VERSION ""

NS_ :

BS_:

BU_: TM

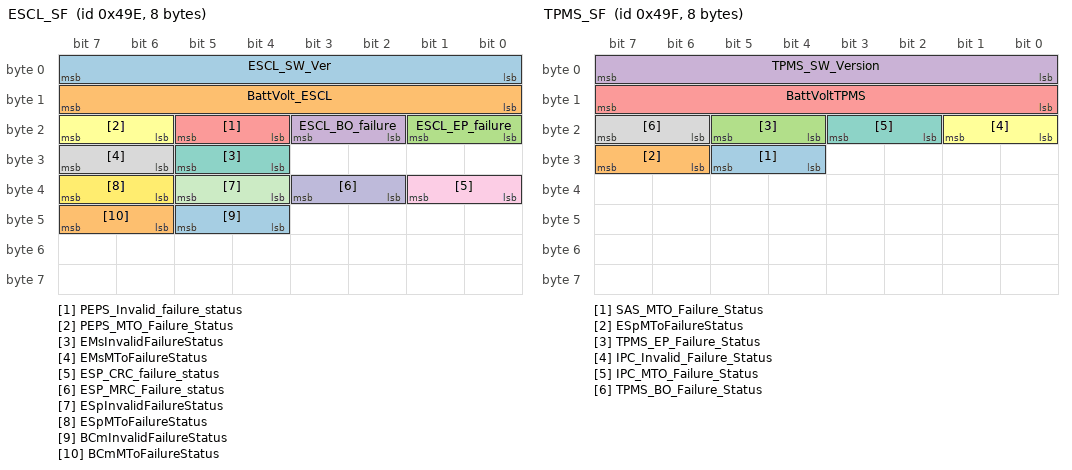
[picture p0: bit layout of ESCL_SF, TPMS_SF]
BO_ 1182 ESCL_SF: 8 Vector__XXX
 SG_ ESCL_SW_Ver : 7|8@0+ (1,0) [0|255] ""  TM
 SG_ BattVolt_ESCL : 15|8@0+ (0.1,0) [0|25] "Volts"  TM
 SG_ ESCL_EP_failure : 17|2@0+ (1,0) [0|3] ""  TM
 SG_ ESCL_BO_failure : 19|2@0+ (1,0) [0|3] ""  TM
 SG_ PEPS_Invalid_failure_status : 21|2@0+ (1,0) [0|3] ""  TM
 SG_ PEPS_MTO_Failure_Status : 23|2@0+ (1,0) [0|3] ""  TM
 SG_ EMsInvalidFailureStatus : 29|2@0+ (1,0) [0|3] ""  TM
 SG_ EMsMToFailureStatus : 31|2@0+ (1,0) [0|3] ""  TM
 SG_ ESP_CRC_failure_status : 33|2@0+ (1,0) [0|3] ""  TM
 SG_ ESP_MRC_Failure_status : 35|2@0+ (1,0) [0|3] ""  TM
 SG_ ESpInvalidFailureStatus : 37|2@0+ (1,0) [0|3] ""  TM
 SG_ ESpMToFailureStatus : 39|2@0+ (1,0) [0|3] ""  TM
 SG_ BCmInvalidFailureStatus : 45|2@0+ (1,0) [0|3] ""  TM
 SG_ BCmMToFailureStatus : 47|2@0+ (1,0) [0|3] ""  TM

BO_ 1183 TPMS_SF: 8 Vector__XXX
 SG_ SAS_MTO_Failure_Status : 29|2@0+ (1,0) [0|3] ""  TM
 SG_ ESpMToFailureStatus : 31|2@0+ (1,0) [0|3] ""  TM
 SG_ TPMS_EP_Failure_Status : 21|2@0+ (1,0) [0|3] ""  TM
 SG_ TPMS_SW_Version : 7|8@0+ (1,0) [0|255] ""  TM
 SG_ BattVoltTPMS : 15|8@0+ (0.1,0) [0|25.5] "Volts"  TM
 SG_ IPC_Invalid_Failure_Status : 17|2@0+ (1,0) [0|3] ""  TM
 SG_ IPC_MTO_Failure_Status : 19|2@0+ (1,0) [0|3] ""  TM
 SG_ TPMS_BO_Failure_Status : 23|2@0+ (1,0) [0|3] ""  TM

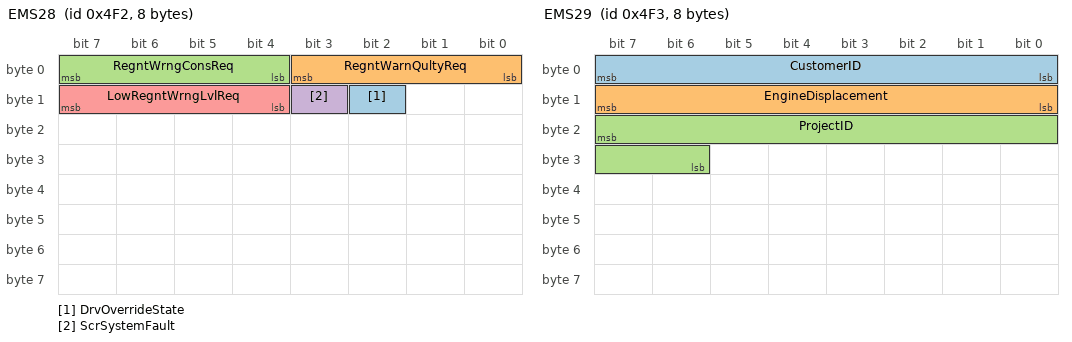
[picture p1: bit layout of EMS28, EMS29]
BO_ 1266 EMS28: 8 Vector__XXX
 SG_ DrvOverrideState : 10|1@0+ (1,0) [0|1] ""  TM
 SG_ RegntWarnQultyReq : 3|4@0+ (1,0) [0|15] ""  TM
 SG_ RegntWrngConsReq : 7|4@0+ (1,0) [0|15] ""  TM
 SG_ ScrSystemFault : 11|1@0+ (1,0) [0|1] ""  TM
 SG_ LowRegntWrngLvlReq : 15|4@0+ (1,0) [0|15] ""  TM

BO_ 1267 EMS29: 8 Vector__XXX
 SG_ CustomerID : 7|8@0+ (1,0) [0|255] ""  TM
 SG_ EngineDisplacement : 15|8@0+ (0.1,0) [0|25.5] ""  TM
 SG_ ProjectID : 23|10@0+ (0.01,0) [0|655.35] ""  TM

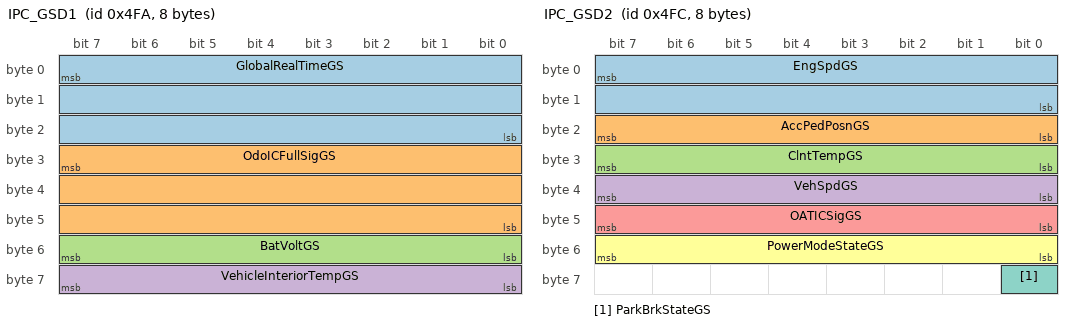
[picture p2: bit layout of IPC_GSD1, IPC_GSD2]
BO_ 1274 IPC_GSD1: 8 Vector__XXX
 SG_ GlobalRealTimeGS : 7|24@0+ (1,0) [0|16777214] "min"  TM
 SG_ OdoICFullSigGS : 31|24@0+ (1,0) [0|16777214] "km"  TM
 SG_ BatVoltGS : 55|8@0+ (0.1,0) [0|25.4] "V"  TM
 SG_ VehicleInteriorTempGS : 63|8@0+ (1,-40) [-40|214] "Deg"  TM

BO_ 1276 IPC_GSD2: 8 Vector__XXX
 SG_ EngSpdGS : 7|16@0+ (1,0) [0|65534] "rpm"  TM
 SG_ AccPedPosnGS : 23|8@0+ (0.5,0) [0|127] "%"  TM
 SG_ ClntTempGS : 31|8@0+ (1,-40) [-40|214] "Deg"  TM
 SG_ VehSpdGS : 39|8@0+ (1,0) [0|254] "km/h"  TM
 SG_ OATICSigGS : 47|8@0+ (1,-40) [-40|214] "Deg"  TM
 SG_ PowerModeStateGS : 55|8@0+ (1,0) [0|255] ""  TM
 SG_ ParkBrkStateGS : 56|1@0+ (1,0) [0|1] ""  TM

BO_ 1278 IPC_GSD3: 8 Vector__XXX
 SG_ VehIdetNumGS : 7|40@0+ (1,0) [0|0] ""  TM

BO_ 1280 BCM_NMPDU: 8 Vector__XXX
 SG_ BCM_NMPDU_SRC_ECU_ID : 7|8@0+ (1,0) [0|255] ""  TM
 SG_ RepeatMessageReq_BCM : 8|1@0+ (1,0) [0|1] ""  TM
 SG_ Reserved0 : 9|1@0+ (1,0) [0|1] ""  TM
 SG_ Reserved1 : 10|1@0+ (1,0) [0|1] ""  TM
 SG_ NMCoOrdSlpReady_BCM : 11|1@0+ (1,0) [0|1] ""  TM
 SG_ ActiveWakeUp_BCM : 12|1@0+ (1,0) [0|1] ""  TM
 SG_ Reserved2 : 13|1@0+ (1,0) [0|1] ""  TM
 SG_ PartialNetworkInformation_BCM : 14|1@0+ (1,0) [0|1] ""  TM
 SG_ Reserved3 : 15|1@0+ (1,0) [0|1] ""  TM
 SG_ CurrentState_BCM : 16|1@0+ (1,0) [0|1] ""  TM
 SG_ PreviousState_BCM : 19|3@0+ (1,0) [0|7] ""  TM
 SG_ Reserved4 : 20|1@0+ (1,0) [0|1] ""  TM
 SG_ Reserved5 : 21|1@0+ (1,0) [0|1] ""  TM
 SG_ Reserved6 : 22|1@0+ (1,0) [0|1] ""  TM
 SG_ Reserved7 : 23|1@0+ (1,0) [0|1] ""  TM
 SG_ BCM_NMPDU_USER_DATA_D1 : 31|8@0+ (1,0) [0|255] ""  TM
 SG_ BCM_NMPDU_USER_DATA_D2 : 39|8@0+ (1,0) [0|255] ""  TM
 SG_ BCM_NMPDU_USER_DATA_D3 : 47|8@0+ (1,0) [0|255] ""  TM
 SG_ BCM_NMPDU_USER_DATA_D4 : 55|8@0+ (1,0) [0|255] ""  TM
 SG_ BCM_NMPDU_USER_DATA_D5 : 63|8@0+ (1,0) [0|255] ""  TM

BO_ 1281 IPC_NMPDU: 8 Vector__XXX
 SG_ IPC_NMPDU_SRC_ECU_ID : 7|8@0+ (1,0) [0|255] ""  TM
 SG_ RepeatMessageReq_IPC : 8|1@0+ (1,0) [0|1] ""  TM
 SG_ Reserved24 : 9|1@0+ (1,0) [0|1] ""  TM
 SG_ Reserved25 : 10|1@0+ (1,0) [0|1] ""  TM
 SG_ NMCoOrdSlpReady_IPC : 11|1@0+ (1,0) [0|1] ""  TM
 SG_ ActiveWakeUp_IPC : 12|1@0+ (1,0) [0|1] ""  TM
 SG_ Reserved27 : 13|1@0+ (1,0) [0|1] ""  TM
 SG_ PartialNetworkInformation_IPC : 14|1@0+ (1,0) [0|1] ""  TM
 SG_ Reserved26 : 15|1@0+ (1,0) [0|1] ""  TM
 SG_ CurrentState_IPC : 16|1@0+ (1,0) [0|1] ""  TM
 SG_ PreviousState : 19|3@0+ (1,0) [0|7] ""  TM
 SG_ Reserved28 : 20|1@0+ (1,0) [0|1] ""  TM
 SG_ Reserved29 : 21|1@0+ (1,0) [0|1] ""  TM
 SG_ Reserved30 : 22|1@0+ (1,0) [0|1] ""  TM
 SG_ Reserved31 : 23|1@0+ (1,0) [0|1] ""  TM
 SG_ IPC_NMPDU_USER_DATA_1 : 31|8@0+ (1,0) [0|255] ""  TM
 SG_ IPC_NMPDU_USER_DATA_2 : 39|8@0+ (1,0) [0|255] ""  TM
 SG_ IPC_NMPDU_USER_DATA_3 : 47|8@0+ (1,0) [0|255] ""  TM
 SG_ IPC_NMPDU_USER_DATA_4 : 55|8@0+ (1,0) [0|255] ""  TM
 SG_ IPC_NMPDU_USER_DATA_5 : 63|8@0+ (1,0) [0|255] ""  TM

BO_ 1282 HU_NMPDU: 8 Vector__XXX
 SG_ HU_NMPDU_SRC_ECU_ID : 7|8@0+ (1,0) [0|255] ""  TM
 SG_ RepeatMessageReq_HU : 8|1@0+ (1,0) [0|1] ""  TM
 SG_ Reserved8 : 9|1@0+ (1,0) [0|1] ""  TM
 SG_ Reserved9 : 10|1@0+ (1,0) [0|1] ""  TM
 SG_ NMCoOrdSlpReady_HU : 11|1@0+ (1,0) [0|1] ""  TM
 SG_ ActiveWakeUp_HU : 12|1@0+ (1,0) [0|1] ""  TM
 SG_ Reserved10 : 13|1@0+ (1,0) [0|1] ""  TM
 SG_ PartialNetworkInformation_HU : 14|1@0+ (1,0) [0|1] ""  TM
 SG_ Reserved11 : 15|1@0+ (1,0) [0|1] ""  TM
 SG_ CurrentState_HU : 16|1@0+ (1,0) [0|1] ""  TM
 SG_ PreviousState_HU : 19|3@0+ (1,0) [0|7] ""  TM
 SG_ Reserved12 : 20|1@0+ (1,0) [0|1] ""  TM
 SG_ Reserved13 : 21|1@0+ (1,0) [0|1] ""  TM
 SG_ Reserved14 : 22|1@0+ (1,0) [0|1] ""  TM
 SG_ Reserved15 : 23|1@0+ (1,0) [0|1] ""  TM
 SG_ HU_NMPDU_USER_DATA_1 : 31|8@0+ (1,0) [0|255] ""  TM
 SG_ HU_NMPDU_USER_DATA_2 : 39|8@0+ (1,0) [0|255] ""  TM
 SG_ HU_NMPDU_USER_DATA_3 : 47|8@0+ (1,0) [0|255] ""  TM
 SG_ HU_NMPDU_USER_DATA_4 : 55|8@0+ (1,0) [0|255] ""  TM
 SG_ HU_NMPDU_USER_DATA_5 : 63|8@0+ (1,0) [0|255] ""  TM

BO_ 1285 GSS_NMPDU: 8 Vector__XXX
 SG_ GSS_NMPDU_SRC_ECU_ID : 7|8@0+ (1,0) [0|255] ""  TM
 SG_ RepeatMessageReq_GSS : 8|1@0+ (1,0) [0|1] ""  TM
 SG_ Reserved39 : 9|1@0+ (1,0) [0|1] ""  TM
 SG_ Reserved38 : 10|1@0+ (1,0) [0|1] ""  TM
 SG_ NMCoOrdSlpReady_GSS : 11|1@0+ (1,0) [0|1] ""  TM
 SG_ ActiveWakeUp_GSS : 12|1@0+ (1,0) [0|1] ""  TM
 SG_ Reserved37 : 13|1@0+ (1,0) [0|1] ""  TM
 SG_ PartialNetworkInformation_GSS : 14|1@0+ (1,0) [0|1] ""  TM
 SG_ Reserved36 : 15|1@0+ (1,0) [0|1] ""  TM
 SG_ CurrentState_GSS : 16|1@0+ (1,0) [0|1] ""  TM
 SG_ PreviousState_GSS : 19|3@0+ (1,0) [0|7] ""  TM
 SG_ Reserved35 : 20|1@0+ (1,0) [0|1] ""  TM
 SG_ Reserved34 : 21|1@0+ (1,0) [0|1] ""  TM
 SG_ Reserved33 : 22|1@0+ (1,0) [0|1] ""  TM
 SG_ Reserved32 : 23|1@0+ (1,0) [0|1] ""  TM
 SG_ GSS_NMPDU_USER_DATA_D1 : 31|8@0+ (1,0) [0|255] ""  TM
 SG_ GSS_NMPDU_USER_DATA_D2 : 39|8@0+ (1,0) [0|255] ""  TM
 SG_ GSS_NMPDU_USER_DATA_D3 : 47|8@0+ (1,0) [0|255] ""  TM
 SG_ GSS_NMPDU_USER_DATA_D4 : 55|8@0+ (1,0) [0|255] ""  TM
 SG_ GSS_NMPDU_USER_DATA_D5 : 63|8@0+ (1,0) [0|255] ""  TM

BO_ 1286 CCM_NMPDU: 8 Vector__XXX
 SG_ CCM_NMPDU_SRC_ECU_ID : 7|8@0+ (1,0) [0|255] ""  TM
 SG_ RepeatMessageReq_CCM : 8|1@0+ (1,0) [0|1] ""  TM
 SG_ Reserved16 : 9|1@0+ (1,0) [0|1] ""  TM
 SG_ Reserved17 : 10|1@0+ (1,0) [0|1] ""  TM
 SG_ NMCoOrdSlpReady_CCM : 11|1@0+ (1,0) [0|1] ""  TM
 SG_ ActiveWakeUp_CCM : 12|1@0+ (1,0) [0|1] ""  TM
 SG_ Reserved18 : 13|1@0+ (1,0) [0|1] ""  TM
 SG_ PartialNetworkInformation_CCM : 14|1@0+ (1,0) [0|1] ""  TM
 SG_ Reserved19 : 15|1@0+ (1,0) [0|1] ""  TM
 SG_ CurrentState_CCM : 16|1@0+ (1,0) [0|1] ""  TM
 SG_ PreviousState_CCM : 19|3@0+ (1,0) [0|7] ""  TM
 SG_ Reserved20 : 20|1@0+ (1,0) [0|1] ""  TM
 SG_ Reserved21 : 21|1@0+ (1,0) [0|1] ""  TM
 SG_ Reserved22 : 22|1@0+ (1,0) [0|1] ""  TM
 SG_ Reserved23 : 23|1@0+ (1,0) [0|1] ""  TM
 SG_ CCM_NMPDU_USER_DATA_1 : 31|8@0+ (1,0) [0|255] ""  TM
 SG_ CCM_NMPDU_USER_DATA_2 : 39|8@0+ (1,0) [0|255] ""  TM
 SG_ CCM_NMPDU_USER_DATA_3 : 47|8@0+ (1,0) [0|255] ""  TM
 SG_ CCM_NMPDU_USER_DATA_4 : 55|8@0+ (1,0) [0|255] ""  TM
 SG_ CCM_NMPDU_USER_DATA_5 : 63|8@0+ (1,0) [0|255] ""  TM

BO_ 1312 MANDO_SA_RX_0_MSG: 8 Vector__XXX
 SG_ MANDO_Steering_Analyzer_Rx0 : 7|64@0+ (1,0) [0|1.8446744074E+019] ""  TM

BO_ 1313 MANDO_SA_TX_0_MSG: 8 Vector__XXX
 SG_ MANDO_Steering_Analyzer_Tx0 : 7|64@0+ (1,0) [0|1.8446744074E+019] ""  TM

BO_ 1314 MANDO_SA_RX_1_MSG: 8 Vector__XXX
 SG_ MANDO_Steering_Analyzer_Rx1 : 7|64@0+ (1,0) [0|1.8446744074E+019] ""  TM

BO_ 1315 MANDO_SA_TX_1_MSG: 8 Vector__XXX
 SG_ MANDO_Steering_Analyzer_Tx1 : 7|64@0+ (1,0) [0|1.8446744074E+019] ""  TM

BO_ 1316 MANDO_SA_RX_2_MSG: 8 Vector__XXX
 SG_ MANDO_Steering_Analyzer_Rx2 : 7|64@0+ (1,0) [0|1.8446744074E+019] ""  TM

BO_ 1317 MANDO_SA_TX_2_MSG: 8 Vector__XXX
 SG_ MANDO_Steering_Analyzer_Tx2 : 7|64@0+ (1,0) [0|1.8446744074E+019] ""  TM

BO_ 1318 MANDO_SA_RX_3_MSG: 8 Vector__XXX
 SG_ MANDO_Steering_Analyzer_Rx3 : 7|64@0+ (1,0) [0|1.8446744074E+019] ""  TM

BO_ 1319 MANDO_SA_TX_3_MSG: 8 Vector__XXX
 SG_ MANDO_Steering_Analyzer_Tx3 : 7|64@0+ (1,0) [0|1.8446744074E+019] ""  TM

BO_ 1320 MANDO_SA_RX_4_MSG: 8 Vector__XXX
 SG_ MANDO_Steering_Analyzer_Rx4 : 7|64@0+ (1,0) [0|1.8446744074E+019] ""  TM

BO_ 1321 MANDO_SA_TX_4_MSG: 8 Vector__XXX
 SG_ MANDO_Steering_Analyzer_Tx4 : 7|64@0+ (1,0) [0|1.8446744074E+019] ""  TM

BO_ 1322 MANDO_TUNING_RX_MSG: 8 Vector__XXX
 SG_ MANDO_TUNING_RX : 7|64@0+ (1,0) [0|1.8446744074E+019] ""  TM

BO_ 1323 MANDO_TUNING_TX_MSG: 8 Vector__XXX
 SG_ MANDO_TUNING_TX : 7|64@0+ (1,0) [0|1.8446744074E+019] ""  TM

BO_ 1360 CCM_XCP_Tx: 8 Vector__XXX
 SG_ CCM_XCP_Tx : 7|64@0+ (1,0) [0|0] ""  TM

BO_ 1361 CCM_XCP_Rx: 8 Vector__XXX
 SG_ CCM_XCP_Rx : 7|64@0+ (1,0) [0|0] ""  TM

BO_ 1362 EPAS_XCP_RX_MSG: 8 Vector__XXX
 SG_ EPAS_XCP_RX : 7|64@0+ (1,0) [0|1.8446744074E+019] ""  TM

BO_ 1363 EPAS_XCP_TX_MSG: 8 Vector__XXX
 SG_ EPAS_XCP_TX : 7|64@0+ (1,0) [0|1.8446744074E+019] ""  TM

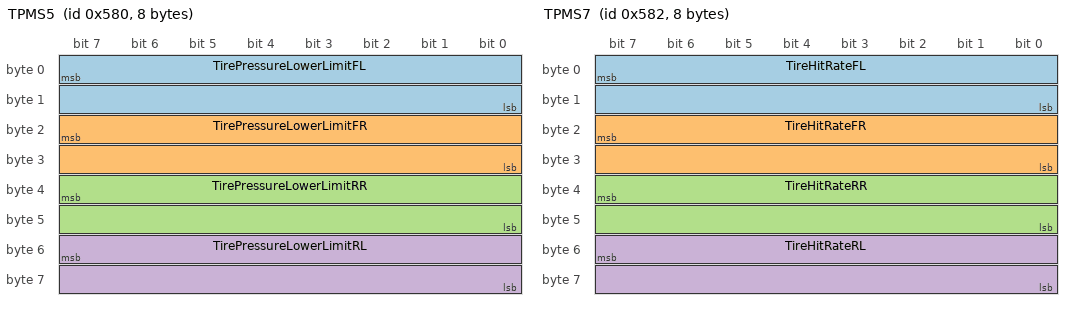
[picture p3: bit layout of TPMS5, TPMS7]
BO_ 1408 TPMS5: 8 Vector__XXX
 SG_ TirePressureLowerLimitFL : 7|16@0+ (0.01,0) [0|655.35] "Psi"  TM
 SG_ TirePressureLowerLimitFR : 23|16@0+ (0.01,0) [0|655.35] "Psi"  TM
 SG_ TirePressureLowerLimitRR : 39|16@0+ (0.01,0) [0|655.35] "Psi"  TM
 SG_ TirePressureLowerLimitRL : 55|16@0+ (0.01,0) [0|655.35] "Psi"  TM

BO_ 1409 TPMS6: 8 Vector__XXX
 SG_ TirePressureLowerLimitSpare : 7|16@0+ (0.01,0) [0|655.35] "Psi"  TM

BO_ 1410 TPMS7: 8 Vector__XXX
 SG_ TireHitRateFL : 7|16@0+ (1,0) [0|65535] "Count"  TM
 SG_ TireHitRateFR : 23|16@0+ (1,0) [0|65535] "Count"  TM
 SG_ TireHitRateRR : 39|16@0+ (1,0) [0|65535] "Count"  TM
 SG_ TireHitRateRL : 55|16@0+ (1,0) [0|65535] "Count"  TM

BO_ 1411 TPMS8: 8 Vector__XXX
 SG_ TireHitRateSpare : 7|16@0+ (1,0) [0|65535] "Count"  TM

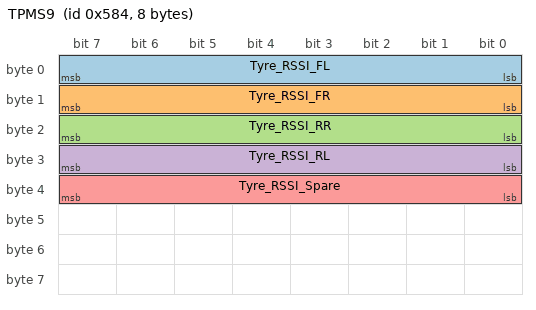
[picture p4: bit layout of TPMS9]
BO_ 1412 TPMS9: 8 Vector__XXX
 SG_ Tyre_RSSI_FL : 7|8@0+ (1,0) [0|255] "Count"  TM
 SG_ Tyre_RSSI_FR : 15|8@0+ (1,0) [0|255] "Count"  TM
 SG_ Tyre_RSSI_RR : 23|8@0+ (1,0) [0|255] "Count"  TM
 SG_ Tyre_RSSI_RL : 31|8@0+ (1,0) [0|255] "Count"  TM
 SG_ Tyre_RSSI_Spare : 39|8@0+ (1,0) [0|255] "Count"  TM

BO_ 1536 DebugOutput1: 8 Vector__XXX
 SG_ DebugOutput1 : 7|64@0+ (1,0) [0|0] ""  TM

BO_ 1537 DebugOutput2: 8 Vector__XXX
 SG_ DebugOutput2 : 7|64@0+ (1,0) [0|0] ""  TM

BO_ 1538 DebugOutput3: 8 Vector__XXX
 SG_ DebugOutput3 : 7|64@0+ (1,0) [0|0] ""  TM

BO_ 1539 DebugOutput4: 8 Vector__XXX
 SG_ DebugOutput4 : 7|64@0+ (1,0) [0|0] ""  TM

BO_ 1540 DebugOutput5: 8 Vector__XXX
 SG_ DebugOutput5 : 7|64@0+ (1,0) [0|0] ""  TM

BO_ 1541 DebugOutput6: 8 Vector__XXX
 SG_ DebugOutput6 : 7|64@0+ (1,0) [0|0] ""  TM

BO_ 1542 DebugOutput7: 8 Vector__XXX
 SG_ DebugOutput7 : 7|64@0+ (1,0) [0|0] ""  TM

BO_ 1543 DebugOutput8: 8 Vector__XXX
 SG_ DebugOutput8 : 7|64@0+ (1,0) [0|0] ""  TM

BO_ 1544 Debug_Input: 8 Vector__XXX
 SG_ DebugInput : 7|64@0+ (1,0) [0|0] ""  TM

BO_ 1545 BCM_DiagResponse_UUDT: 8 Vector__XXX
 SG_ BCM_DiagResponse_UUDT : 7|64@0+ (1,0) [0|0] ""  TM

BO_ 1546 SRS_DiagResponse_UUDT: 8 Vector__XXX
 SG_ SRS_DiagResponse_UUDT : 7|64@0+ (1,0) [0|0] ""  TM

BO_ 1547 HU_DiagResponse_UUDT: 8 Vector__XXX
 SG_ HU_DiagResponse_UUDT : 7|64@0+ (1,0) [0|0] ""  TM

BO_ 1548 VICM_DiagResponse_UUDT: 8 Vector__XXX
 SG_ VICM_DiagResponse_UUDT : 7|64@0+ (1,0) [0|0] ""  TM

BO_ 1549 CCM_DiagResponse_UUDT: 8 Vector__XXX
 SG_ CCM_DiagResponse_UUDT : 7|64@0+ (1,0) [0|0] ""  TM

BO_ 1560 PEPS_DiagResponse_UUDT: 8 Vector__XXX
 SG_ PEPS_DiagResponse_UUDT : 7|64@0+ (1,0) [0|0] ""  TM

BO_ 1564 PDC_DiagResponse_UUDT: 8 Vector__XXX
 SG_ PDC_DiagResponse_UUDT : 7|64@0+ (1,0) [0|0] ""  TM

BO_ 1624 ESP_DiagResponse_UUDT: 8 Vector__XXX
 SG_ ESP_DiagResponse_UUDT : 7|64@0+ (1,0) [0|0] ""  TM

BO_ 1626 EPAS_DiagResponse_UUDT: 8 Vector__XXX
 SG_ EPAS_DiagResponse_UUDT : 7|64@0+ (1,0) [0|0] ""  TM

BO_ 1669 DCS_DebugOutput1: 8 Vector__XXX
 SG_ DCS_DebugOutput1 : 7|64@0+ (1,0) [0|0] ""  TM

BO_ 1670 DCS_DebugInput: 8 Vector__XXX
 SG_ DCS_DebugInput : 7|64@0+ (1,0) [0|0] ""  TM

BO_ 1671 DCS_DebugOutput2: 8 Vector__XXX
 SG_ DCS_DebugOutput2 : 7|64@0+ (1,0) [0|0] ""  TM

BO_ 1768 EMS_DiagResponse_UUDT: 8 Vector__XXX
 SG_ EMS_DiagResponse_UUDT : 7|64@0+ (1,0) [0|0] ""  TM

BO_ 1769 TCM_DiagResponse_UUDT: 8 Vector__XXX
 SG_ AMT_DCT_DiagResponse_UUDT : 7|64@0+ (1,0) [0|0] ""  TM

BO_ 1793 BCM_DiagRequest: 8 Vector__XXX
 SG_ BCM_DiagRequest : 7|64@0+ (1,0) [0|0] ""  TM

BO_ 1794 SRS_DiagRequest: 8 Vector__XXX
 SG_ SRS_DiagRequest : 7|64@0+ (1,0) [0|0] ""  TM

BO_ 1795 HU_DiagRequest: 8 Vector__XXX
 SG_ DiagMsg : 7|8@0+ (1,0) [0|255] ""  TM

BO_ 1796 VICM_DiagRequest: 8 Vector__XXX
 SG_ VICM_DiagRequest : 7|64@0+ (1,0) [0|0] ""  TM

BO_ 1797 CCM_DiagRequest: 8 Vector__XXX
 SG_ CCM_DiagRequest : 7|64@0+ (1,0) [0|0] ""  TM

BO_ 1801 BCM_DiagResponse_USDT: 8 Vector__XXX
 SG_ BCM_DiagResponse_USDT : 7|64@0+ (1,0) [0|0] ""  TM

BO_ 1802 SRS_DiagResponse_USDT: 8 Vector__XXX
 SG_ SRS_DiagResponse_USDT : 7|64@0+ (1,0) [0|0] ""  TM

BO_ 1803 HU_DiagResponse_USDT: 8 Vector__XXX
 SG_ HU_DiagResponse_USDT : 7|64@0+ (1,0) [0|0] ""  TM

BO_ 1804 VICM_DiagResponse_USDT: 8 Vector__XXX
 SG_ VICM_DiagResponse_USDT : 7|64@0+ (1,0) [0|0] ""  TM

BO_ 1805 CCM_DiagResponse_USDT: 8 Vector__XXX
 SG_ CCM_DiagResponse_USDT : 7|64@0+ (1,0) [0|0] ""  TM

BO_ 1808 PEPS_DiagRequest_USDT: 8 Vector__XXX
 SG_ PEPS_DiagRequest_USDT : 7|64@0+ (1,0) [0|0] ""  TM

BO_ 1812 PDC_DiagRequest: 8 Vector__XXX
 SG_ PDC_DiagRequest : 7|64@0+ (1,0) [0|0] ""  TM

BO_ 1816 PEPS_DiagResponse_USDT: 8 Vector__XXX
 SG_ PEPS_DiagResponse_USDT : 7|64@0+ (1,0) [0|0] ""  TM

BO_ 1820 PDC_DiagResponse_USDT: 8 Vector__XXX
 SG_ PDC_DiagResponse_USDT : 7|64@0+ (1,0) [0|0] ""  TM

BO_ 1872 ESP_DiagRequest: 8 Vector__XXX
 SG_ ESP_DiagRequest : 7|64@0+ (1,0) [0|0] ""  TM

BO_ 1874 EPAS_DiagRequest: 8 Vector__XXX
 SG_ EPAS_DiagRequest : 7|64@0+ (1,0) [0|0] ""  TM

BO_ 1876 ESCL_DiagRequest: 8 Vector__XXX
 SG_ ESCL_DiagRequest : 7|64@0+ (1,0) [0|0] ""  TM

BO_ 1880 ESP_DiagResponse_USDT: 8 Vector__XXX
 SG_ ESP_DiagResponse_USDT : 7|64@0+ (1,0) [0|0] ""  TM

BO_ 1882 EPAS_DiagResponse_USDT: 8 Vector__XXX
 SG_ EPAS_DiagResponse_USDT : 7|64@0+ (1,0) [0|0] ""  TM

BO_ 1884 ESCL_DiagResponse_USDT: 8 Vector__XXX
 SG_ ESCL_DiagResponse_USDT : 7|64@0+ (1,0) [0|0] ""  TM

BO_ 2000 DiagState1: 8 Vector__XXX
 SG_ DiagMsg : 7|8@0+ (1,0) [0|255] ""  TM

BO_ 2001 DiagState2: 8 Vector__XXX
 SG_ DiagMsg : 7|8@0+ (1,0) [0|255] ""  TM

BO_ 2015 DiagState3: 8 Vector__XXX
 SG_ DiagMsg : 7|8@0+ (1,0) [0|255] ""  TM

BO_ 2016 EMS_DiagRequest: 8 Vector__XXX
 SG_ EMS_DiagRequest : 7|64@0+ (1,0) [0|0] ""  TM

BO_ 2017 TCM_DiagRequest: 8 Vector__XXX
 SG_ AMT_DCT_DiagRequest : 7|64@0+ (1,0) [0|0] ""  TM

BO_ 2024 EMS_DiagResponse_USDT: 8 Vector__XXX
 SG_ EMS_DiagResponse_USDT : 7|64@0+ (1,0) [0|0] ""  TM

BO_ 2025 TCM_DiagResponse_USDT: 8 Vector__XXX
 SG_ AMT_DCT_DiagResponse_USDT : 7|64@0+ (1,0) [0|0] ""  TM

CM_ SG_ 1182 BattVolt_ESCL "Battery voltage evaluated by ESCL";
CM_ SG_ 1182 PEPS_Invalid_failure_status "Status of the PEPS invalid failure detected as per Tata-IVN_Specification_Network_Management.";
CM_ SG_ 1182 PEPS_MTO_Failure_Status "Status of the PEPS  Message timeout  failure detected as per Tata-IVN_Specification_Network_Management.";
CM_ SG_ 1182 EMsInvalidFailureStatus "status of the EMS Invalid  signal  failure detected as per Tata-IVN_Specification_Network_Management.";
CM_ SG_ 1182 EMsMToFailureStatus "Status of the EMS message timeout failure detected as per Tata-IVN_Specification_Network_Management.";
CM_ SG_ 1182 ESpInvalidFailureStatus "Status of the ESP signal implausible  failure detected  by EPAS  as per  communication layer spec";
CM_ SG_ 1182 ESpMToFailureStatus "Status of the ESP  Message timeout failure detected as per Tata-IVN_Specification_Network_Management.";
CM_ SG_ 1182 BCmMToFailureStatus "Status of the BCM Message timeout  failure detected as per Tata-IVN_Specification_Network_Management.";
CM_ BO_ 1183 "SuperVision Frame";
CM_ SG_ 1183 SAS_MTO_Failure_Status "Status of the SAS  Message timeout  failure detected as per Tata-IVN_Specification_Network_Management.";
CM_ SG_ 1183 ESpMToFailureStatus "Status of the ESP  Message timeout failure detected as per Tata-IVN_Specification_Network_Management.";
CM_ SG_ 1183 TPMS_EP_Failure_Status "Status of the error-passive failure detected by BCM ECU as per Tata-IVN_Specification_Network_Management.  ";
CM_ SG_ 1183 TPMS_SW_Version "SW version of BCM ECU.  ";
CM_ SG_ 1183 BattVoltTPMS "Battery voltage evaluated by TPMS.";
CM_ SG_ 1183 IPC_Invalid_Failure_Status "Status of the IC Invalid  signal  failure detected as per Tata-IVN_Specification_Network_Management.";
CM_ SG_ 1183 IPC_MTO_Failure_Status "Status of the IPC Message Timeout  failure detected as per Tata-IVN_Specification_Network_Management.";
CM_ SG_ 1183 TPMS_BO_Failure_Status "Status of the bus-off failure detected by BCM ECU as per Tata-IVN_Specification_Network_Management.";
CM_ SG_ 1266 DrvOverrideState "this signal is set to Active only when the so-called OVERRIDE condition occurs";
CM_ SG_ 1266 RegntWarnQultyReq "CAN message is used to dispay text information qulity level of  reagent on IPC";
CM_ SG_ 1266 RegntWrngConsReq "CAN message is used to dispay text information excess consumption level of  reagent on IPC";
CM_ SG_ 1266 ScrSystemFault "CAN message used to understand status of SCR system";
CM_ SG_ 1266 LowRegntWrngLvlReq "CAN message is used to dispay text information Reagent level information";
CM_ SG_ 1267 CustomerID "if the TCU is connected to the correct EMS in the vehicle, the TCU will do a compatibility check in reference with Customer ID";
CM_ SG_ 1267 EngineDisplacement "if the TCU is connected to the correct EMS in the vehicle, the TCU will do a compatibility check in reference with Customer ID";
CM_ SG_ 1267 ProjectID "if the TCU is connected to the correct EMS in the vehicle, the TCU will do a compatibility check in reference with Project ID";
CM_ SG_ 1274 GlobalRealTimeGS "Global Real Time
";
CM_ SG_ 1274 OdoICFullSigGS "Total Distance Travelled";
CM_ SG_ 1274 BatVoltGS "Supply Voltage of Instrument Cluster";
CM_ SG_ 1274 VehicleInteriorTempGS "Vehicle Interior Temperature
";
CM_ SG_ 1276 EngSpdGS "Engine RPM signal will be transmitted by EMS
";
CM_ SG_ 1276 AccPedPosnGS "Throttle Position";
CM_ SG_ 1276 ClntTempGS "Engine Coolant Temperature";
CM_ SG_ 1276 VehSpdGS "Vehicle Speed";
CM_ SG_ 1276 OATICSigGS "Ambient Air Temperature";
CM_ SG_ 1276 PowerModeStateGS "Vehicle power mode signal shall be used by all ECUs of the vehicle for their respective functional implementation";
CM_ SG_ 1276 ParkBrkStateGS "Signal represents Status of ParkBrake";
CM_ SG_ 1278 VehIdetNumGS "Vehicle Identification Number - Last 5 digits of VIN";
CM_ BO_ 1360 "Calibration msg for HVAC";
CM_ SG_ 1360 CCM_XCP_Tx "CCM Calibration signal";
CM_ BO_ 1361 "Calibration msg for HVAC";
CM_ SG_ 1361 CCM_XCP_Rx "CCM Calibration signal";
CM_ BO_ 1408 "TPMS Test Msg";
CM_ SG_ 1408 TirePressureLowerLimitFL "Tire Pressure Lower Limit Front Left";
CM_ SG_ 1408 TirePressureLowerLimitFR "Tire Pressure Lower Limit Front Right";
CM_ SG_ 1408 TirePressureLowerLimitRR "Tire Pressure Lower Limit Rear Right";
CM_ SG_ 1408 TirePressureLowerLimitRL "Tire Pressure Lower Limit Rear Left";
CM_ BO_ 1409 "TPMS Test Msg";
CM_ SG_ 1409 TirePressureLowerLimitSpare "Tire Pressure Lower Limit Spare";
CM_ BO_ 1410 "TPMS Test Msg";
CM_ SG_ 1410 TireHitRateFL "Tire Hit Rate Front Left";
CM_ SG_ 1410 TireHitRateFR "Tire Hit Rate Front Right";
CM_ SG_ 1410 TireHitRateRR "Tire Hit Rate Rear Right";
CM_ SG_ 1410 TireHitRateRL "Tire Hit Rate Rear Left";
CM_ BO_ 1411 "TPMS Test Msg";
CM_ SG_ 1411 TireHitRateSpare "Tire Hit Rate Spare";
CM_ BO_ 1412 "TPMS Test Msg";
CM_ SG_ 1412 Tyre_RSSI_FL "Tire RSSI Level Front Left";
CM_ SG_ 1412 Tyre_RSSI_FR "'Tire RSSI Level Front Right";
CM_ SG_ 1412 Tyre_RSSI_RR "Tire RSSI Level Rear Right";
CM_ SG_ 1412 Tyre_RSSI_RL "Tire RSSI Level Rear Left";
CM_ SG_ 1412 Tyre_RSSI_Spare "Tire RSSI Level Spare";
CM_ BO_ 1669 "DCS Debug Output Message";
CM_ BO_ 1670 "DCS Debug Input";
CM_ BO_ 1671 "DCS Debug Output Message";
BA_DEF_ SG_  "Remarks" STRING ;
BA_DEF_ SG_  "NWM_WakeupAllowed" ENUM  "No","Yes";
BA_DEF_ SG_  "GenSigTimeoutTime_HU_Mid_X451" INT 0 65535;
BA_DEF_ SG_  "GenSigTimeoutTime_HU_High_X451" INT 0 65535;
BA_DEF_ SG_  "GenSigTimeoutTime_HU_B" INT 0 65535;
BA_DEF_ SG_  "GenSigTimeoutTime_HU_A" INT 0 65535;
BA_DEF_ SG_  "GenSigTimeoutTime_BCM_Mid" INT 0 65535;
BA_DEF_ SG_  "GenSigTimeoutMsg_HU_Mid_X451" INT 0 65535;
BA_DEF_ SG_  "GenSigTimeoutMsg_HU_High_X451" INT 0 65535;
BA_DEF_ SG_  "GenSigTimeoutMsg_HU_B" INT 0 65535;
BA_DEF_ SG_  "GenSigTimeoutMsg_HU_A" INT 0 65535;
BA_DEF_ SG_  "GenSigStartValue" INT 0 0;
BA_DEF_ SG_  "GenSigSendType" ENUM  "Cyclic","OnWrite","OnWriteWithRepetition","OnChange","OnChangeWithRepetition","IfActive","IfActiveWithRepetition","NoSigSendType","NotUsed","NotUsed","NotUsed","NotUsed","NotUsed";
BA_DEF_ SG_  "GenSigInactiveValue" INT 0 0;
BA_DEF_ SG_  "GenSigEnvVarType" ENUM  "int","float","undef";
BA_DEF_ SG_  "GenSigCycleTimeActive" INT 0 0;
BA_DEF_ SG_  "GenSigCycleTime" INT 0 0;
BA_DEF_ SG_  "GenSigTimeoutMsg_HU_High_X445" INT 0 65535;
BA_DEF_ SG_  "GenSigTimeoutMsg_HU_Mid_X445" INT 0 65535;
BA_DEF_ SG_  "GenSigTimeoutTime_HU_High_X445" INT 0 65535;
BA_DEF_ SG_  "GenSigTimeoutTime_HU_Mid_X445" INT 0 65535;
BA_DEF_ SG_  "GenSigTimeoutMsg_IVI" INT 0 65535;
BA_DEF_ SG_  "GenSigTimeoutTime_IVI" INT 0 65535;
BA_DEF_ BO_  "NmMessage" ENUM  "no","yes";
BA_DEF_ BO_  "NmAsrMessage" ENUM  "<n.a.>","No","Yes";
BA_DEF_ BO_  "MessageTimeout" INT 0 65535;
BA_DEF_ BO_  "Me" INT 0 0;
BA_DEF_ BO_  "GenMsgStartDelayTime" INT 0 0;
BA_DEF_ BO_  "GenMsgSendType" ENUM  "Cyclic","NotUsed","NotUsed","NotUsed","NotUsed","NotUsed","NotUsed","IfActive","NoMsgSendType","NotUsed";
BA_DEF_ BO_  "GenMsgNrOfRepetition" INT 0 0;
BA_DEF_ BO_  "GenMsgILSupport" ENUM  "No","Yes";
BA_DEF_ BO_  "GenMsgDelayTime" INT 0 0;
BA_DEF_ BO_  "GenMsgCycleTimeFast" INT 0 0;
BA_DEF_ BO_  "GenMsgCycleTime" INT 0 0;
BA_DEF_ BO_  "DiagUudtResponse" ENUM  "false","true";
BA_DEF_ BO_  "DiagUsdtResponse" ENUM  "false","true";
BA_DEF_ BO_  "DiagState" ENUM  "No","Yes";
BA_DEF_ BO_  "DiagResponse" ENUM  "No","Yes";
BA_DEF_ BO_  "DiagRequest" ENUM  "No","Yes";
BA_DEF_ BO_  "MsgType" ENUM  "Application","NM","NMH";
BA_DEF_ SG_  "SystemSignalLongSymbol" STRING ;
BA_DEF_DEF_  "Remarks" "null";
BA_DEF_DEF_  "NWM_WakeupAllowed" "No";
BA_DEF_DEF_  "GenSigTimeoutTime_HU_Mid_X451" 500;
BA_DEF_DEF_  "GenSigTimeoutTime_HU_High_X451" 500;
BA_DEF_DEF_  "GenSigTimeoutTime_HU_B" 500;
BA_DEF_DEF_  "GenSigTimeoutTime_HU_A" 500;
BA_DEF_DEF_  "GenSigTimeoutTime_BCM_Mid" 0;
BA_DEF_DEF_  "GenSigTimeoutMsg_HU_Mid_X451" 500;
BA_DEF_DEF_  "GenSigTimeoutMsg_HU_High_X451" 500;
BA_DEF_DEF_  "GenSigTimeoutMsg_HU_B" 500;
BA_DEF_DEF_  "GenSigTimeoutMsg_HU_A" 500;
BA_DEF_DEF_  "GenSigStartValue" 0;
BA_DEF_DEF_  "GenSigSendType" "Cyclic";
BA_DEF_DEF_  "GenSigInactiveValue" 0;
BA_DEF_DEF_  "GenSigEnvVarType" "undef";
BA_DEF_DEF_  "GenSigCycleTimeActive" 0;
BA_DEF_DEF_  "GenSigCycleTime" 0;
BA_DEF_DEF_  "GenSigTimeoutMsg_HU_High_X445" 500;
BA_DEF_DEF_  "GenSigTimeoutMsg_HU_Mid_X445" 500;
BA_DEF_DEF_  "GenSigTimeoutTime_HU_High_X445" 500;
BA_DEF_DEF_  "GenSigTimeoutTime_HU_Mid_X445" 500;
BA_DEF_DEF_  "GenSigTimeoutMsg_IVI" 500;
BA_DEF_DEF_  "GenSigTimeoutTime_IVI" 500;
BA_DEF_DEF_  "NmMessage" "no";
BA_DEF_DEF_  "NmAsrMessage" "<n.a.>";
BA_DEF_DEF_  "MessageTimeout" 500;
BA_DEF_DEF_  "Me" 0;
BA_DEF_DEF_  "GenMsgStartDelayTime" 0;
BA_DEF_DEF_  "GenMsgSendType" "Cyclic";
BA_DEF_DEF_  "GenMsgNrOfRepetition" 0;
BA_DEF_DEF_  "GenMsgILSupport" "Yes";
BA_DEF_DEF_  "GenMsgDelayTime" 0;
BA_DEF_DEF_  "GenMsgCycleTimeFast" 0;
BA_DEF_DEF_  "GenMsgCycleTime" 0;
BA_DEF_DEF_  "DiagUudtResponse" "false";
BA_DEF_DEF_  "DiagUsdtResponse" "false";
BA_DEF_DEF_  "DiagState" "No";
BA_DEF_DEF_  "DiagResponse" "No";
BA_DEF_DEF_  "DiagRequest" "No";
BA_DEF_DEF_  "MsgType" "Application";
BA_DEF_DEF_  "SystemSignalLongSymbol" "";
BA_ "MessageTimeout" BO_ 1182 0;
BA_ "GenMsgCycleTime" BO_ 1182 100;
BA_ "MessageTimeout" BO_ 1183 0;
BA_ "GenMsgCycleTime" BO_ 1183 100;
BA_ "MessageTimeout" BO_ 1266 5000;
BA_ "GenMsgCycleTime" BO_ 1266 1000;
BA_ "MessageTimeout" BO_ 1267 5000;
BA_ "GenMsgCycleTime" BO_ 1267 1000;
BA_ "MessageTimeout" BO_ 1274 5000;
BA_ "GenMsgCycleTime" BO_ 1274 1000;
BA_ "MessageTimeout" BO_ 1276 5000;
BA_ "GenMsgStartDelayTime" BO_ 1276 45;
BA_ "GenMsgCycleTime" BO_ 1276 1000;
BA_ "MessageTimeout" BO_ 1278 5000;
BA_ "GenMsgCycleTime" BO_ 1278 1000;
BA_ "NmAsrMessage" BO_ 1280 2;
BA_ "MessageTimeout" BO_ 1280 1000;
BA_ "GenMsgCycleTime" BO_ 1280 200;
BA_ "MessageTimeout" BO_ 1281 1000;
BA_ "GenMsgCycleTime" BO_ 1281 200;
BA_ "NmAsrMessage" BO_ 1282 2;
BA_ "MessageTimeout" BO_ 1282 1000;
BA_ "GenMsgCycleTime" BO_ 1282 200;
BA_ "MessageTimeout" BO_ 1285 1000;
BA_ "GenMsgCycleTime" BO_ 1285 200;
BA_ "MessageTimeout" BO_ 1286 1000;
BA_ "GenMsgCycleTime" BO_ 1286 200;
BA_ "MessageTimeout" BO_ 1312 0;
BA_ "GenMsgSendType" BO_ 1312 8;
BA_ "MessageTimeout" BO_ 1313 0;
BA_ "GenMsgSendType" BO_ 1313 8;
BA_ "MessageTimeout" BO_ 1314 0;
BA_ "GenMsgSendType" BO_ 1314 8;
BA_ "MessageTimeout" BO_ 1315 0;
BA_ "GenMsgSendType" BO_ 1315 8;
BA_ "MessageTimeout" BO_ 1316 0;
BA_ "GenMsgSendType" BO_ 1316 8;
BA_ "MessageTimeout" BO_ 1317 0;
BA_ "GenMsgSendType" BO_ 1317 8;
BA_ "MessageTimeout" BO_ 1318 0;
BA_ "GenMsgSendType" BO_ 1318 8;
BA_ "MessageTimeout" BO_ 1319 0;
BA_ "GenMsgSendType" BO_ 1319 8;
BA_ "MessageTimeout" BO_ 1320 0;
BA_ "GenMsgSendType" BO_ 1320 8;
BA_ "MessageTimeout" BO_ 1321 0;
BA_ "GenMsgSendType" BO_ 1321 8;
BA_ "MessageTimeout" BO_ 1322 0;
BA_ "GenMsgSendType" BO_ 1322 8;
BA_ "MessageTimeout" BO_ 1323 0;
BA_ "GenMsgSendType" BO_ 1323 8;
BA_ "MessageTimeout" BO_ 1360 0;
BA_ "GenMsgSendType" BO_ 1360 8;
BA_ "MessageTimeout" BO_ 1361 0;
BA_ "GenMsgSendType" BO_ 1361 8;
BA_ "MessageTimeout" BO_ 1362 0;
BA_ "GenMsgSendType" BO_ 1362 8;
BA_ "MessageTimeout" BO_ 1363 0;
BA_ "GenMsgSendType" BO_ 1363 8;
BA_ "GenMsgCycleTime" BO_ 1408 100;
BA_ "GenMsgCycleTime" BO_ 1409 100;
BA_ "GenMsgCycleTime" BO_ 1410 100;
BA_ "GenMsgCycleTime" BO_ 1411 100;
BA_ "GenMsgCycleTime" BO_ 1412 100;
BA_ "MessageTimeout" BO_ 1536 0;
BA_ "GenMsgSendType" BO_ 1536 8;
BA_ "GenMsgNrOfRepetition" BO_ 1536 1;
BA_ "MessageTimeout" BO_ 1537 0;
BA_ "GenMsgSendType" BO_ 1537 8;
BA_ "MessageTimeout" BO_ 1538 0;
BA_ "GenMsgSendType" BO_ 1538 8;
BA_ "MessageTimeout" BO_ 1539 0;
BA_ "GenMsgSendType" BO_ 1539 8;
BA_ "MessageTimeout" BO_ 1540 0;
BA_ "GenMsgSendType" BO_ 1540 8;
BA_ "MessageTimeout" BO_ 1541 0;
BA_ "GenMsgSendType" BO_ 1541 8;
BA_ "MessageTimeout" BO_ 1542 0;
BA_ "GenMsgSendType" BO_ 1542 8;
BA_ "MessageTimeout" BO_ 1543 0;
BA_ "GenMsgSendType" BO_ 1543 8;
BA_ "MessageTimeout" BO_ 1544 0;
BA_ "GenMsgSendType" BO_ 1544 8;
BA_ "MessageTimeout" BO_ 1545 0;
BA_ "GenMsgSendType" BO_ 1545 8;
BA_ "GenMsgILSupport" BO_ 1545 0;
BA_ "DiagResponse" BO_ 1545 1;
BA_ "MessageTimeout" BO_ 1546 0;
BA_ "GenMsgSendType" BO_ 1546 8;
BA_ "GenMsgILSupport" BO_ 1546 0;
BA_ "DiagResponse" BO_ 1546 1;
BA_ "MessageTimeout" BO_ 1547 0;
BA_ "GenMsgSendType" BO_ 1547 8;
BA_ "GenMsgILSupport" BO_ 1547 0;
BA_ "DiagUudtResponse" BO_ 1547 1;
BA_ "DiagResponse" BO_ 1547 1;
BA_ "MessageTimeout" BO_ 1548 0;
BA_ "GenMsgSendType" BO_ 1548 8;
BA_ "GenMsgILSupport" BO_ 1548 0;
BA_ "DiagResponse" BO_ 1548 1;
BA_ "MessageTimeout" BO_ 1549 0;
BA_ "GenMsgSendType" BO_ 1549 8;
BA_ "GenMsgILSupport" BO_ 1549 0;
BA_ "DiagResponse" BO_ 1549 1;
BA_ "MessageTimeout" BO_ 1560 0;
BA_ "GenMsgSendType" BO_ 1560 8;
BA_ "GenMsgILSupport" BO_ 1560 0;
BA_ "DiagResponse" BO_ 1560 1;
BA_ "MessageTimeout" BO_ 1564 0;
BA_ "GenMsgSendType" BO_ 1564 8;
BA_ "GenMsgILSupport" BO_ 1564 0;
BA_ "DiagResponse" BO_ 1564 1;
BA_ "MessageTimeout" BO_ 1624 0;
BA_ "GenMsgSendType" BO_ 1624 8;
BA_ "GenMsgILSupport" BO_ 1624 0;
BA_ "DiagResponse" BO_ 1624 1;
BA_ "MessageTimeout" BO_ 1626 0;
BA_ "GenMsgSendType" BO_ 1626 8;
BA_ "GenMsgILSupport" BO_ 1626 0;
BA_ "DiagResponse" BO_ 1626 1;
BA_ "MessageTimeout" BO_ 1669 0;
BA_ "GenMsgSendType" BO_ 1669 8;
BA_ "MessageTimeout" BO_ 1670 0;
BA_ "GenMsgSendType" BO_ 1670 8;
BA_ "MessageTimeout" BO_ 1671 0;
BA_ "GenMsgSendType" BO_ 1671 8;
BA_ "MessageTimeout" BO_ 1768 0;
BA_ "GenMsgSendType" BO_ 1768 8;
BA_ "GenMsgILSupport" BO_ 1768 0;
BA_ "DiagResponse" BO_ 1768 1;
BA_ "MessageTimeout" BO_ 1769 0;
BA_ "GenMsgSendType" BO_ 1769 8;
BA_ "GenMsgILSupport" BO_ 1769 0;
BA_ "DiagResponse" BO_ 1769 1;
BA_ "MessageTimeout" BO_ 1793 0;
BA_ "GenMsgSendType" BO_ 1793 8;
BA_ "GenMsgILSupport" BO_ 1793 0;
BA_ "DiagRequest" BO_ 1793 1;
BA_ "MessageTimeout" BO_ 1794 0;
BA_ "GenMsgSendType" BO_ 1794 8;
BA_ "GenMsgILSupport" BO_ 1794 0;
BA_ "DiagRequest" BO_ 1794 1;
BA_ "MessageTimeout" BO_ 1795 0;
BA_ "GenMsgSendType" BO_ 1795 8;
BA_ "GenMsgILSupport" BO_ 1795 0;
BA_ "DiagRequest" BO_ 1795 1;
BA_ "MessageTimeout" BO_ 1796 0;
BA_ "GenMsgSendType" BO_ 1796 8;
BA_ "GenMsgILSupport" BO_ 1796 0;
BA_ "DiagRequest" BO_ 1796 1;
BA_ "MessageTimeout" BO_ 1797 0;
BA_ "GenMsgSendType" BO_ 1797 8;
BA_ "GenMsgILSupport" BO_ 1797 0;
BA_ "DiagRequest" BO_ 1797 1;
BA_ "MessageTimeout" BO_ 1801 0;
BA_ "GenMsgSendType" BO_ 1801 8;
BA_ "GenMsgILSupport" BO_ 1801 0;
BA_ "DiagResponse" BO_ 1801 1;
BA_ "MessageTimeout" BO_ 1802 0;
BA_ "GenMsgSendType" BO_ 1802 8;
BA_ "GenMsgILSupport" BO_ 1802 0;
BA_ "DiagResponse" BO_ 1802 1;
BA_ "MessageTimeout" BO_ 1803 0;
BA_ "GenMsgSendType" BO_ 1803 8;
BA_ "GenMsgILSupport" BO_ 1803 0;
BA_ "DiagResponse" BO_ 1803 1;
BA_ "MessageTimeout" BO_ 1804 0;
BA_ "GenMsgSendType" BO_ 1804 8;
BA_ "GenMsgILSupport" BO_ 1804 0;
BA_ "DiagResponse" BO_ 1804 1;
BA_ "MessageTimeout" BO_ 1805 0;
BA_ "GenMsgSendType" BO_ 1805 8;
BA_ "GenMsgILSupport" BO_ 1805 0;
BA_ "DiagResponse" BO_ 1805 1;
BA_ "MessageTimeout" BO_ 1808 0;
BA_ "GenMsgSendType" BO_ 1808 8;
BA_ "GenMsgILSupport" BO_ 1808 0;
BA_ "DiagRequest" BO_ 1808 1;
BA_ "MessageTimeout" BO_ 1812 0;
BA_ "GenMsgSendType" BO_ 1812 8;
BA_ "GenMsgILSupport" BO_ 1812 0;
BA_ "DiagRequest" BO_ 1812 1;
BA_ "MessageTimeout" BO_ 1816 0;
BA_ "GenMsgSendType" BO_ 1816 8;
BA_ "GenMsgILSupport" BO_ 1816 0;
BA_ "DiagResponse" BO_ 1816 1;
BA_ "MessageTimeout" BO_ 1820 0;
BA_ "GenMsgSendType" BO_ 1820 8;
BA_ "GenMsgILSupport" BO_ 1820 0;
BA_ "DiagResponse" BO_ 1820 1;
BA_ "MessageTimeout" BO_ 1872 0;
BA_ "GenMsgSendType" BO_ 1872 8;
BA_ "GenMsgILSupport" BO_ 1872 0;
BA_ "DiagRequest" BO_ 1872 1;
BA_ "MessageTimeout" BO_ 1874 0;
BA_ "GenMsgSendType" BO_ 1874 8;
BA_ "GenMsgILSupport" BO_ 1874 0;
BA_ "DiagRequest" BO_ 1874 1;
BA_ "MessageTimeout" BO_ 1876 0;
BA_ "GenMsgSendType" BO_ 1876 8;
BA_ "GenMsgILSupport" BO_ 1876 0;
BA_ "DiagRequest" BO_ 1876 1;
BA_ "MessageTimeout" BO_ 1880 0;
BA_ "GenMsgSendType" BO_ 1880 8;
BA_ "GenMsgILSupport" BO_ 1880 0;
BA_ "DiagResponse" BO_ 1880 1;
BA_ "MessageTimeout" BO_ 1882 0;
BA_ "GenMsgSendType" BO_ 1882 8;
BA_ "GenMsgILSupport" BO_ 1882 0;
BA_ "DiagResponse" BO_ 1882 1;
BA_ "MessageTimeout" BO_ 1884 0;
BA_ "GenMsgSendType" BO_ 1884 8;
BA_ "GenMsgILSupport" BO_ 1884 0;
BA_ "DiagResponse" BO_ 1884 1;
BA_ "MessageTimeout" BO_ 2000 0;
BA_ "GenMsgSendType" BO_ 2000 8;
BA_ "GenMsgILSupport" BO_ 2000 0;
BA_ "DiagState" BO_ 2000 1;
BA_ "MessageTimeout" BO_ 2001 0;
BA_ "GenMsgSendType" BO_ 2001 8;
BA_ "GenMsgILSupport" BO_ 2001 0;
BA_ "DiagState" BO_ 2001 1;
BA_ "MessageTimeout" BO_ 2015 0;
BA_ "GenMsgSendType" BO_ 2015 8;
BA_ "GenMsgILSupport" BO_ 2015 0;
BA_ "DiagState" BO_ 2015 1;
BA_ "MessageTimeout" BO_ 2016 0;
BA_ "GenMsgSendType" BO_ 2016 8;
BA_ "GenMsgILSupport" BO_ 2016 0;
BA_ "DiagRequest" BO_ 2016 1;
BA_ "MessageTimeout" BO_ 2017 0;
BA_ "GenMsgSendType" BO_ 2017 8;
BA_ "GenMsgILSupport" BO_ 2017 0;
BA_ "DiagRequest" BO_ 2017 1;
BA_ "MessageTimeout" BO_ 2024 0;
BA_ "GenMsgSendType" BO_ 2024 8;
BA_ "GenMsgILSupport" BO_ 2024 0;
BA_ "DiagResponse" BO_ 2024 1;
BA_ "MessageTimeout" BO_ 2025 0;
BA_ "GenMsgSendType" BO_ 2025 8;
BA_ "GenMsgILSupport" BO_ 2025 0;
BA_ "DiagResponse" BO_ 2025 1;
BA_ "GenSigTimeoutTime_HU_B" SG_ 1182 ESCL_SW_Ver 0;
BA_ "GenSigTimeoutTime_HU_A" SG_ 1182 ESCL_SW_Ver 0;
BA_ "GenSigTimeoutMsg_HU_B" SG_ 1182 ESCL_SW_Ver 0;
BA_ "GenSigTimeoutMsg_HU_A" SG_ 1182 ESCL_SW_Ver 0;
BA_ "GenSigSendType" SG_ 1182 ESCL_SW_Ver 7;
BA_ "GenSigCycleTimeActive" SG_ 1182 ESCL_SW_Ver 100;
BA_ "GenSigCycleTime" SG_ 1182 ESCL_SW_Ver 100;
BA_ "GenSigTimeoutTime_HU_B" SG_ 1182 BattVolt_ESCL 0;
BA_ "GenSigTimeoutTime_HU_A" SG_ 1182 BattVolt_ESCL 0;
BA_ "GenSigTimeoutMsg_HU_B" SG_ 1182 BattVolt_ESCL 0;
BA_ "GenSigTimeoutMsg_HU_A" SG_ 1182 BattVolt_ESCL 0;
BA_ "GenSigSendType" SG_ 1182 BattVolt_ESCL 7;
BA_ "GenSigCycleTimeActive" SG_ 1182 BattVolt_ESCL 100;
BA_ "GenSigCycleTime" SG_ 1182 BattVolt_ESCL 100;
BA_ "GenSigTimeoutTime_HU_B" SG_ 1182 ESCL_EP_failure 0;
BA_ "GenSigTimeoutTime_HU_A" SG_ 1182 ESCL_EP_failure 0;
BA_ "GenSigTimeoutMsg_HU_B" SG_ 1182 ESCL_EP_failure 0;
BA_ "GenSigTimeoutMsg_HU_A" SG_ 1182 ESCL_EP_failure 0;
BA_ "GenSigSendType" SG_ 1182 ESCL_EP_failure 7;
BA_ "GenSigCycleTimeActive" SG_ 1182 ESCL_EP_failure 100;
BA_ "GenSigCycleTime" SG_ 1182 ESCL_EP_failure 100;
BA_ "GenSigTimeoutTime_HU_B" SG_ 1182 ESCL_BO_failure 0;
BA_ "GenSigTimeoutTime_HU_A" SG_ 1182 ESCL_BO_failure 0;
BA_ "GenSigTimeoutMsg_HU_B" SG_ 1182 ESCL_BO_failure 0;
BA_ "GenSigTimeoutMsg_HU_A" SG_ 1182 ESCL_BO_failure 0;
BA_ "GenSigSendType" SG_ 1182 ESCL_BO_failure 7;
BA_ "GenSigCycleTimeActive" SG_ 1182 ESCL_BO_failure 100;
BA_ "GenSigCycleTime" SG_ 1182 ESCL_BO_failure 100;
BA_ "GenSigTimeoutTime_HU_B" SG_ 1182 PEPS_Invalid_failure_status 0;
BA_ "GenSigTimeoutTime_HU_A" SG_ 1182 PEPS_Invalid_failure_status 0;
BA_ "GenSigTimeoutMsg_HU_B" SG_ 1182 PEPS_Invalid_failure_status 0;
BA_ "GenSigTimeoutMsg_HU_A" SG_ 1182 PEPS_Invalid_failure_status 0;
BA_ "GenSigSendType" SG_ 1182 PEPS_Invalid_failure_status 7;
BA_ "GenSigCycleTimeActive" SG_ 1182 PEPS_Invalid_failure_status 100;
BA_ "GenSigCycleTime" SG_ 1182 PEPS_Invalid_failure_status 100;
BA_ "GenSigTimeoutTime_HU_B" SG_ 1182 PEPS_MTO_Failure_Status 0;
BA_ "GenSigTimeoutTime_HU_A" SG_ 1182 PEPS_MTO_Failure_Status 0;
BA_ "GenSigTimeoutMsg_HU_B" SG_ 1182 PEPS_MTO_Failure_Status 0;
BA_ "GenSigTimeoutMsg_HU_A" SG_ 1182 PEPS_MTO_Failure_Status 0;
BA_ "GenSigSendType" SG_ 1182 PEPS_MTO_Failure_Status 7;
BA_ "GenSigCycleTimeActive" SG_ 1182 PEPS_MTO_Failure_Status 100;
BA_ "GenSigCycleTime" SG_ 1182 PEPS_MTO_Failure_Status 100;
BA_ "GenSigTimeoutTime_HU_B" SG_ 1182 EMsInvalidFailureStatus 0;
BA_ "GenSigTimeoutTime_HU_A" SG_ 1182 EMsInvalidFailureStatus 0;
BA_ "GenSigTimeoutMsg_HU_B" SG_ 1182 EMsInvalidFailureStatus 0;
BA_ "GenSigTimeoutMsg_HU_A" SG_ 1182 EMsInvalidFailureStatus 0;
BA_ "GenSigSendType" SG_ 1182 EMsInvalidFailureStatus 7;
BA_ "GenSigCycleTimeActive" SG_ 1182 EMsInvalidFailureStatus 100;
BA_ "GenSigCycleTime" SG_ 1182 EMsInvalidFailureStatus 100;
BA_ "GenSigTimeoutTime_HU_B" SG_ 1182 EMsMToFailureStatus 0;
BA_ "GenSigTimeoutTime_HU_A" SG_ 1182 EMsMToFailureStatus 0;
BA_ "GenSigTimeoutMsg_HU_B" SG_ 1182 EMsMToFailureStatus 0;
BA_ "GenSigTimeoutMsg_HU_A" SG_ 1182 EMsMToFailureStatus 0;
BA_ "GenSigSendType" SG_ 1182 EMsMToFailureStatus 7;
BA_ "GenSigCycleTimeActive" SG_ 1182 EMsMToFailureStatus 100;
BA_ "GenSigCycleTime" SG_ 1182 EMsMToFailureStatus 100;
BA_ "GenSigTimeoutTime_HU_B" SG_ 1182 ESP_CRC_failure_status 0;
BA_ "GenSigTimeoutTime_HU_A" SG_ 1182 ESP_CRC_failure_status 0;
BA_ "GenSigTimeoutMsg_HU_B" SG_ 1182 ESP_CRC_failure_status 0;
BA_ "GenSigTimeoutMsg_HU_A" SG_ 1182 ESP_CRC_failure_status 0;
BA_ "GenSigSendType" SG_ 1182 ESP_CRC_failure_status 7;
BA_ "GenSigCycleTimeActive" SG_ 1182 ESP_CRC_failure_status 100;
BA_ "GenSigCycleTime" SG_ 1182 ESP_CRC_failure_status 100;
BA_ "GenSigTimeoutTime_HU_B" SG_ 1182 ESP_MRC_Failure_status 0;
BA_ "GenSigTimeoutTime_HU_A" SG_ 1182 ESP_MRC_Failure_status 0;
BA_ "GenSigTimeoutMsg_HU_B" SG_ 1182 ESP_MRC_Failure_status 0;
BA_ "GenSigTimeoutMsg_HU_A" SG_ 1182 ESP_MRC_Failure_status 0;
BA_ "GenSigSendType" SG_ 1182 ESP_MRC_Failure_status 7;
BA_ "GenSigCycleTimeActive" SG_ 1182 ESP_MRC_Failure_status 100;
BA_ "GenSigCycleTime" SG_ 1182 ESP_MRC_Failure_status 100;
BA_ "GenSigTimeoutTime_HU_B" SG_ 1182 ESpInvalidFailureStatus 0;
BA_ "GenSigTimeoutTime_HU_A" SG_ 1182 ESpInvalidFailureStatus 0;
BA_ "GenSigTimeoutMsg_HU_B" SG_ 1182 ESpInvalidFailureStatus 0;
BA_ "GenSigTimeoutMsg_HU_A" SG_ 1182 ESpInvalidFailureStatus 0;
BA_ "GenSigSendType" SG_ 1182 ESpInvalidFailureStatus 7;
BA_ "GenSigCycleTimeActive" SG_ 1182 ESpInvalidFailureStatus 100;
BA_ "GenSigCycleTime" SG_ 1182 ESpInvalidFailureStatus 100;
BA_ "GenSigTimeoutTime_HU_B" SG_ 1182 ESpMToFailureStatus 0;
BA_ "GenSigTimeoutTime_HU_A" SG_ 1182 ESpMToFailureStatus 0;
BA_ "GenSigTimeoutMsg_HU_B" SG_ 1182 ESpMToFailureStatus 0;
BA_ "GenSigTimeoutMsg_HU_A" SG_ 1182 ESpMToFailureStatus 0;
BA_ "GenSigSendType" SG_ 1182 ESpMToFailureStatus 7;
BA_ "GenSigCycleTimeActive" SG_ 1182 ESpMToFailureStatus 100;
BA_ "GenSigCycleTime" SG_ 1182 ESpMToFailureStatus 100;
BA_ "GenSigTimeoutTime_HU_B" SG_ 1182 BCmInvalidFailureStatus 0;
BA_ "GenSigTimeoutTime_HU_A" SG_ 1182 BCmInvalidFailureStatus 0;
BA_ "GenSigTimeoutMsg_HU_B" SG_ 1182 BCmInvalidFailureStatus 0;
BA_ "GenSigTimeoutMsg_HU_A" SG_ 1182 BCmInvalidFailureStatus 0;
BA_ "GenSigSendType" SG_ 1182 BCmInvalidFailureStatus 7;
BA_ "GenSigCycleTimeActive" SG_ 1182 BCmInvalidFailureStatus 100;
BA_ "GenSigCycleTime" SG_ 1182 BCmInvalidFailureStatus 100;
BA_ "GenSigTimeoutTime_HU_B" SG_ 1182 BCmMToFailureStatus 0;
BA_ "GenSigTimeoutTime_HU_A" SG_ 1182 BCmMToFailureStatus 0;
BA_ "GenSigTimeoutMsg_HU_B" SG_ 1182 BCmMToFailureStatus 0;
BA_ "GenSigTimeoutMsg_HU_A" SG_ 1182 BCmMToFailureStatus 0;
BA_ "GenSigSendType" SG_ 1182 BCmMToFailureStatus 7;
BA_ "GenSigCycleTimeActive" SG_ 1182 BCmMToFailureStatus 100;
BA_ "GenSigCycleTime" SG_ 1182 BCmMToFailureStatus 100;
BA_ "GenSigTimeoutTime_HU_B" SG_ 1183 SAS_MTO_Failure_Status 0;
BA_ "GenSigTimeoutTime_HU_A" SG_ 1183 SAS_MTO_Failure_Status 0;
BA_ "GenSigTimeoutMsg_HU_B" SG_ 1183 SAS_MTO_Failure_Status 0;
BA_ "GenSigTimeoutMsg_HU_A" SG_ 1183 SAS_MTO_Failure_Status 0;
BA_ "GenSigSendType" SG_ 1183 SAS_MTO_Failure_Status 7;
BA_ "GenSigCycleTimeActive" SG_ 1183 SAS_MTO_Failure_Status 100;
BA_ "GenSigCycleTime" SG_ 1183 SAS_MTO_Failure_Status 100;
BA_ "GenSigTimeoutTime_HU_B" SG_ 1183 ESpMToFailureStatus 0;
BA_ "GenSigTimeoutTime_HU_A" SG_ 1183 ESpMToFailureStatus 0;
BA_ "GenSigTimeoutMsg_HU_B" SG_ 1183 ESpMToFailureStatus 0;
BA_ "GenSigTimeoutMsg_HU_A" SG_ 1183 ESpMToFailureStatus 0;
BA_ "GenSigSendType" SG_ 1183 ESpMToFailureStatus 7;
BA_ "GenSigCycleTimeActive" SG_ 1183 ESpMToFailureStatus 100;
BA_ "GenSigCycleTime" SG_ 1183 ESpMToFailureStatus 100;
BA_ "GenSigTimeoutTime_HU_B" SG_ 1183 TPMS_EP_Failure_Status 0;
BA_ "GenSigTimeoutTime_HU_A" SG_ 1183 TPMS_EP_Failure_Status 0;
BA_ "GenSigTimeoutMsg_HU_B" SG_ 1183 TPMS_EP_Failure_Status 0;
BA_ "GenSigTimeoutMsg_HU_A" SG_ 1183 TPMS_EP_Failure_Status 0;
BA_ "GenSigSendType" SG_ 1183 TPMS_EP_Failure_Status 7;
BA_ "GenSigCycleTimeActive" SG_ 1183 TPMS_EP_Failure_Status 100;
BA_ "GenSigCycleTime" SG_ 1183 TPMS_EP_Failure_Status 100;
BA_ "GenSigTimeoutTime_HU_B" SG_ 1183 TPMS_SW_Version 0;
BA_ "GenSigTimeoutTime_HU_A" SG_ 1183 TPMS_SW_Version 0;
BA_ "GenSigTimeoutMsg_HU_B" SG_ 1183 TPMS_SW_Version 0;
BA_ "GenSigTimeoutMsg_HU_A" SG_ 1183 TPMS_SW_Version 0;
BA_ "GenSigSendType" SG_ 1183 TPMS_SW_Version 7;
BA_ "GenSigCycleTimeActive" SG_ 1183 TPMS_SW_Version 100;
BA_ "GenSigCycleTime" SG_ 1183 TPMS_SW_Version 100;
BA_ "GenSigTimeoutTime_HU_B" SG_ 1183 BattVoltTPMS 0;
BA_ "GenSigTimeoutTime_HU_A" SG_ 1183 BattVoltTPMS 0;
BA_ "GenSigTimeoutMsg_HU_B" SG_ 1183 BattVoltTPMS 0;
BA_ "GenSigTimeoutMsg_HU_A" SG_ 1183 BattVoltTPMS 0;
BA_ "GenSigSendType" SG_ 1183 BattVoltTPMS 7;
BA_ "GenSigCycleTimeActive" SG_ 1183 BattVoltTPMS 100;
BA_ "GenSigCycleTime" SG_ 1183 BattVoltTPMS 100;
BA_ "GenSigTimeoutTime_HU_B" SG_ 1183 IPC_Invalid_Failure_Status 0;
BA_ "GenSigTimeoutTime_HU_A" SG_ 1183 IPC_Invalid_Failure_Status 0;
BA_ "GenSigTimeoutMsg_HU_B" SG_ 1183 IPC_Invalid_Failure_Status 0;
BA_ "GenSigTimeoutMsg_HU_A" SG_ 1183 IPC_Invalid_Failure_Status 0;
BA_ "GenSigSendType" SG_ 1183 IPC_Invalid_Failure_Status 7;
BA_ "GenSigCycleTimeActive" SG_ 1183 IPC_Invalid_Failure_Status 100;
BA_ "GenSigCycleTime" SG_ 1183 IPC_Invalid_Failure_Status 100;
BA_ "GenSigTimeoutTime_HU_B" SG_ 1183 IPC_MTO_Failure_Status 0;
BA_ "GenSigTimeoutTime_HU_A" SG_ 1183 IPC_MTO_Failure_Status 0;
BA_ "GenSigTimeoutMsg_HU_B" SG_ 1183 IPC_MTO_Failure_Status 0;
BA_ "GenSigTimeoutMsg_HU_A" SG_ 1183 IPC_MTO_Failure_Status 0;
BA_ "GenSigSendType" SG_ 1183 IPC_MTO_Failure_Status 7;
BA_ "GenSigCycleTimeActive" SG_ 1183 IPC_MTO_Failure_Status 100;
BA_ "GenSigCycleTime" SG_ 1183 IPC_MTO_Failure_Status 100;
BA_ "GenSigTimeoutTime_HU_B" SG_ 1183 TPMS_BO_Failure_Status 0;
BA_ "GenSigTimeoutTime_HU_A" SG_ 1183 TPMS_BO_Failure_Status 0;
BA_ "GenSigTimeoutMsg_HU_B" SG_ 1183 TPMS_BO_Failure_Status 0;
BA_ "GenSigTimeoutMsg_HU_A" SG_ 1183 TPMS_BO_Failure_Status 0;
BA_ "GenSigSendType" SG_ 1183 TPMS_BO_Failure_Status 7;
BA_ "GenSigCycleTimeActive" SG_ 1183 TPMS_BO_Failure_Status 100;
BA_ "GenSigCycleTime" SG_ 1183 TPMS_BO_Failure_Status 100;
BA_ "GenSigTimeoutTime_HU_Mid_X451" SG_ 1266 DrvOverrideState 5000;
BA_ "GenSigTimeoutTime_HU_High_X451" SG_ 1266 DrvOverrideState 5000;
BA_ "GenSigTimeoutTime_HU_B" SG_ 1266 DrvOverrideState 5000;
BA_ "GenSigTimeoutTime_HU_A" SG_ 1266 DrvOverrideState 5000;
BA_ "GenSigTimeoutMsg_HU_Mid_X451" SG_ 1266 DrvOverrideState 5000;
BA_ "GenSigTimeoutMsg_HU_High_X451" SG_ 1266 DrvOverrideState 5000;
BA_ "GenSigTimeoutMsg_HU_B" SG_ 1266 DrvOverrideState 5000;
BA_ "GenSigTimeoutMsg_HU_A" SG_ 1266 DrvOverrideState 5000;
BA_ "GenSigSendType" SG_ 1266 DrvOverrideState 7;
BA_ "GenSigCycleTimeActive" SG_ 1266 DrvOverrideState 1000;
BA_ "GenSigCycleTime" SG_ 1266 DrvOverrideState 1000;
BA_ "GenSigTimeoutMsg_HU_High_X445" SG_ 1266 DrvOverrideState 5000;
BA_ "GenSigTimeoutMsg_HU_Mid_X445" SG_ 1266 DrvOverrideState 5000;
BA_ "GenSigTimeoutTime_HU_High_X445" SG_ 1266 DrvOverrideState 5000;
BA_ "GenSigTimeoutTime_HU_Mid_X445" SG_ 1266 DrvOverrideState 5000;
BA_ "GenSigTimeoutMsg_IVI" SG_ 1266 DrvOverrideState 5000;
BA_ "GenSigTimeoutTime_IVI" SG_ 1266 DrvOverrideState 5000;
BA_ "GenSigTimeoutTime_HU_Mid_X451" SG_ 1266 RegntWarnQultyReq 5000;
BA_ "GenSigTimeoutTime_HU_High_X451" SG_ 1266 RegntWarnQultyReq 5000;
BA_ "GenSigTimeoutTime_HU_B" SG_ 1266 RegntWarnQultyReq 5000;
BA_ "GenSigTimeoutTime_HU_A" SG_ 1266 RegntWarnQultyReq 5000;
BA_ "GenSigTimeoutMsg_HU_Mid_X451" SG_ 1266 RegntWarnQultyReq 5000;
BA_ "GenSigTimeoutMsg_HU_High_X451" SG_ 1266 RegntWarnQultyReq 5000;
BA_ "GenSigTimeoutMsg_HU_B" SG_ 1266 RegntWarnQultyReq 5000;
BA_ "GenSigTimeoutMsg_HU_A" SG_ 1266 RegntWarnQultyReq 5000;
BA_ "GenSigStartValue" SG_ 1266 RegntWarnQultyReq 15;
BA_ "GenSigSendType" SG_ 1266 RegntWarnQultyReq 7;
BA_ "GenSigCycleTimeActive" SG_ 1266 RegntWarnQultyReq 1000;
BA_ "GenSigCycleTime" SG_ 1266 RegntWarnQultyReq 1000;
BA_ "GenSigTimeoutMsg_HU_High_X445" SG_ 1266 RegntWarnQultyReq 5000;
BA_ "GenSigTimeoutMsg_HU_Mid_X445" SG_ 1266 RegntWarnQultyReq 5000;
BA_ "GenSigTimeoutTime_HU_High_X445" SG_ 1266 RegntWarnQultyReq 5000;
BA_ "GenSigTimeoutTime_HU_Mid_X445" SG_ 1266 RegntWarnQultyReq 5000;
BA_ "GenSigTimeoutMsg_IVI" SG_ 1266 RegntWarnQultyReq 5000;
BA_ "GenSigTimeoutTime_IVI" SG_ 1266 RegntWarnQultyReq 5000;
BA_ "GenSigTimeoutTime_HU_Mid_X451" SG_ 1266 RegntWrngConsReq 5000;
BA_ "GenSigTimeoutTime_HU_High_X451" SG_ 1266 RegntWrngConsReq 5000;
BA_ "GenSigTimeoutTime_HU_B" SG_ 1266 RegntWrngConsReq 5000;
BA_ "GenSigTimeoutTime_HU_A" SG_ 1266 RegntWrngConsReq 5000;
BA_ "GenSigTimeoutMsg_HU_Mid_X451" SG_ 1266 RegntWrngConsReq 5000;
BA_ "GenSigTimeoutMsg_HU_High_X451" SG_ 1266 RegntWrngConsReq 5000;
BA_ "GenSigTimeoutMsg_HU_B" SG_ 1266 RegntWrngConsReq 5000;
BA_ "GenSigTimeoutMsg_HU_A" SG_ 1266 RegntWrngConsReq 5000;
BA_ "GenSigStartValue" SG_ 1266 RegntWrngConsReq 15;
BA_ "GenSigSendType" SG_ 1266 RegntWrngConsReq 7;
BA_ "GenSigCycleTimeActive" SG_ 1266 RegntWrngConsReq 1000;
BA_ "GenSigCycleTime" SG_ 1266 RegntWrngConsReq 1000;
BA_ "GenSigTimeoutMsg_HU_High_X445" SG_ 1266 RegntWrngConsReq 5000;
BA_ "GenSigTimeoutMsg_HU_Mid_X445" SG_ 1266 RegntWrngConsReq 5000;
BA_ "GenSigTimeoutTime_HU_High_X445" SG_ 1266 RegntWrngConsReq 5000;
BA_ "GenSigTimeoutTime_HU_Mid_X445" SG_ 1266 RegntWrngConsReq 5000;
BA_ "GenSigTimeoutMsg_IVI" SG_ 1266 RegntWrngConsReq 5000;
BA_ "GenSigTimeoutTime_IVI" SG_ 1266 RegntWrngConsReq 5000;
BA_ "GenSigTimeoutTime_HU_Mid_X451" SG_ 1266 ScrSystemFault 5000;
BA_ "GenSigTimeoutTime_HU_High_X451" SG_ 1266 ScrSystemFault 5000;
BA_ "GenSigTimeoutTime_HU_B" SG_ 1266 ScrSystemFault 5000;
BA_ "GenSigTimeoutTime_HU_A" SG_ 1266 ScrSystemFault 5000;
BA_ "GenSigTimeoutMsg_HU_Mid_X451" SG_ 1266 ScrSystemFault 5000;
BA_ "GenSigTimeoutMsg_HU_High_X451" SG_ 1266 ScrSystemFault 5000;
BA_ "GenSigTimeoutMsg_HU_B" SG_ 1266 ScrSystemFault 5000;
BA_ "GenSigTimeoutMsg_HU_A" SG_ 1266 ScrSystemFault 5000;
BA_ "GenSigSendType" SG_ 1266 ScrSystemFault 7;
BA_ "GenSigCycleTimeActive" SG_ 1266 ScrSystemFault 1000;
BA_ "GenSigCycleTime" SG_ 1266 ScrSystemFault 1000;
BA_ "GenSigTimeoutMsg_HU_High_X445" SG_ 1266 ScrSystemFault 5000;
BA_ "GenSigTimeoutMsg_HU_Mid_X445" SG_ 1266 ScrSystemFault 5000;
BA_ "GenSigTimeoutTime_HU_High_X445" SG_ 1266 ScrSystemFault 5000;
BA_ "GenSigTimeoutTime_HU_Mid_X445" SG_ 1266 ScrSystemFault 5000;
BA_ "GenSigTimeoutMsg_IVI" SG_ 1266 ScrSystemFault 5000;
BA_ "GenSigTimeoutTime_IVI" SG_ 1266 ScrSystemFault 5000;
BA_ "GenSigTimeoutTime_HU_Mid_X451" SG_ 1266 LowRegntWrngLvlReq 5000;
BA_ "GenSigTimeoutTime_HU_High_X451" SG_ 1266 LowRegntWrngLvlReq 5000;
BA_ "GenSigTimeoutTime_HU_B" SG_ 1266 LowRegntWrngLvlReq 5000;
BA_ "GenSigTimeoutTime_HU_A" SG_ 1266 LowRegntWrngLvlReq 5000;
BA_ "GenSigTimeoutMsg_HU_Mid_X451" SG_ 1266 LowRegntWrngLvlReq 5000;
BA_ "GenSigTimeoutMsg_HU_High_X451" SG_ 1266 LowRegntWrngLvlReq 5000;
BA_ "GenSigTimeoutMsg_HU_B" SG_ 1266 LowRegntWrngLvlReq 5000;
BA_ "GenSigTimeoutMsg_HU_A" SG_ 1266 LowRegntWrngLvlReq 5000;
BA_ "GenSigStartValue" SG_ 1266 LowRegntWrngLvlReq 15;
BA_ "GenSigSendType" SG_ 1266 LowRegntWrngLvlReq 7;
BA_ "GenSigCycleTimeActive" SG_ 1266 LowRegntWrngLvlReq 1000;
BA_ "GenSigCycleTime" SG_ 1266 LowRegntWrngLvlReq 1000;
BA_ "GenSigTimeoutMsg_HU_High_X445" SG_ 1266 LowRegntWrngLvlReq 5000;
BA_ "GenSigTimeoutMsg_HU_Mid_X445" SG_ 1266 LowRegntWrngLvlReq 5000;
BA_ "GenSigTimeoutTime_HU_High_X445" SG_ 1266 LowRegntWrngLvlReq 5000;
BA_ "GenSigTimeoutTime_HU_Mid_X445" SG_ 1266 LowRegntWrngLvlReq 5000;
BA_ "GenSigTimeoutMsg_IVI" SG_ 1266 LowRegntWrngLvlReq 5000;
BA_ "GenSigTimeoutTime_IVI" SG_ 1266 LowRegntWrngLvlReq 5000;
BA_ "GenSigTimeoutTime_HU_Mid_X451" SG_ 1267 CustomerID 5000;
BA_ "GenSigTimeoutTime_HU_High_X451" SG_ 1267 CustomerID 5000;
BA_ "GenSigTimeoutTime_HU_B" SG_ 1267 CustomerID 5000;
BA_ "GenSigTimeoutTime_HU_A" SG_ 1267 CustomerID 5000;
BA_ "GenSigTimeoutMsg_HU_Mid_X451" SG_ 1267 CustomerID 5000;
BA_ "GenSigTimeoutMsg_HU_High_X451" SG_ 1267 CustomerID 5000;
BA_ "GenSigTimeoutMsg_HU_B" SG_ 1267 CustomerID 5000;
BA_ "GenSigTimeoutMsg_HU_A" SG_ 1267 CustomerID 5000;
BA_ "GenSigSendType" SG_ 1267 CustomerID 7;
BA_ "GenSigCycleTimeActive" SG_ 1267 CustomerID 1000;
BA_ "GenSigCycleTime" SG_ 1267 CustomerID 1000;
BA_ "GenSigTimeoutTime_HU_Mid_X451" SG_ 1267 EngineDisplacement 5000;
BA_ "GenSigTimeoutTime_HU_High_X451" SG_ 1267 EngineDisplacement 5000;
BA_ "GenSigTimeoutTime_HU_B" SG_ 1267 EngineDisplacement 5000;
BA_ "GenSigTimeoutTime_HU_A" SG_ 1267 EngineDisplacement 5000;
BA_ "GenSigTimeoutMsg_HU_Mid_X451" SG_ 1267 EngineDisplacement 5000;
BA_ "GenSigTimeoutMsg_HU_High_X451" SG_ 1267 EngineDisplacement 5000;
BA_ "GenSigTimeoutMsg_HU_B" SG_ 1267 EngineDisplacement 5000;
BA_ "GenSigTimeoutMsg_HU_A" SG_ 1267 EngineDisplacement 5000;
BA_ "GenSigSendType" SG_ 1267 EngineDisplacement 7;
BA_ "GenSigCycleTimeActive" SG_ 1267 EngineDisplacement 1000;
BA_ "GenSigCycleTime" SG_ 1267 EngineDisplacement 1000;
BA_ "GenSigTimeoutTime_HU_Mid_X451" SG_ 1267 ProjectID 5000;
BA_ "GenSigTimeoutTime_HU_High_X451" SG_ 1267 ProjectID 5000;
BA_ "GenSigTimeoutTime_HU_B" SG_ 1267 ProjectID 5000;
BA_ "GenSigTimeoutTime_HU_A" SG_ 1267 ProjectID 5000;
BA_ "GenSigTimeoutMsg_HU_Mid_X451" SG_ 1267 ProjectID 5000;
BA_ "GenSigTimeoutMsg_HU_High_X451" SG_ 1267 ProjectID 5000;
BA_ "GenSigTimeoutMsg_HU_B" SG_ 1267 ProjectID 5000;
BA_ "GenSigTimeoutMsg_HU_A" SG_ 1267 ProjectID 5000;
BA_ "GenSigSendType" SG_ 1267 ProjectID 7;
BA_ "GenSigCycleTimeActive" SG_ 1267 ProjectID 1000;
BA_ "GenSigCycleTime" SG_ 1267 ProjectID 1000;
BA_ "GenSigTimeoutTime_HU_Mid_X451" SG_ 1274 GlobalRealTimeGS 5000;
BA_ "GenSigTimeoutTime_HU_High_X451" SG_ 1274 GlobalRealTimeGS 5000;
BA_ "GenSigTimeoutTime_HU_B" SG_ 1274 GlobalRealTimeGS 5000;
BA_ "GenSigTimeoutTime_HU_A" SG_ 1274 GlobalRealTimeGS 5000;
BA_ "GenSigTimeoutMsg_HU_Mid_X451" SG_ 1274 GlobalRealTimeGS 5000;
BA_ "GenSigTimeoutMsg_HU_High_X451" SG_ 1274 GlobalRealTimeGS 5000;
BA_ "GenSigTimeoutMsg_HU_B" SG_ 1274 GlobalRealTimeGS 5000;
BA_ "GenSigTimeoutMsg_HU_A" SG_ 1274 GlobalRealTimeGS 5000;
BA_ "GenSigSendType" SG_ 1274 GlobalRealTimeGS 7;
BA_ "GenSigCycleTimeActive" SG_ 1274 GlobalRealTimeGS 1000;
BA_ "GenSigCycleTime" SG_ 1274 GlobalRealTimeGS 1000;
BA_ "GenSigTimeoutMsg_HU_High_X445" SG_ 1274 GlobalRealTimeGS 5000;
BA_ "GenSigTimeoutMsg_HU_Mid_X445" SG_ 1274 GlobalRealTimeGS 5000;
BA_ "GenSigTimeoutTime_HU_High_X445" SG_ 1274 GlobalRealTimeGS 5000;
BA_ "GenSigTimeoutTime_HU_Mid_X445" SG_ 1274 GlobalRealTimeGS 5000;
BA_ "GenSigTimeoutMsg_IVI" SG_ 1274 GlobalRealTimeGS 5000;
BA_ "GenSigTimeoutTime_IVI" SG_ 1274 GlobalRealTimeGS 5000;
BA_ "GenSigTimeoutTime_HU_Mid_X451" SG_ 1274 OdoICFullSigGS 5000;
BA_ "GenSigTimeoutTime_HU_High_X451" SG_ 1274 OdoICFullSigGS 5000;
BA_ "GenSigTimeoutTime_HU_B" SG_ 1274 OdoICFullSigGS 5000;
BA_ "GenSigTimeoutTime_HU_A" SG_ 1274 OdoICFullSigGS 5000;
BA_ "GenSigTimeoutMsg_HU_Mid_X451" SG_ 1274 OdoICFullSigGS 5000;
BA_ "GenSigTimeoutMsg_HU_High_X451" SG_ 1274 OdoICFullSigGS 5000;
BA_ "GenSigTimeoutMsg_HU_B" SG_ 1274 OdoICFullSigGS 5000;
BA_ "GenSigTimeoutMsg_HU_A" SG_ 1274 OdoICFullSigGS 5000;
BA_ "GenSigSendType" SG_ 1274 OdoICFullSigGS 7;
BA_ "GenSigCycleTimeActive" SG_ 1274 OdoICFullSigGS 1000;
BA_ "GenSigCycleTime" SG_ 1274 OdoICFullSigGS 1000;
BA_ "GenSigTimeoutMsg_HU_High_X445" SG_ 1274 OdoICFullSigGS 5000;
BA_ "GenSigTimeoutMsg_HU_Mid_X445" SG_ 1274 OdoICFullSigGS 5000;
BA_ "GenSigTimeoutTime_HU_High_X445" SG_ 1274 OdoICFullSigGS 5000;
BA_ "GenSigTimeoutTime_HU_Mid_X445" SG_ 1274 OdoICFullSigGS 5000;
BA_ "GenSigTimeoutMsg_IVI" SG_ 1274 OdoICFullSigGS 5000;
BA_ "GenSigTimeoutTime_IVI" SG_ 1274 OdoICFullSigGS 5000;
BA_ "GenSigTimeoutTime_HU_Mid_X451" SG_ 1274 BatVoltGS 5000;
BA_ "GenSigTimeoutTime_HU_High_X451" SG_ 1274 BatVoltGS 5000;
BA_ "GenSigTimeoutTime_HU_B" SG_ 1274 BatVoltGS 5000;
BA_ "GenSigTimeoutTime_HU_A" SG_ 1274 BatVoltGS 5000;
BA_ "GenSigTimeoutMsg_HU_Mid_X451" SG_ 1274 BatVoltGS 5000;
BA_ "GenSigTimeoutMsg_HU_High_X451" SG_ 1274 BatVoltGS 5000;
BA_ "GenSigTimeoutMsg_HU_B" SG_ 1274 BatVoltGS 5000;
BA_ "GenSigTimeoutMsg_HU_A" SG_ 1274 BatVoltGS 5000;
BA_ "GenSigSendType" SG_ 1274 BatVoltGS 7;
BA_ "GenSigCycleTimeActive" SG_ 1274 BatVoltGS 1000;
BA_ "GenSigCycleTime" SG_ 1274 BatVoltGS 1000;
BA_ "GenSigTimeoutMsg_HU_High_X445" SG_ 1274 BatVoltGS 5000;
BA_ "GenSigTimeoutMsg_HU_Mid_X445" SG_ 1274 BatVoltGS 5000;
BA_ "GenSigTimeoutTime_HU_High_X445" SG_ 1274 BatVoltGS 5000;
BA_ "GenSigTimeoutTime_HU_Mid_X445" SG_ 1274 BatVoltGS 5000;
BA_ "GenSigTimeoutMsg_IVI" SG_ 1274 BatVoltGS 5000;
BA_ "GenSigTimeoutTime_IVI" SG_ 1274 BatVoltGS 5000;
BA_ "GenSigTimeoutTime_HU_Mid_X451" SG_ 1274 VehicleInteriorTempGS 5000;
BA_ "GenSigTimeoutTime_HU_High_X451" SG_ 1274 VehicleInteriorTempGS 5000;
BA_ "GenSigTimeoutTime_HU_B" SG_ 1274 VehicleInteriorTempGS 5000;
BA_ "GenSigTimeoutTime_HU_A" SG_ 1274 VehicleInteriorTempGS 5000;
BA_ "GenSigTimeoutMsg_HU_Mid_X451" SG_ 1274 VehicleInteriorTempGS 5000;
BA_ "GenSigTimeoutMsg_HU_High_X451" SG_ 1274 VehicleInteriorTempGS 5000;
BA_ "GenSigTimeoutMsg_HU_B" SG_ 1274 VehicleInteriorTempGS 5000;
BA_ "GenSigTimeoutMsg_HU_A" SG_ 1274 VehicleInteriorTempGS 5000;
BA_ "GenSigStartValue" SG_ 1274 VehicleInteriorTempGS 40;
BA_ "GenSigSendType" SG_ 1274 VehicleInteriorTempGS 7;
BA_ "GenSigCycleTimeActive" SG_ 1274 VehicleInteriorTempGS 1000;
BA_ "GenSigCycleTime" SG_ 1274 VehicleInteriorTempGS 1000;
BA_ "GenSigTimeoutMsg_HU_High_X445" SG_ 1274 VehicleInteriorTempGS 5000;
BA_ "GenSigTimeoutMsg_HU_Mid_X445" SG_ 1274 VehicleInteriorTempGS 5000;
BA_ "GenSigTimeoutTime_HU_High_X445" SG_ 1274 VehicleInteriorTempGS 5000;
BA_ "GenSigTimeoutTime_HU_Mid_X445" SG_ 1274 VehicleInteriorTempGS 5000;
BA_ "GenSigTimeoutMsg_IVI" SG_ 1274 VehicleInteriorTempGS 5000;
BA_ "GenSigTimeoutTime_IVI" SG_ 1274 VehicleInteriorTempGS 5000;
BA_ "GenSigTimeoutTime_HU_Mid_X451" SG_ 1276 EngSpdGS 5000;
BA_ "GenSigTimeoutTime_HU_High_X451" SG_ 1276 EngSpdGS 5000;
BA_ "GenSigTimeoutTime_HU_B" SG_ 1276 EngSpdGS 5000;
BA_ "GenSigTimeoutTime_HU_A" SG_ 1276 EngSpdGS 5000;
BA_ "GenSigTimeoutMsg_HU_Mid_X451" SG_ 1276 EngSpdGS 5000;
BA_ "GenSigTimeoutMsg_HU_High_X451" SG_ 1276 EngSpdGS 5000;
BA_ "GenSigTimeoutMsg_HU_B" SG_ 1276 EngSpdGS 5000;
BA_ "GenSigTimeoutMsg_HU_A" SG_ 1276 EngSpdGS 5000;
BA_ "GenSigSendType" SG_ 1276 EngSpdGS 7;
BA_ "GenSigCycleTimeActive" SG_ 1276 EngSpdGS 1000;
BA_ "GenSigCycleTime" SG_ 1276 EngSpdGS 1000;
BA_ "GenSigTimeoutMsg_HU_High_X445" SG_ 1276 EngSpdGS 5000;
BA_ "GenSigTimeoutMsg_HU_Mid_X445" SG_ 1276 EngSpdGS 5000;
BA_ "GenSigTimeoutTime_HU_High_X445" SG_ 1276 EngSpdGS 5000;
BA_ "GenSigTimeoutTime_HU_Mid_X445" SG_ 1276 EngSpdGS 5000;
BA_ "GenSigTimeoutMsg_IVI" SG_ 1276 EngSpdGS 5000;
BA_ "GenSigTimeoutTime_IVI" SG_ 1276 EngSpdGS 5000;
BA_ "GenSigTimeoutTime_HU_Mid_X451" SG_ 1276 AccPedPosnGS 5000;
BA_ "GenSigTimeoutTime_HU_High_X451" SG_ 1276 AccPedPosnGS 5000;
BA_ "GenSigTimeoutTime_HU_B" SG_ 1276 AccPedPosnGS 5000;
BA_ "GenSigTimeoutTime_HU_A" SG_ 1276 AccPedPosnGS 5000;
BA_ "GenSigTimeoutMsg_HU_Mid_X451" SG_ 1276 AccPedPosnGS 5000;
BA_ "GenSigTimeoutMsg_HU_High_X451" SG_ 1276 AccPedPosnGS 5000;
BA_ "GenSigTimeoutMsg_HU_B" SG_ 1276 AccPedPosnGS 5000;
BA_ "GenSigTimeoutMsg_HU_A" SG_ 1276 AccPedPosnGS 5000;
BA_ "GenSigSendType" SG_ 1276 AccPedPosnGS 7;
BA_ "GenSigCycleTimeActive" SG_ 1276 AccPedPosnGS 1000;
BA_ "GenSigCycleTime" SG_ 1276 AccPedPosnGS 1000;
BA_ "GenSigTimeoutMsg_HU_High_X445" SG_ 1276 AccPedPosnGS 5000;
BA_ "GenSigTimeoutMsg_HU_Mid_X445" SG_ 1276 AccPedPosnGS 5000;
BA_ "GenSigTimeoutTime_HU_High_X445" SG_ 1276 AccPedPosnGS 5000;
BA_ "GenSigTimeoutTime_HU_Mid_X445" SG_ 1276 AccPedPosnGS 5000;
BA_ "GenSigTimeoutMsg_IVI" SG_ 1276 AccPedPosnGS 5000;
BA_ "GenSigTimeoutTime_IVI" SG_ 1276 AccPedPosnGS 5000;
BA_ "GenSigTimeoutTime_HU_Mid_X451" SG_ 1276 ClntTempGS 5000;
BA_ "GenSigTimeoutTime_HU_High_X451" SG_ 1276 ClntTempGS 5000;
BA_ "GenSigTimeoutTime_HU_B" SG_ 1276 ClntTempGS 5000;
BA_ "GenSigTimeoutTime_HU_A" SG_ 1276 ClntTempGS 5000;
BA_ "GenSigTimeoutMsg_HU_Mid_X451" SG_ 1276 ClntTempGS 5000;
BA_ "GenSigTimeoutMsg_HU_High_X451" SG_ 1276 ClntTempGS 5000;
BA_ "GenSigTimeoutMsg_HU_B" SG_ 1276 ClntTempGS 5000;
BA_ "GenSigTimeoutMsg_HU_A" SG_ 1276 ClntTempGS 5000;
BA_ "GenSigStartValue" SG_ 1276 ClntTempGS 40;
BA_ "GenSigSendType" SG_ 1276 ClntTempGS 7;
BA_ "GenSigCycleTimeActive" SG_ 1276 ClntTempGS 1000;
BA_ "GenSigCycleTime" SG_ 1276 ClntTempGS 1000;
BA_ "GenSigTimeoutMsg_HU_High_X445" SG_ 1276 ClntTempGS 5000;
BA_ "GenSigTimeoutMsg_HU_Mid_X445" SG_ 1276 ClntTempGS 5000;
BA_ "GenSigTimeoutTime_HU_High_X445" SG_ 1276 ClntTempGS 5000;
BA_ "GenSigTimeoutTime_HU_Mid_X445" SG_ 1276 ClntTempGS 5000;
BA_ "GenSigTimeoutMsg_IVI" SG_ 1276 ClntTempGS 5000;
BA_ "GenSigTimeoutTime_IVI" SG_ 1276 ClntTempGS 5000;
BA_ "GenSigTimeoutTime_HU_Mid_X451" SG_ 1276 VehSpdGS 5000;
BA_ "GenSigTimeoutTime_HU_High_X451" SG_ 1276 VehSpdGS 5000;
BA_ "GenSigTimeoutTime_HU_B" SG_ 1276 VehSpdGS 5000;
BA_ "GenSigTimeoutTime_HU_A" SG_ 1276 VehSpdGS 5000;
BA_ "GenSigTimeoutMsg_HU_Mid_X451" SG_ 1276 VehSpdGS 5000;
BA_ "GenSigTimeoutMsg_HU_High_X451" SG_ 1276 VehSpdGS 5000;
BA_ "GenSigTimeoutMsg_HU_B" SG_ 1276 VehSpdGS 5000;
BA_ "GenSigTimeoutMsg_HU_A" SG_ 1276 VehSpdGS 5000;
BA_ "GenSigSendType" SG_ 1276 VehSpdGS 7;
BA_ "GenSigCycleTimeActive" SG_ 1276 VehSpdGS 1000;
BA_ "GenSigCycleTime" SG_ 1276 VehSpdGS 1000;
BA_ "GenSigTimeoutMsg_HU_High_X445" SG_ 1276 VehSpdGS 5000;
BA_ "GenSigTimeoutMsg_HU_Mid_X445" SG_ 1276 VehSpdGS 5000;
BA_ "GenSigTimeoutTime_HU_High_X445" SG_ 1276 VehSpdGS 5000;
BA_ "GenSigTimeoutTime_HU_Mid_X445" SG_ 1276 VehSpdGS 5000;
BA_ "GenSigTimeoutMsg_IVI" SG_ 1276 VehSpdGS 5000;
BA_ "GenSigTimeoutTime_IVI" SG_ 1276 VehSpdGS 5000;
BA_ "GenSigTimeoutTime_HU_Mid_X451" SG_ 1276 OATICSigGS 5000;
BA_ "GenSigTimeoutTime_HU_High_X451" SG_ 1276 OATICSigGS 5000;
BA_ "GenSigTimeoutTime_HU_B" SG_ 1276 OATICSigGS 5000;
BA_ "GenSigTimeoutTime_HU_A" SG_ 1276 OATICSigGS 5000;
BA_ "GenSigTimeoutMsg_HU_Mid_X451" SG_ 1276 OATICSigGS 5000;
BA_ "GenSigTimeoutMsg_HU_High_X451" SG_ 1276 OATICSigGS 5000;
BA_ "GenSigTimeoutMsg_HU_B" SG_ 1276 OATICSigGS 5000;
BA_ "GenSigTimeoutMsg_HU_A" SG_ 1276 OATICSigGS 5000;
BA_ "GenSigStartValue" SG_ 1276 OATICSigGS 40;
BA_ "GenSigSendType" SG_ 1276 OATICSigGS 7;
BA_ "GenSigCycleTimeActive" SG_ 1276 OATICSigGS 1000;
BA_ "GenSigCycleTime" SG_ 1276 OATICSigGS 1000;
BA_ "GenSigTimeoutMsg_HU_High_X445" SG_ 1276 OATICSigGS 5000;
BA_ "GenSigTimeoutMsg_HU_Mid_X445" SG_ 1276 OATICSigGS 5000;
BA_ "GenSigTimeoutTime_HU_High_X445" SG_ 1276 OATICSigGS 5000;
BA_ "GenSigTimeoutTime_HU_Mid_X445" SG_ 1276 OATICSigGS 5000;
BA_ "GenSigTimeoutMsg_IVI" SG_ 1276 OATICSigGS 5000;
BA_ "GenSigTimeoutTime_IVI" SG_ 1276 OATICSigGS 5000;
BA_ "GenSigTimeoutTime_HU_Mid_X451" SG_ 1276 PowerModeStateGS 5000;
BA_ "GenSigTimeoutTime_HU_High_X451" SG_ 1276 PowerModeStateGS 5000;
BA_ "GenSigTimeoutTime_HU_B" SG_ 1276 PowerModeStateGS 5000;
BA_ "GenSigTimeoutTime_HU_A" SG_ 1276 PowerModeStateGS 5000;
BA_ "GenSigTimeoutMsg_HU_Mid_X451" SG_ 1276 PowerModeStateGS 5000;
BA_ "GenSigTimeoutMsg_HU_High_X451" SG_ 1276 PowerModeStateGS 5000;
BA_ "GenSigTimeoutMsg_HU_B" SG_ 1276 PowerModeStateGS 5000;
BA_ "GenSigTimeoutMsg_HU_A" SG_ 1276 PowerModeStateGS 5000;
BA_ "GenSigSendType" SG_ 1276 PowerModeStateGS 7;
BA_ "GenSigCycleTimeActive" SG_ 1276 PowerModeStateGS 1000;
BA_ "GenSigCycleTime" SG_ 1276 PowerModeStateGS 1000;
BA_ "GenSigTimeoutMsg_HU_High_X445" SG_ 1276 PowerModeStateGS 5000;
BA_ "GenSigTimeoutMsg_HU_Mid_X445" SG_ 1276 PowerModeStateGS 5000;
BA_ "GenSigTimeoutTime_HU_High_X445" SG_ 1276 PowerModeStateGS 5000;
BA_ "GenSigTimeoutTime_HU_Mid_X445" SG_ 1276 PowerModeStateGS 5000;
BA_ "GenSigTimeoutMsg_IVI" SG_ 1276 PowerModeStateGS 5000;
BA_ "GenSigTimeoutTime_IVI" SG_ 1276 PowerModeStateGS 5000;
BA_ "GenSigTimeoutTime_HU_Mid_X451" SG_ 1276 ParkBrkStateGS 5000;
BA_ "GenSigTimeoutTime_HU_High_X451" SG_ 1276 ParkBrkStateGS 5000;
BA_ "GenSigTimeoutTime_HU_B" SG_ 1276 ParkBrkStateGS 5000;
BA_ "GenSigTimeoutTime_HU_A" SG_ 1276 ParkBrkStateGS 5000;
BA_ "GenSigTimeoutMsg_HU_Mid_X451" SG_ 1276 ParkBrkStateGS 5000;
BA_ "GenSigTimeoutMsg_HU_High_X451" SG_ 1276 ParkBrkStateGS 5000;
BA_ "GenSigTimeoutMsg_HU_B" SG_ 1276 ParkBrkStateGS 5000;
BA_ "GenSigTimeoutMsg_HU_A" SG_ 1276 ParkBrkStateGS 5000;
BA_ "GenSigSendType" SG_ 1276 ParkBrkStateGS 7;
BA_ "GenSigCycleTimeActive" SG_ 1276 ParkBrkStateGS 1000;
BA_ "GenSigCycleTime" SG_ 1276 ParkBrkStateGS 1000;
BA_ "GenSigTimeoutMsg_HU_High_X445" SG_ 1276 ParkBrkStateGS 5000;
BA_ "GenSigTimeoutMsg_HU_Mid_X445" SG_ 1276 ParkBrkStateGS 5000;
BA_ "GenSigTimeoutTime_HU_High_X445" SG_ 1276 ParkBrkStateGS 5000;
BA_ "GenSigTimeoutTime_HU_Mid_X445" SG_ 1276 ParkBrkStateGS 5000;
BA_ "GenSigTimeoutMsg_IVI" SG_ 1276 ParkBrkStateGS 5000;
BA_ "GenSigTimeoutTime_IVI" SG_ 1276 ParkBrkStateGS 5000;
BA_ "GenSigTimeoutTime_HU_Mid_X451" SG_ 1278 VehIdetNumGS 5000;
BA_ "GenSigTimeoutTime_HU_High_X451" SG_ 1278 VehIdetNumGS 5000;
BA_ "GenSigTimeoutTime_HU_B" SG_ 1278 VehIdetNumGS 5000;
BA_ "GenSigTimeoutTime_HU_A" SG_ 1278 VehIdetNumGS 5000;
BA_ "GenSigTimeoutMsg_HU_Mid_X451" SG_ 1278 VehIdetNumGS 5000;
BA_ "GenSigTimeoutMsg_HU_High_X451" SG_ 1278 VehIdetNumGS 5000;
BA_ "GenSigTimeoutMsg_HU_B" SG_ 1278 VehIdetNumGS 5000;
BA_ "GenSigTimeoutMsg_HU_A" SG_ 1278 VehIdetNumGS 5000;
BA_ "GenSigSendType" SG_ 1278 VehIdetNumGS 7;
BA_ "GenSigCycleTimeActive" SG_ 1278 VehIdetNumGS 1000;
BA_ "GenSigCycleTime" SG_ 1278 VehIdetNumGS 1000;
BA_ "GenSigTimeoutMsg_HU_High_X445" SG_ 1278 VehIdetNumGS 5000;
BA_ "GenSigTimeoutMsg_HU_Mid_X445" SG_ 1278 VehIdetNumGS 5000;
BA_ "GenSigTimeoutTime_HU_High_X445" SG_ 1278 VehIdetNumGS 5000;
BA_ "GenSigTimeoutTime_HU_Mid_X445" SG_ 1278 VehIdetNumGS 5000;
BA_ "GenSigTimeoutMsg_IVI" SG_ 1278 VehIdetNumGS 5000;
BA_ "GenSigTimeoutTime_IVI" SG_ 1278 VehIdetNumGS 5000;
BA_ "GenSigTimeoutTime_HU_Mid_X451" SG_ 1280 BCM_NMPDU_SRC_ECU_ID 1000;
BA_ "GenSigTimeoutTime_HU_High_X451" SG_ 1280 BCM_NMPDU_SRC_ECU_ID 1000;
BA_ "GenSigTimeoutTime_HU_B" SG_ 1280 BCM_NMPDU_SRC_ECU_ID 1000;
BA_ "GenSigTimeoutTime_HU_A" SG_ 1280 BCM_NMPDU_SRC_ECU_ID 1000;
BA_ "GenSigTimeoutMsg_HU_Mid_X451" SG_ 1280 BCM_NMPDU_SRC_ECU_ID 1000;
BA_ "GenSigTimeoutMsg_HU_High_X451" SG_ 1280 BCM_NMPDU_SRC_ECU_ID 1000;
BA_ "GenSigTimeoutMsg_HU_B" SG_ 1280 BCM_NMPDU_SRC_ECU_ID 1000;
BA_ "GenSigTimeoutMsg_HU_A" SG_ 1280 BCM_NMPDU_SRC_ECU_ID 1000;
BA_ "GenSigSendType" SG_ 1280 BCM_NMPDU_SRC_ECU_ID 7;
BA_ "GenSigCycleTimeActive" SG_ 1280 BCM_NMPDU_SRC_ECU_ID 200;
BA_ "GenSigCycleTime" SG_ 1280 BCM_NMPDU_SRC_ECU_ID 200;
BA_ "GenSigTimeoutMsg_HU_High_X445" SG_ 1280 BCM_NMPDU_SRC_ECU_ID 1000;
BA_ "GenSigTimeoutMsg_HU_Mid_X445" SG_ 1280 BCM_NMPDU_SRC_ECU_ID 1000;
BA_ "GenSigTimeoutTime_HU_High_X445" SG_ 1280 BCM_NMPDU_SRC_ECU_ID 1000;
BA_ "GenSigTimeoutTime_HU_Mid_X445" SG_ 1280 BCM_NMPDU_SRC_ECU_ID 1000;
BA_ "GenSigTimeoutMsg_IVI" SG_ 1280 BCM_NMPDU_SRC_ECU_ID 1000;
BA_ "GenSigTimeoutTime_IVI" SG_ 1280 BCM_NMPDU_SRC_ECU_ID 1000;
BA_ "GenSigTimeoutTime_HU_Mid_X451" SG_ 1280 RepeatMessageReq_BCM 1000;
BA_ "GenSigTimeoutTime_HU_High_X451" SG_ 1280 RepeatMessageReq_BCM 1000;
BA_ "GenSigTimeoutTime_HU_B" SG_ 1280 RepeatMessageReq_BCM 1000;
BA_ "GenSigTimeoutTime_HU_A" SG_ 1280 RepeatMessageReq_BCM 1000;
BA_ "GenSigTimeoutMsg_HU_Mid_X451" SG_ 1280 RepeatMessageReq_BCM 1000;
BA_ "GenSigTimeoutMsg_HU_High_X451" SG_ 1280 RepeatMessageReq_BCM 1000;
BA_ "GenSigTimeoutMsg_HU_B" SG_ 1280 RepeatMessageReq_BCM 1000;
BA_ "GenSigTimeoutMsg_HU_A" SG_ 1280 RepeatMessageReq_BCM 1000;
BA_ "GenSigSendType" SG_ 1280 RepeatMessageReq_BCM 7;
BA_ "GenSigCycleTimeActive" SG_ 1280 RepeatMessageReq_BCM 200;
BA_ "GenSigCycleTime" SG_ 1280 RepeatMessageReq_BCM 200;
BA_ "GenSigTimeoutMsg_HU_High_X445" SG_ 1280 RepeatMessageReq_BCM 1000;
BA_ "GenSigTimeoutMsg_HU_Mid_X445" SG_ 1280 RepeatMessageReq_BCM 1000;
BA_ "GenSigTimeoutTime_HU_High_X445" SG_ 1280 RepeatMessageReq_BCM 1000;
BA_ "GenSigTimeoutTime_HU_Mid_X445" SG_ 1280 RepeatMessageReq_BCM 1000;
BA_ "GenSigTimeoutMsg_IVI" SG_ 1280 RepeatMessageReq_BCM 1000;
BA_ "GenSigTimeoutTime_IVI" SG_ 1280 RepeatMessageReq_BCM 1000;
BA_ "GenSigTimeoutTime_HU_Mid_X451" SG_ 1280 Reserved0 1000;
BA_ "GenSigTimeoutTime_HU_High_X451" SG_ 1280 Reserved0 1000;
BA_ "GenSigTimeoutTime_HU_B" SG_ 1280 Reserved0 1000;
BA_ "GenSigTimeoutTime_HU_A" SG_ 1280 Reserved0 1000;
BA_ "GenSigTimeoutMsg_HU_Mid_X451" SG_ 1280 Reserved0 1000;
BA_ "GenSigTimeoutMsg_HU_High_X451" SG_ 1280 Reserved0 1000;
BA_ "GenSigTimeoutMsg_HU_B" SG_ 1280 Reserved0 1000;
BA_ "GenSigTimeoutMsg_HU_A" SG_ 1280 Reserved0 1000;
BA_ "GenSigSendType" SG_ 1280 Reserved0 7;
BA_ "GenSigCycleTimeActive" SG_ 1280 Reserved0 200;
BA_ "GenSigCycleTime" SG_ 1280 Reserved0 200;
BA_ "GenSigTimeoutMsg_HU_High_X445" SG_ 1280 Reserved0 1000;
BA_ "GenSigTimeoutMsg_HU_Mid_X445" SG_ 1280 Reserved0 1000;
BA_ "GenSigTimeoutTime_HU_High_X445" SG_ 1280 Reserved0 1000;
BA_ "GenSigTimeoutTime_HU_Mid_X445" SG_ 1280 Reserved0 1000;
BA_ "GenSigTimeoutMsg_IVI" SG_ 1280 Reserved0 1000;
BA_ "GenSigTimeoutTime_IVI" SG_ 1280 Reserved0 1000;
BA_ "GenSigTimeoutTime_HU_Mid_X451" SG_ 1280 Reserved1 1000;
BA_ "GenSigTimeoutTime_HU_High_X451" SG_ 1280 Reserved1 1000;
BA_ "GenSigTimeoutTime_HU_B" SG_ 1280 Reserved1 1000;
BA_ "GenSigTimeoutTime_HU_A" SG_ 1280 Reserved1 1000;
BA_ "GenSigTimeoutMsg_HU_Mid_X451" SG_ 1280 Reserved1 1000;
BA_ "GenSigTimeoutMsg_HU_High_X451" SG_ 1280 Reserved1 1000;
BA_ "GenSigTimeoutMsg_HU_B" SG_ 1280 Reserved1 1000;
BA_ "GenSigTimeoutMsg_HU_A" SG_ 1280 Reserved1 1000;
BA_ "GenSigSendType" SG_ 1280 Reserved1 7;
BA_ "GenSigCycleTimeActive" SG_ 1280 Reserved1 200;
BA_ "GenSigCycleTime" SG_ 1280 Reserved1 200;
BA_ "GenSigTimeoutMsg_HU_High_X445" SG_ 1280 Reserved1 1000;
BA_ "GenSigTimeoutMsg_HU_Mid_X445" SG_ 1280 Reserved1 1000;
BA_ "GenSigTimeoutTime_HU_High_X445" SG_ 1280 Reserved1 1000;
BA_ "GenSigTimeoutTime_HU_Mid_X445" SG_ 1280 Reserved1 1000;
BA_ "GenSigTimeoutMsg_IVI" SG_ 1280 Reserved1 1000;
BA_ "GenSigTimeoutTime_IVI" SG_ 1280 Reserved1 1000;
BA_ "GenSigTimeoutTime_HU_Mid_X451" SG_ 1280 NMCoOrdSlpReady_BCM 1000;
BA_ "GenSigTimeoutTime_HU_High_X451" SG_ 1280 NMCoOrdSlpReady_BCM 1000;
BA_ "GenSigTimeoutTime_HU_B" SG_ 1280 NMCoOrdSlpReady_BCM 1000;
BA_ "GenSigTimeoutTime_HU_A" SG_ 1280 NMCoOrdSlpReady_BCM 1000;
BA_ "GenSigTimeoutMsg_HU_Mid_X451" SG_ 1280 NMCoOrdSlpReady_BCM 1000;
BA_ "GenSigTimeoutMsg_HU_High_X451" SG_ 1280 NMCoOrdSlpReady_BCM 1000;
BA_ "GenSigTimeoutMsg_HU_B" SG_ 1280 NMCoOrdSlpReady_BCM 1000;
BA_ "GenSigTimeoutMsg_HU_A" SG_ 1280 NMCoOrdSlpReady_BCM 1000;
BA_ "GenSigSendType" SG_ 1280 NMCoOrdSlpReady_BCM 7;
BA_ "GenSigCycleTimeActive" SG_ 1280 NMCoOrdSlpReady_BCM 200;
BA_ "GenSigCycleTime" SG_ 1280 NMCoOrdSlpReady_BCM 200;
BA_ "GenSigTimeoutMsg_HU_High_X445" SG_ 1280 NMCoOrdSlpReady_BCM 1000;
BA_ "GenSigTimeoutMsg_HU_Mid_X445" SG_ 1280 NMCoOrdSlpReady_BCM 1000;
BA_ "GenSigTimeoutTime_HU_High_X445" SG_ 1280 NMCoOrdSlpReady_BCM 1000;
BA_ "GenSigTimeoutTime_HU_Mid_X445" SG_ 1280 NMCoOrdSlpReady_BCM 1000;
BA_ "GenSigTimeoutMsg_IVI" SG_ 1280 NMCoOrdSlpReady_BCM 1000;
BA_ "GenSigTimeoutTime_IVI" SG_ 1280 NMCoOrdSlpReady_BCM 1000;
BA_ "GenSigTimeoutTime_HU_Mid_X451" SG_ 1280 ActiveWakeUp_BCM 1000;
BA_ "GenSigTimeoutTime_HU_High_X451" SG_ 1280 ActiveWakeUp_BCM 1000;
BA_ "GenSigTimeoutTime_HU_B" SG_ 1280 ActiveWakeUp_BCM 1000;
BA_ "GenSigTimeoutTime_HU_A" SG_ 1280 ActiveWakeUp_BCM 1000;
BA_ "GenSigTimeoutMsg_HU_Mid_X451" SG_ 1280 ActiveWakeUp_BCM 1000;
BA_ "GenSigTimeoutMsg_HU_High_X451" SG_ 1280 ActiveWakeUp_BCM 1000;
BA_ "GenSigTimeoutMsg_HU_B" SG_ 1280 ActiveWakeUp_BCM 1000;
BA_ "GenSigTimeoutMsg_HU_A" SG_ 1280 ActiveWakeUp_BCM 1000;
BA_ "GenSigSendType" SG_ 1280 ActiveWakeUp_BCM 7;
BA_ "GenSigCycleTimeActive" SG_ 1280 ActiveWakeUp_BCM 200;
BA_ "GenSigCycleTime" SG_ 1280 ActiveWakeUp_BCM 200;
BA_ "GenSigTimeoutMsg_HU_High_X445" SG_ 1280 ActiveWakeUp_BCM 1000;
BA_ "GenSigTimeoutMsg_HU_Mid_X445" SG_ 1280 ActiveWakeUp_BCM 1000;
BA_ "GenSigTimeoutTime_HU_High_X445" SG_ 1280 ActiveWakeUp_BCM 1000;
BA_ "GenSigTimeoutTime_HU_Mid_X445" SG_ 1280 ActiveWakeUp_BCM 1000;
BA_ "GenSigTimeoutMsg_IVI" SG_ 1280 ActiveWakeUp_BCM 1000;
BA_ "GenSigTimeoutTime_IVI" SG_ 1280 ActiveWakeUp_BCM 1000;
BA_ "GenSigTimeoutTime_HU_Mid_X451" SG_ 1280 Reserved2 1000;
BA_ "GenSigTimeoutTime_HU_High_X451" SG_ 1280 Reserved2 1000;
BA_ "GenSigTimeoutTime_HU_B" SG_ 1280 Reserved2 1000;
BA_ "GenSigTimeoutTime_HU_A" SG_ 1280 Reserved2 1000;
BA_ "GenSigTimeoutMsg_HU_Mid_X451" SG_ 1280 Reserved2 1000;
BA_ "GenSigTimeoutMsg_HU_High_X451" SG_ 1280 Reserved2 1000;
BA_ "GenSigTimeoutMsg_HU_B" SG_ 1280 Reserved2 1000;
BA_ "GenSigTimeoutMsg_HU_A" SG_ 1280 Reserved2 1000;
BA_ "GenSigSendType" SG_ 1280 Reserved2 7;
BA_ "GenSigCycleTimeActive" SG_ 1280 Reserved2 200;
BA_ "GenSigCycleTime" SG_ 1280 Reserved2 200;
BA_ "GenSigTimeoutMsg_HU_High_X445" SG_ 1280 Reserved2 1000;
BA_ "GenSigTimeoutMsg_HU_Mid_X445" SG_ 1280 Reserved2 1000;
BA_ "GenSigTimeoutTime_HU_High_X445" SG_ 1280 Reserved2 1000;
BA_ "GenSigTimeoutTime_HU_Mid_X445" SG_ 1280 Reserved2 1000;
BA_ "GenSigTimeoutMsg_IVI" SG_ 1280 Reserved2 1000;
BA_ "GenSigTimeoutTime_IVI" SG_ 1280 Reserved2 1000;
BA_ "GenSigTimeoutTime_HU_Mid_X451" SG_ 1280 PartialNetworkInformation_BCM 1000;
BA_ "GenSigTimeoutTime_HU_High_X451" SG_ 1280 PartialNetworkInformation_BCM 1000;
BA_ "GenSigTimeoutTime_HU_B" SG_ 1280 PartialNetworkInformation_BCM 1000;
BA_ "GenSigTimeoutTime_HU_A" SG_ 1280 PartialNetworkInformation_BCM 1000;
BA_ "GenSigTimeoutMsg_HU_Mid_X451" SG_ 1280 PartialNetworkInformation_BCM 1000;
BA_ "GenSigTimeoutMsg_HU_High_X451" SG_ 1280 PartialNetworkInformation_BCM 1000;
BA_ "GenSigTimeoutMsg_HU_B" SG_ 1280 PartialNetworkInformation_BCM 1000;
BA_ "GenSigTimeoutMsg_HU_A" SG_ 1280 PartialNetworkInformation_BCM 1000;
BA_ "GenSigSendType" SG_ 1280 PartialNetworkInformation_BCM 7;
BA_ "GenSigCycleTimeActive" SG_ 1280 PartialNetworkInformation_BCM 200;
BA_ "GenSigCycleTime" SG_ 1280 PartialNetworkInformation_BCM 200;
BA_ "GenSigTimeoutMsg_HU_High_X445" SG_ 1280 PartialNetworkInformation_BCM 1000;
BA_ "GenSigTimeoutMsg_HU_Mid_X445" SG_ 1280 PartialNetworkInformation_BCM 1000;
BA_ "GenSigTimeoutTime_HU_High_X445" SG_ 1280 PartialNetworkInformation_BCM 1000;
BA_ "GenSigTimeoutTime_HU_Mid_X445" SG_ 1280 PartialNetworkInformation_BCM 1000;
BA_ "GenSigTimeoutMsg_IVI" SG_ 1280 PartialNetworkInformation_BCM 1000;
BA_ "GenSigTimeoutTime_IVI" SG_ 1280 PartialNetworkInformation_BCM 1000;
BA_ "GenSigTimeoutTime_HU_Mid_X451" SG_ 1280 Reserved3 1000;
BA_ "GenSigTimeoutTime_HU_High_X451" SG_ 1280 Reserved3 1000;
BA_ "GenSigTimeoutTime_HU_B" SG_ 1280 Reserved3 1000;
BA_ "GenSigTimeoutTime_HU_A" SG_ 1280 Reserved3 1000;
BA_ "GenSigTimeoutMsg_HU_Mid_X451" SG_ 1280 Reserved3 1000;
BA_ "GenSigTimeoutMsg_HU_High_X451" SG_ 1280 Reserved3 1000;
BA_ "GenSigTimeoutMsg_HU_B" SG_ 1280 Reserved3 1000;
BA_ "GenSigTimeoutMsg_HU_A" SG_ 1280 Reserved3 1000;
BA_ "GenSigSendType" SG_ 1280 Reserved3 7;
BA_ "GenSigCycleTimeActive" SG_ 1280 Reserved3 200;
BA_ "GenSigCycleTime" SG_ 1280 Reserved3 200;
BA_ "GenSigTimeoutMsg_HU_High_X445" SG_ 1280 Reserved3 1000;
BA_ "GenSigTimeoutMsg_HU_Mid_X445" SG_ 1280 Reserved3 1000;
BA_ "GenSigTimeoutTime_HU_High_X445" SG_ 1280 Reserved3 1000;
BA_ "GenSigTimeoutTime_HU_Mid_X445" SG_ 1280 Reserved3 1000;
BA_ "GenSigTimeoutMsg_IVI" SG_ 1280 Reserved3 1000;
BA_ "GenSigTimeoutTime_IVI" SG_ 1280 Reserved3 1000;
BA_ "GenSigTimeoutTime_HU_Mid_X451" SG_ 1280 CurrentState_BCM 1000;
BA_ "GenSigTimeoutTime_HU_High_X451" SG_ 1280 CurrentState_BCM 1000;
BA_ "GenSigTimeoutTime_HU_B" SG_ 1280 CurrentState_BCM 1000;
BA_ "GenSigTimeoutTime_HU_A" SG_ 1280 CurrentState_BCM 1000;
BA_ "GenSigTimeoutMsg_HU_Mid_X451" SG_ 1280 CurrentState_BCM 1000;
BA_ "GenSigTimeoutMsg_HU_High_X451" SG_ 1280 CurrentState_BCM 1000;
BA_ "GenSigTimeoutMsg_HU_B" SG_ 1280 CurrentState_BCM 1000;
BA_ "GenSigTimeoutMsg_HU_A" SG_ 1280 CurrentState_BCM 1000;
BA_ "GenSigSendType" SG_ 1280 CurrentState_BCM 7;
BA_ "GenSigCycleTimeActive" SG_ 1280 CurrentState_BCM 200;
BA_ "GenSigCycleTime" SG_ 1280 CurrentState_BCM 200;
BA_ "GenSigTimeoutMsg_HU_High_X445" SG_ 1280 CurrentState_BCM 1000;
BA_ "GenSigTimeoutMsg_HU_Mid_X445" SG_ 1280 CurrentState_BCM 1000;
BA_ "GenSigTimeoutTime_HU_High_X445" SG_ 1280 CurrentState_BCM 1000;
BA_ "GenSigTimeoutTime_HU_Mid_X445" SG_ 1280 CurrentState_BCM 1000;
BA_ "GenSigTimeoutMsg_IVI" SG_ 1280 CurrentState_BCM 1000;
BA_ "GenSigTimeoutTime_IVI" SG_ 1280 CurrentState_BCM 1000;
BA_ "GenSigTimeoutTime_HU_Mid_X451" SG_ 1280 PreviousState_BCM 1000;
BA_ "GenSigTimeoutTime_HU_High_X451" SG_ 1280 PreviousState_BCM 1000;
BA_ "GenSigTimeoutTime_HU_B" SG_ 1280 PreviousState_BCM 1000;
BA_ "GenSigTimeoutTime_HU_A" SG_ 1280 PreviousState_BCM 1000;
BA_ "GenSigTimeoutMsg_HU_Mid_X451" SG_ 1280 PreviousState_BCM 1000;
BA_ "GenSigTimeoutMsg_HU_High_X451" SG_ 1280 PreviousState_BCM 1000;
BA_ "GenSigTimeoutMsg_HU_B" SG_ 1280 PreviousState_BCM 1000;
BA_ "GenSigTimeoutMsg_HU_A" SG_ 1280 PreviousState_BCM 1000;
BA_ "GenSigSendType" SG_ 1280 PreviousState_BCM 7;
BA_ "GenSigCycleTimeActive" SG_ 1280 PreviousState_BCM 200;
BA_ "GenSigCycleTime" SG_ 1280 PreviousState_BCM 200;
BA_ "GenSigTimeoutMsg_HU_High_X445" SG_ 1280 PreviousState_BCM 1000;
BA_ "GenSigTimeoutMsg_HU_Mid_X445" SG_ 1280 PreviousState_BCM 1000;
BA_ "GenSigTimeoutTime_HU_High_X445" SG_ 1280 PreviousState_BCM 1000;
BA_ "GenSigTimeoutTime_HU_Mid_X445" SG_ 1280 PreviousState_BCM 1000;
BA_ "GenSigTimeoutMsg_IVI" SG_ 1280 PreviousState_BCM 1000;
BA_ "GenSigTimeoutTime_IVI" SG_ 1280 PreviousState_BCM 1000;
BA_ "GenSigTimeoutTime_HU_Mid_X451" SG_ 1280 Reserved4 1000;
BA_ "GenSigTimeoutTime_HU_High_X451" SG_ 1280 Reserved4 1000;
BA_ "GenSigTimeoutTime_HU_B" SG_ 1280 Reserved4 1000;
BA_ "GenSigTimeoutTime_HU_A" SG_ 1280 Reserved4 1000;
BA_ "GenSigTimeoutMsg_HU_Mid_X451" SG_ 1280 Reserved4 1000;
BA_ "GenSigTimeoutMsg_HU_High_X451" SG_ 1280 Reserved4 1000;
BA_ "GenSigTimeoutMsg_HU_B" SG_ 1280 Reserved4 1000;
BA_ "GenSigTimeoutMsg_HU_A" SG_ 1280 Reserved4 1000;
BA_ "GenSigSendType" SG_ 1280 Reserved4 7;
BA_ "GenSigCycleTimeActive" SG_ 1280 Reserved4 200;
BA_ "GenSigCycleTime" SG_ 1280 Reserved4 200;
BA_ "GenSigTimeoutMsg_HU_High_X445" SG_ 1280 Reserved4 1000;
BA_ "GenSigTimeoutMsg_HU_Mid_X445" SG_ 1280 Reserved4 1000;
BA_ "GenSigTimeoutTime_HU_High_X445" SG_ 1280 Reserved4 1000;
BA_ "GenSigTimeoutTime_HU_Mid_X445" SG_ 1280 Reserved4 1000;
BA_ "GenSigTimeoutMsg_IVI" SG_ 1280 Reserved4 1000;
BA_ "GenSigTimeoutTime_IVI" SG_ 1280 Reserved4 1000;
BA_ "GenSigTimeoutTime_HU_Mid_X451" SG_ 1280 Reserved5 1000;
BA_ "GenSigTimeoutTime_HU_High_X451" SG_ 1280 Reserved5 1000;
BA_ "GenSigTimeoutTime_HU_B" SG_ 1280 Reserved5 1000;
BA_ "GenSigTimeoutTime_HU_A" SG_ 1280 Reserved5 1000;
BA_ "GenSigTimeoutMsg_HU_Mid_X451" SG_ 1280 Reserved5 1000;
BA_ "GenSigTimeoutMsg_HU_High_X451" SG_ 1280 Reserved5 1000;
BA_ "GenSigTimeoutMsg_HU_B" SG_ 1280 Reserved5 1000;
BA_ "GenSigTimeoutMsg_HU_A" SG_ 1280 Reserved5 1000;
BA_ "GenSigSendType" SG_ 1280 Reserved5 7;
BA_ "GenSigCycleTimeActive" SG_ 1280 Reserved5 200;
BA_ "GenSigCycleTime" SG_ 1280 Reserved5 200;
BA_ "GenSigTimeoutMsg_HU_High_X445" SG_ 1280 Reserved5 1000;
BA_ "GenSigTimeoutMsg_HU_Mid_X445" SG_ 1280 Reserved5 1000;
BA_ "GenSigTimeoutTime_HU_High_X445" SG_ 1280 Reserved5 1000;
BA_ "GenSigTimeoutTime_HU_Mid_X445" SG_ 1280 Reserved5 1000;
BA_ "GenSigTimeoutMsg_IVI" SG_ 1280 Reserved5 1000;
BA_ "GenSigTimeoutTime_IVI" SG_ 1280 Reserved5 1000;
BA_ "GenSigTimeoutTime_HU_Mid_X451" SG_ 1280 Reserved6 1000;
BA_ "GenSigTimeoutTime_HU_High_X451" SG_ 1280 Reserved6 1000;
BA_ "GenSigTimeoutTime_HU_B" SG_ 1280 Reserved6 1000;
BA_ "GenSigTimeoutTime_HU_A" SG_ 1280 Reserved6 1000;
BA_ "GenSigTimeoutMsg_HU_Mid_X451" SG_ 1280 Reserved6 1000;
BA_ "GenSigTimeoutMsg_HU_High_X451" SG_ 1280 Reserved6 1000;
BA_ "GenSigTimeoutMsg_HU_B" SG_ 1280 Reserved6 1000;
BA_ "GenSigTimeoutMsg_HU_A" SG_ 1280 Reserved6 1000;
BA_ "GenSigSendType" SG_ 1280 Reserved6 7;
BA_ "GenSigCycleTimeActive" SG_ 1280 Reserved6 200;
BA_ "GenSigCycleTime" SG_ 1280 Reserved6 200;
BA_ "GenSigTimeoutMsg_HU_High_X445" SG_ 1280 Reserved6 1000;
BA_ "GenSigTimeoutMsg_HU_Mid_X445" SG_ 1280 Reserved6 1000;
BA_ "GenSigTimeoutTime_HU_High_X445" SG_ 1280 Reserved6 1000;
BA_ "GenSigTimeoutTime_HU_Mid_X445" SG_ 1280 Reserved6 1000;
BA_ "GenSigTimeoutMsg_IVI" SG_ 1280 Reserved6 1000;
BA_ "GenSigTimeoutTime_IVI" SG_ 1280 Reserved6 1000;
BA_ "GenSigTimeoutTime_HU_Mid_X451" SG_ 1280 Reserved7 1000;
BA_ "GenSigTimeoutTime_HU_High_X451" SG_ 1280 Reserved7 1000;
BA_ "GenSigTimeoutTime_HU_B" SG_ 1280 Reserved7 1000;
BA_ "GenSigTimeoutTime_HU_A" SG_ 1280 Reserved7 1000;
BA_ "GenSigTimeoutMsg_HU_Mid_X451" SG_ 1280 Reserved7 1000;
BA_ "GenSigTimeoutMsg_HU_High_X451" SG_ 1280 Reserved7 1000;
BA_ "GenSigTimeoutMsg_HU_B" SG_ 1280 Reserved7 1000;
BA_ "GenSigTimeoutMsg_HU_A" SG_ 1280 Reserved7 1000;
BA_ "GenSigSendType" SG_ 1280 Reserved7 7;
BA_ "GenSigCycleTimeActive" SG_ 1280 Reserved7 200;
BA_ "GenSigCycleTime" SG_ 1280 Reserved7 200;
BA_ "GenSigTimeoutMsg_HU_High_X445" SG_ 1280 Reserved7 1000;
BA_ "GenSigTimeoutMsg_HU_Mid_X445" SG_ 1280 Reserved7 1000;
BA_ "GenSigTimeoutTime_HU_High_X445" SG_ 1280 Reserved7 1000;
BA_ "GenSigTimeoutTime_HU_Mid_X445" SG_ 1280 Reserved7 1000;
BA_ "GenSigTimeoutMsg_IVI" SG_ 1280 Reserved7 1000;
BA_ "GenSigTimeoutTime_IVI" SG_ 1280 Reserved7 1000;
BA_ "GenSigTimeoutTime_HU_Mid_X451" SG_ 1280 BCM_NMPDU_USER_DATA_D1 1000;
BA_ "GenSigTimeoutTime_HU_High_X451" SG_ 1280 BCM_NMPDU_USER_DATA_D1 1000;
BA_ "GenSigTimeoutTime_HU_B" SG_ 1280 BCM_NMPDU_USER_DATA_D1 1000;
BA_ "GenSigTimeoutTime_HU_A" SG_ 1280 BCM_NMPDU_USER_DATA_D1 1000;
BA_ "GenSigTimeoutMsg_HU_Mid_X451" SG_ 1280 BCM_NMPDU_USER_DATA_D1 1000;
BA_ "GenSigTimeoutMsg_HU_High_X451" SG_ 1280 BCM_NMPDU_USER_DATA_D1 1000;
BA_ "GenSigTimeoutMsg_HU_B" SG_ 1280 BCM_NMPDU_USER_DATA_D1 1000;
BA_ "GenSigTimeoutMsg_HU_A" SG_ 1280 BCM_NMPDU_USER_DATA_D1 1000;
BA_ "GenSigSendType" SG_ 1280 BCM_NMPDU_USER_DATA_D1 7;
BA_ "GenSigCycleTimeActive" SG_ 1280 BCM_NMPDU_USER_DATA_D1 200;
BA_ "GenSigCycleTime" SG_ 1280 BCM_NMPDU_USER_DATA_D1 200;
BA_ "GenSigTimeoutMsg_HU_High_X445" SG_ 1280 BCM_NMPDU_USER_DATA_D1 1000;
BA_ "GenSigTimeoutMsg_HU_Mid_X445" SG_ 1280 BCM_NMPDU_USER_DATA_D1 1000;
BA_ "GenSigTimeoutTime_HU_High_X445" SG_ 1280 BCM_NMPDU_USER_DATA_D1 1000;
BA_ "GenSigTimeoutTime_HU_Mid_X445" SG_ 1280 BCM_NMPDU_USER_DATA_D1 1000;
BA_ "GenSigTimeoutMsg_IVI" SG_ 1280 BCM_NMPDU_USER_DATA_D1 1000;
BA_ "GenSigTimeoutTime_IVI" SG_ 1280 BCM_NMPDU_USER_DATA_D1 1000;
BA_ "GenSigTimeoutTime_HU_Mid_X451" SG_ 1280 BCM_NMPDU_USER_DATA_D2 1000;
BA_ "GenSigTimeoutTime_HU_High_X451" SG_ 1280 BCM_NMPDU_USER_DATA_D2 1000;
BA_ "GenSigTimeoutTime_HU_B" SG_ 1280 BCM_NMPDU_USER_DATA_D2 1000;
BA_ "GenSigTimeoutTime_HU_A" SG_ 1280 BCM_NMPDU_USER_DATA_D2 1000;
BA_ "GenSigTimeoutMsg_HU_Mid_X451" SG_ 1280 BCM_NMPDU_USER_DATA_D2 1000;
BA_ "GenSigTimeoutMsg_HU_High_X451" SG_ 1280 BCM_NMPDU_USER_DATA_D2 1000;
BA_ "GenSigTimeoutMsg_HU_B" SG_ 1280 BCM_NMPDU_USER_DATA_D2 1000;
BA_ "GenSigTimeoutMsg_HU_A" SG_ 1280 BCM_NMPDU_USER_DATA_D2 1000;
BA_ "GenSigSendType" SG_ 1280 BCM_NMPDU_USER_DATA_D2 7;
BA_ "GenSigCycleTimeActive" SG_ 1280 BCM_NMPDU_USER_DATA_D2 200;
BA_ "GenSigCycleTime" SG_ 1280 BCM_NMPDU_USER_DATA_D2 200;
BA_ "GenSigTimeoutMsg_HU_High_X445" SG_ 1280 BCM_NMPDU_USER_DATA_D2 1000;
BA_ "GenSigTimeoutMsg_HU_Mid_X445" SG_ 1280 BCM_NMPDU_USER_DATA_D2 1000;
BA_ "GenSigTimeoutTime_HU_High_X445" SG_ 1280 BCM_NMPDU_USER_DATA_D2 1000;
BA_ "GenSigTimeoutTime_HU_Mid_X445" SG_ 1280 BCM_NMPDU_USER_DATA_D2 1000;
BA_ "GenSigTimeoutMsg_IVI" SG_ 1280 BCM_NMPDU_USER_DATA_D2 1000;
BA_ "GenSigTimeoutTime_IVI" SG_ 1280 BCM_NMPDU_USER_DATA_D2 1000;
BA_ "GenSigTimeoutTime_HU_Mid_X451" SG_ 1280 BCM_NMPDU_USER_DATA_D3 1000;
BA_ "GenSigTimeoutTime_HU_High_X451" SG_ 1280 BCM_NMPDU_USER_DATA_D3 1000;
BA_ "GenSigTimeoutTime_HU_B" SG_ 1280 BCM_NMPDU_USER_DATA_D3 1000;
BA_ "GenSigTimeoutTime_HU_A" SG_ 1280 BCM_NMPDU_USER_DATA_D3 1000;
BA_ "GenSigTimeoutMsg_HU_Mid_X451" SG_ 1280 BCM_NMPDU_USER_DATA_D3 1000;
BA_ "GenSigTimeoutMsg_HU_High_X451" SG_ 1280 BCM_NMPDU_USER_DATA_D3 1000;
BA_ "GenSigTimeoutMsg_HU_B" SG_ 1280 BCM_NMPDU_USER_DATA_D3 1000;
BA_ "GenSigTimeoutMsg_HU_A" SG_ 1280 BCM_NMPDU_USER_DATA_D3 1000;
BA_ "GenSigSendType" SG_ 1280 BCM_NMPDU_USER_DATA_D3 7;
BA_ "GenSigCycleTimeActive" SG_ 1280 BCM_NMPDU_USER_DATA_D3 200;
BA_ "GenSigCycleTime" SG_ 1280 BCM_NMPDU_USER_DATA_D3 200;
BA_ "GenSigTimeoutMsg_HU_High_X445" SG_ 1280 BCM_NMPDU_USER_DATA_D3 1000;
BA_ "GenSigTimeoutMsg_HU_Mid_X445" SG_ 1280 BCM_NMPDU_USER_DATA_D3 1000;
BA_ "GenSigTimeoutTime_HU_High_X445" SG_ 1280 BCM_NMPDU_USER_DATA_D3 1000;
BA_ "GenSigTimeoutTime_HU_Mid_X445" SG_ 1280 BCM_NMPDU_USER_DATA_D3 1000;
BA_ "GenSigTimeoutMsg_IVI" SG_ 1280 BCM_NMPDU_USER_DATA_D3 1000;
BA_ "GenSigTimeoutTime_IVI" SG_ 1280 BCM_NMPDU_USER_DATA_D3 1000;
BA_ "GenSigTimeoutTime_HU_Mid_X451" SG_ 1280 BCM_NMPDU_USER_DATA_D4 1000;
BA_ "GenSigTimeoutTime_HU_High_X451" SG_ 1280 BCM_NMPDU_USER_DATA_D4 1000;
BA_ "GenSigTimeoutTime_HU_B" SG_ 1280 BCM_NMPDU_USER_DATA_D4 1000;
BA_ "GenSigTimeoutTime_HU_A" SG_ 1280 BCM_NMPDU_USER_DATA_D4 1000;
BA_ "GenSigTimeoutMsg_HU_Mid_X451" SG_ 1280 BCM_NMPDU_USER_DATA_D4 1000;
BA_ "GenSigTimeoutMsg_HU_High_X451" SG_ 1280 BCM_NMPDU_USER_DATA_D4 1000;
BA_ "GenSigTimeoutMsg_HU_B" SG_ 1280 BCM_NMPDU_USER_DATA_D4 1000;
BA_ "GenSigTimeoutMsg_HU_A" SG_ 1280 BCM_NMPDU_USER_DATA_D4 1000;
BA_ "GenSigSendType" SG_ 1280 BCM_NMPDU_USER_DATA_D4 7;
BA_ "GenSigCycleTimeActive" SG_ 1280 BCM_NMPDU_USER_DATA_D4 200;
BA_ "GenSigCycleTime" SG_ 1280 BCM_NMPDU_USER_DATA_D4 200;
BA_ "GenSigTimeoutMsg_HU_High_X445" SG_ 1280 BCM_NMPDU_USER_DATA_D4 1000;
BA_ "GenSigTimeoutMsg_HU_Mid_X445" SG_ 1280 BCM_NMPDU_USER_DATA_D4 1000;
BA_ "GenSigTimeoutTime_HU_High_X445" SG_ 1280 BCM_NMPDU_USER_DATA_D4 1000;
BA_ "GenSigTimeoutTime_HU_Mid_X445" SG_ 1280 BCM_NMPDU_USER_DATA_D4 1000;
BA_ "GenSigTimeoutMsg_IVI" SG_ 1280 BCM_NMPDU_USER_DATA_D4 1000;
BA_ "GenSigTimeoutTime_IVI" SG_ 1280 BCM_NMPDU_USER_DATA_D4 1000;
BA_ "GenSigTimeoutTime_HU_Mid_X451" SG_ 1280 BCM_NMPDU_USER_DATA_D5 1000;
BA_ "GenSigTimeoutTime_HU_High_X451" SG_ 1280 BCM_NMPDU_USER_DATA_D5 1000;
BA_ "GenSigTimeoutTime_HU_B" SG_ 1280 BCM_NMPDU_USER_DATA_D5 1000;
BA_ "GenSigTimeoutTime_HU_A" SG_ 1280 BCM_NMPDU_USER_DATA_D5 1000;
BA_ "GenSigTimeoutMsg_HU_Mid_X451" SG_ 1280 BCM_NMPDU_USER_DATA_D5 1000;
BA_ "GenSigTimeoutMsg_HU_High_X451" SG_ 1280 BCM_NMPDU_USER_DATA_D5 1000;
BA_ "GenSigTimeoutMsg_HU_B" SG_ 1280 BCM_NMPDU_USER_DATA_D5 1000;
BA_ "GenSigTimeoutMsg_HU_A" SG_ 1280 BCM_NMPDU_USER_DATA_D5 1000;
BA_ "GenSigSendType" SG_ 1280 BCM_NMPDU_USER_DATA_D5 7;
BA_ "GenSigCycleTimeActive" SG_ 1280 BCM_NMPDU_USER_DATA_D5 200;
BA_ "GenSigCycleTime" SG_ 1280 BCM_NMPDU_USER_DATA_D5 200;
BA_ "GenSigTimeoutMsg_HU_High_X445" SG_ 1280 BCM_NMPDU_USER_DATA_D5 1000;
BA_ "GenSigTimeoutMsg_HU_Mid_X445" SG_ 1280 BCM_NMPDU_USER_DATA_D5 1000;
BA_ "GenSigTimeoutTime_HU_High_X445" SG_ 1280 BCM_NMPDU_USER_DATA_D5 1000;
BA_ "GenSigTimeoutTime_HU_Mid_X445" SG_ 1280 BCM_NMPDU_USER_DATA_D5 1000;
BA_ "GenSigTimeoutMsg_IVI" SG_ 1280 BCM_NMPDU_USER_DATA_D5 1000;
BA_ "GenSigTimeoutTime_IVI" SG_ 1280 BCM_NMPDU_USER_DATA_D5 1000;
BA_ "GenSigTimeoutTime_HU_B" SG_ 1281 IPC_NMPDU_SRC_ECU_ID 0;
BA_ "GenSigTimeoutTime_HU_A" SG_ 1281 IPC_NMPDU_SRC_ECU_ID 0;
BA_ "GenSigTimeoutMsg_HU_B" SG_ 1281 IPC_NMPDU_SRC_ECU_ID 0;
BA_ "GenSigTimeoutMsg_HU_A" SG_ 1281 IPC_NMPDU_SRC_ECU_ID 0;
BA_ "GenSigSendType" SG_ 1281 IPC_NMPDU_SRC_ECU_ID 7;
BA_ "GenSigCycleTimeActive" SG_ 1281 IPC_NMPDU_SRC_ECU_ID 200;
BA_ "GenSigCycleTime" SG_ 1281 IPC_NMPDU_SRC_ECU_ID 200;
BA_ "GenSigTimeoutTime_HU_B" SG_ 1281 RepeatMessageReq_IPC 0;
BA_ "GenSigTimeoutTime_HU_A" SG_ 1281 RepeatMessageReq_IPC 0;
BA_ "GenSigTimeoutMsg_HU_B" SG_ 1281 RepeatMessageReq_IPC 0;
BA_ "GenSigTimeoutMsg_HU_A" SG_ 1281 RepeatMessageReq_IPC 0;
BA_ "GenSigSendType" SG_ 1281 RepeatMessageReq_IPC 7;
BA_ "GenSigCycleTimeActive" SG_ 1281 RepeatMessageReq_IPC 200;
BA_ "GenSigCycleTime" SG_ 1281 RepeatMessageReq_IPC 200;
BA_ "GenSigTimeoutTime_HU_B" SG_ 1281 Reserved24 0;
BA_ "GenSigTimeoutTime_HU_A" SG_ 1281 Reserved24 0;
BA_ "GenSigTimeoutMsg_HU_B" SG_ 1281 Reserved24 0;
BA_ "GenSigTimeoutMsg_HU_A" SG_ 1281 Reserved24 0;
BA_ "GenSigSendType" SG_ 1281 Reserved24 7;
BA_ "GenSigCycleTimeActive" SG_ 1281 Reserved24 200;
BA_ "GenSigCycleTime" SG_ 1281 Reserved24 200;
BA_ "GenSigTimeoutTime_HU_B" SG_ 1281 Reserved25 0;
BA_ "GenSigTimeoutTime_HU_A" SG_ 1281 Reserved25 0;
BA_ "GenSigTimeoutMsg_HU_B" SG_ 1281 Reserved25 0;
BA_ "GenSigTimeoutMsg_HU_A" SG_ 1281 Reserved25 0;
BA_ "GenSigSendType" SG_ 1281 Reserved25 7;
BA_ "GenSigCycleTimeActive" SG_ 1281 Reserved25 200;
BA_ "GenSigCycleTime" SG_ 1281 Reserved25 200;
BA_ "GenSigTimeoutTime_HU_B" SG_ 1281 NMCoOrdSlpReady_IPC 0;
BA_ "GenSigTimeoutTime_HU_A" SG_ 1281 NMCoOrdSlpReady_IPC 0;
BA_ "GenSigTimeoutMsg_HU_B" SG_ 1281 NMCoOrdSlpReady_IPC 0;
BA_ "GenSigTimeoutMsg_HU_A" SG_ 1281 NMCoOrdSlpReady_IPC 0;
BA_ "GenSigSendType" SG_ 1281 NMCoOrdSlpReady_IPC 7;
BA_ "GenSigCycleTimeActive" SG_ 1281 NMCoOrdSlpReady_IPC 200;
BA_ "GenSigCycleTime" SG_ 1281 NMCoOrdSlpReady_IPC 200;
BA_ "GenSigTimeoutTime_HU_B" SG_ 1281 ActiveWakeUp_IPC 0;
BA_ "GenSigTimeoutTime_HU_A" SG_ 1281 ActiveWakeUp_IPC 0;
BA_ "GenSigTimeoutMsg_HU_B" SG_ 1281 ActiveWakeUp_IPC 0;
BA_ "GenSigTimeoutMsg_HU_A" SG_ 1281 ActiveWakeUp_IPC 0;
BA_ "GenSigSendType" SG_ 1281 ActiveWakeUp_IPC 7;
BA_ "GenSigCycleTimeActive" SG_ 1281 ActiveWakeUp_IPC 200;
BA_ "GenSigCycleTime" SG_ 1281 ActiveWakeUp_IPC 200;
BA_ "GenSigTimeoutTime_HU_B" SG_ 1281 Reserved27 0;
BA_ "GenSigTimeoutTime_HU_A" SG_ 1281 Reserved27 0;
BA_ "GenSigTimeoutMsg_HU_B" SG_ 1281 Reserved27 0;
BA_ "GenSigTimeoutMsg_HU_A" SG_ 1281 Reserved27 0;
BA_ "GenSigSendType" SG_ 1281 Reserved27 7;
BA_ "GenSigCycleTimeActive" SG_ 1281 Reserved27 200;
BA_ "GenSigCycleTime" SG_ 1281 Reserved27 200;
BA_ "GenSigTimeoutTime_HU_B" SG_ 1281 PartialNetworkInformation_IPC 0;
BA_ "GenSigTimeoutTime_HU_A" SG_ 1281 PartialNetworkInformation_IPC 0;
BA_ "GenSigTimeoutMsg_HU_B" SG_ 1281 PartialNetworkInformation_IPC 0;
BA_ "GenSigTimeoutMsg_HU_A" SG_ 1281 PartialNetworkInformation_IPC 0;
BA_ "GenSigSendType" SG_ 1281 PartialNetworkInformation_IPC 7;
BA_ "GenSigCycleTimeActive" SG_ 1281 PartialNetworkInformation_IPC 200;
BA_ "GenSigCycleTime" SG_ 1281 PartialNetworkInformation_IPC 200;
BA_ "GenSigTimeoutTime_HU_B" SG_ 1281 Reserved26 0;
BA_ "GenSigTimeoutTime_HU_A" SG_ 1281 Reserved26 0;
BA_ "GenSigTimeoutMsg_HU_B" SG_ 1281 Reserved26 0;
BA_ "GenSigTimeoutMsg_HU_A" SG_ 1281 Reserved26 0;
BA_ "GenSigSendType" SG_ 1281 Reserved26 7;
BA_ "GenSigCycleTimeActive" SG_ 1281 Reserved26 200;
BA_ "GenSigCycleTime" SG_ 1281 Reserved26 200;
BA_ "GenSigTimeoutTime_HU_B" SG_ 1281 CurrentState_IPC 0;
BA_ "GenSigTimeoutTime_HU_A" SG_ 1281 CurrentState_IPC 0;
BA_ "GenSigTimeoutMsg_HU_B" SG_ 1281 CurrentState_IPC 0;
BA_ "GenSigTimeoutMsg_HU_A" SG_ 1281 CurrentState_IPC 0;
BA_ "GenSigSendType" SG_ 1281 CurrentState_IPC 7;
BA_ "GenSigCycleTimeActive" SG_ 1281 CurrentState_IPC 200;
BA_ "GenSigCycleTime" SG_ 1281 CurrentState_IPC 200;
BA_ "GenSigTimeoutTime_HU_B" SG_ 1281 PreviousState 0;
BA_ "GenSigTimeoutTime_HU_A" SG_ 1281 PreviousState 0;
BA_ "GenSigTimeoutMsg_HU_B" SG_ 1281 PreviousState 0;
BA_ "GenSigTimeoutMsg_HU_A" SG_ 1281 PreviousState 0;
BA_ "GenSigSendType" SG_ 1281 PreviousState 7;
BA_ "GenSigCycleTimeActive" SG_ 1281 PreviousState 200;
BA_ "GenSigCycleTime" SG_ 1281 PreviousState 200;
BA_ "GenSigTimeoutTime_HU_B" SG_ 1281 Reserved28 0;
BA_ "GenSigTimeoutTime_HU_A" SG_ 1281 Reserved28 0;
BA_ "GenSigTimeoutMsg_HU_B" SG_ 1281 Reserved28 0;
BA_ "GenSigTimeoutMsg_HU_A" SG_ 1281 Reserved28 0;
BA_ "GenSigSendType" SG_ 1281 Reserved28 7;
BA_ "GenSigCycleTimeActive" SG_ 1281 Reserved28 200;
BA_ "GenSigCycleTime" SG_ 1281 Reserved28 200;
BA_ "GenSigTimeoutTime_HU_B" SG_ 1281 Reserved29 0;
BA_ "GenSigTimeoutTime_HU_A" SG_ 1281 Reserved29 0;
BA_ "GenSigTimeoutMsg_HU_B" SG_ 1281 Reserved29 0;
BA_ "GenSigTimeoutMsg_HU_A" SG_ 1281 Reserved29 0;
BA_ "GenSigSendType" SG_ 1281 Reserved29 7;
BA_ "GenSigCycleTimeActive" SG_ 1281 Reserved29 200;
BA_ "GenSigCycleTime" SG_ 1281 Reserved29 200;
BA_ "GenSigTimeoutTime_HU_B" SG_ 1281 Reserved30 0;
BA_ "GenSigTimeoutTime_HU_A" SG_ 1281 Reserved30 0;
BA_ "GenSigTimeoutMsg_HU_B" SG_ 1281 Reserved30 0;
BA_ "GenSigTimeoutMsg_HU_A" SG_ 1281 Reserved30 0;
BA_ "GenSigSendType" SG_ 1281 Reserved30 7;
BA_ "GenSigCycleTimeActive" SG_ 1281 Reserved30 200;
BA_ "GenSigCycleTime" SG_ 1281 Reserved30 200;
BA_ "GenSigTimeoutTime_HU_B" SG_ 1281 Reserved31 0;
BA_ "GenSigTimeoutTime_HU_A" SG_ 1281 Reserved31 0;
BA_ "GenSigTimeoutMsg_HU_B" SG_ 1281 Reserved31 0;
BA_ "GenSigTimeoutMsg_HU_A" SG_ 1281 Reserved31 0;
BA_ "GenSigSendType" SG_ 1281 Reserved31 7;
BA_ "GenSigCycleTimeActive" SG_ 1281 Reserved31 200;
BA_ "GenSigCycleTime" SG_ 1281 Reserved31 200;
BA_ "GenSigTimeoutTime_HU_B" SG_ 1281 IPC_NMPDU_USER_DATA_1 0;
BA_ "GenSigTimeoutTime_HU_A" SG_ 1281 IPC_NMPDU_USER_DATA_1 0;
BA_ "GenSigTimeoutMsg_HU_B" SG_ 1281 IPC_NMPDU_USER_DATA_1 0;
BA_ "GenSigTimeoutMsg_HU_A" SG_ 1281 IPC_NMPDU_USER_DATA_1 0;
BA_ "GenSigSendType" SG_ 1281 IPC_NMPDU_USER_DATA_1 7;
BA_ "GenSigCycleTimeActive" SG_ 1281 IPC_NMPDU_USER_DATA_1 200;
BA_ "GenSigCycleTime" SG_ 1281 IPC_NMPDU_USER_DATA_1 200;
BA_ "GenSigTimeoutTime_HU_B" SG_ 1281 IPC_NMPDU_USER_DATA_2 0;
BA_ "GenSigTimeoutTime_HU_A" SG_ 1281 IPC_NMPDU_USER_DATA_2 0;
BA_ "GenSigTimeoutMsg_HU_B" SG_ 1281 IPC_NMPDU_USER_DATA_2 0;
BA_ "GenSigTimeoutMsg_HU_A" SG_ 1281 IPC_NMPDU_USER_DATA_2 0;
BA_ "GenSigSendType" SG_ 1281 IPC_NMPDU_USER_DATA_2 7;
BA_ "GenSigCycleTimeActive" SG_ 1281 IPC_NMPDU_USER_DATA_2 200;
BA_ "GenSigCycleTime" SG_ 1281 IPC_NMPDU_USER_DATA_2 200;
BA_ "GenSigTimeoutTime_HU_B" SG_ 1281 IPC_NMPDU_USER_DATA_3 0;
BA_ "GenSigTimeoutTime_HU_A" SG_ 1281 IPC_NMPDU_USER_DATA_3 0;
BA_ "GenSigTimeoutMsg_HU_B" SG_ 1281 IPC_NMPDU_USER_DATA_3 0;
BA_ "GenSigTimeoutMsg_HU_A" SG_ 1281 IPC_NMPDU_USER_DATA_3 0;
BA_ "GenSigSendType" SG_ 1281 IPC_NMPDU_USER_DATA_3 7;
BA_ "GenSigCycleTimeActive" SG_ 1281 IPC_NMPDU_USER_DATA_3 200;
BA_ "GenSigCycleTime" SG_ 1281 IPC_NMPDU_USER_DATA_3 200;
BA_ "GenSigTimeoutTime_HU_B" SG_ 1281 IPC_NMPDU_USER_DATA_4 0;
BA_ "GenSigTimeoutTime_HU_A" SG_ 1281 IPC_NMPDU_USER_DATA_4 0;
BA_ "GenSigTimeoutMsg_HU_B" SG_ 1281 IPC_NMPDU_USER_DATA_4 0;
BA_ "GenSigTimeoutMsg_HU_A" SG_ 1281 IPC_NMPDU_USER_DATA_4 0;
BA_ "GenSigSendType" SG_ 1281 IPC_NMPDU_USER_DATA_4 7;
BA_ "GenSigCycleTimeActive" SG_ 1281 IPC_NMPDU_USER_DATA_4 200;
BA_ "GenSigCycleTime" SG_ 1281 IPC_NMPDU_USER_DATA_4 200;
BA_ "GenSigTimeoutTime_HU_B" SG_ 1281 IPC_NMPDU_USER_DATA_5 0;
BA_ "GenSigTimeoutTime_HU_A" SG_ 1281 IPC_NMPDU_USER_DATA_5 0;
BA_ "GenSigTimeoutMsg_HU_B" SG_ 1281 IPC_NMPDU_USER_DATA_5 0;
BA_ "GenSigTimeoutMsg_HU_A" SG_ 1281 IPC_NMPDU_USER_DATA_5 0;
BA_ "GenSigSendType" SG_ 1281 IPC_NMPDU_USER_DATA_5 7;
BA_ "GenSigCycleTimeActive" SG_ 1281 IPC_NMPDU_USER_DATA_5 200;
BA_ "GenSigCycleTime" SG_ 1281 IPC_NMPDU_USER_DATA_5 200;
BA_ "GenSigTimeoutTime_HU_Mid_X451" SG_ 1282 HU_NMPDU_SRC_ECU_ID 1000;
BA_ "GenSigTimeoutTime_HU_High_X451" SG_ 1282 HU_NMPDU_SRC_ECU_ID 1000;
BA_ "GenSigTimeoutTime_HU_B" SG_ 1282 HU_NMPDU_SRC_ECU_ID 1000;
BA_ "GenSigTimeoutTime_HU_A" SG_ 1282 HU_NMPDU_SRC_ECU_ID 1000;
BA_ "GenSigTimeoutMsg_HU_Mid_X451" SG_ 1282 HU_NMPDU_SRC_ECU_ID 1000;
BA_ "GenSigTimeoutMsg_HU_High_X451" SG_ 1282 HU_NMPDU_SRC_ECU_ID 1000;
BA_ "GenSigTimeoutMsg_HU_B" SG_ 1282 HU_NMPDU_SRC_ECU_ID 1000;
BA_ "GenSigTimeoutMsg_HU_A" SG_ 1282 HU_NMPDU_SRC_ECU_ID 1000;
BA_ "GenSigSendType" SG_ 1282 HU_NMPDU_SRC_ECU_ID 7;
BA_ "GenSigCycleTimeActive" SG_ 1282 HU_NMPDU_SRC_ECU_ID 200;
BA_ "GenSigCycleTime" SG_ 1282 HU_NMPDU_SRC_ECU_ID 200;
BA_ "GenSigTimeoutMsg_HU_High_X445" SG_ 1282 HU_NMPDU_SRC_ECU_ID 1000;
BA_ "GenSigTimeoutMsg_HU_Mid_X445" SG_ 1282 HU_NMPDU_SRC_ECU_ID 1000;
BA_ "GenSigTimeoutTime_HU_High_X445" SG_ 1282 HU_NMPDU_SRC_ECU_ID 1000;
BA_ "GenSigTimeoutTime_HU_Mid_X445" SG_ 1282 HU_NMPDU_SRC_ECU_ID 1000;
BA_ "GenSigTimeoutMsg_IVI" SG_ 1282 HU_NMPDU_SRC_ECU_ID 1000;
BA_ "GenSigTimeoutTime_IVI" SG_ 1282 HU_NMPDU_SRC_ECU_ID 1000;
BA_ "GenSigTimeoutTime_HU_Mid_X451" SG_ 1282 RepeatMessageReq_HU 1000;
BA_ "GenSigTimeoutTime_HU_High_X451" SG_ 1282 RepeatMessageReq_HU 1000;
BA_ "GenSigTimeoutTime_HU_B" SG_ 1282 RepeatMessageReq_HU 1000;
BA_ "GenSigTimeoutTime_HU_A" SG_ 1282 RepeatMessageReq_HU 1000;
BA_ "GenSigTimeoutMsg_HU_Mid_X451" SG_ 1282 RepeatMessageReq_HU 1000;
BA_ "GenSigTimeoutMsg_HU_High_X451" SG_ 1282 RepeatMessageReq_HU 1000;
BA_ "GenSigTimeoutMsg_HU_B" SG_ 1282 RepeatMessageReq_HU 1000;
BA_ "GenSigTimeoutMsg_HU_A" SG_ 1282 RepeatMessageReq_HU 1000;
BA_ "GenSigSendType" SG_ 1282 RepeatMessageReq_HU 7;
BA_ "GenSigCycleTimeActive" SG_ 1282 RepeatMessageReq_HU 200;
BA_ "GenSigCycleTime" SG_ 1282 RepeatMessageReq_HU 200;
BA_ "GenSigTimeoutMsg_HU_High_X445" SG_ 1282 RepeatMessageReq_HU 1000;
BA_ "GenSigTimeoutMsg_HU_Mid_X445" SG_ 1282 RepeatMessageReq_HU 1000;
BA_ "GenSigTimeoutTime_HU_High_X445" SG_ 1282 RepeatMessageReq_HU 1000;
BA_ "GenSigTimeoutTime_HU_Mid_X445" SG_ 1282 RepeatMessageReq_HU 1000;
BA_ "GenSigTimeoutMsg_IVI" SG_ 1282 RepeatMessageReq_HU 1000;
BA_ "GenSigTimeoutTime_IVI" SG_ 1282 RepeatMessageReq_HU 1000;
BA_ "GenSigTimeoutTime_HU_Mid_X451" SG_ 1282 Reserved8 1000;
BA_ "GenSigTimeoutTime_HU_High_X451" SG_ 1282 Reserved8 1000;
BA_ "GenSigTimeoutTime_HU_B" SG_ 1282 Reserved8 1000;
BA_ "GenSigTimeoutTime_HU_A" SG_ 1282 Reserved8 1000;
BA_ "GenSigTimeoutMsg_HU_Mid_X451" SG_ 1282 Reserved8 1000;
BA_ "GenSigTimeoutMsg_HU_High_X451" SG_ 1282 Reserved8 1000;
BA_ "GenSigTimeoutMsg_HU_B" SG_ 1282 Reserved8 1000;
BA_ "GenSigTimeoutMsg_HU_A" SG_ 1282 Reserved8 1000;
BA_ "GenSigSendType" SG_ 1282 Reserved8 7;
BA_ "GenSigCycleTimeActive" SG_ 1282 Reserved8 200;
BA_ "GenSigCycleTime" SG_ 1282 Reserved8 200;
BA_ "GenSigTimeoutMsg_HU_High_X445" SG_ 1282 Reserved8 1000;
BA_ "GenSigTimeoutMsg_HU_Mid_X445" SG_ 1282 Reserved8 1000;
BA_ "GenSigTimeoutTime_HU_High_X445" SG_ 1282 Reserved8 1000;
BA_ "GenSigTimeoutTime_HU_Mid_X445" SG_ 1282 Reserved8 1000;
BA_ "GenSigTimeoutMsg_IVI" SG_ 1282 Reserved8 1000;
BA_ "GenSigTimeoutTime_IVI" SG_ 1282 Reserved8 1000;
BA_ "GenSigTimeoutTime_HU_Mid_X451" SG_ 1282 Reserved9 1000;
BA_ "GenSigTimeoutTime_HU_High_X451" SG_ 1282 Reserved9 1000;
BA_ "GenSigTimeoutTime_HU_B" SG_ 1282 Reserved9 1000;
BA_ "GenSigTimeoutTime_HU_A" SG_ 1282 Reserved9 1000;
BA_ "GenSigTimeoutMsg_HU_Mid_X451" SG_ 1282 Reserved9 1000;
BA_ "GenSigTimeoutMsg_HU_High_X451" SG_ 1282 Reserved9 1000;
BA_ "GenSigTimeoutMsg_HU_B" SG_ 1282 Reserved9 1000;
BA_ "GenSigTimeoutMsg_HU_A" SG_ 1282 Reserved9 1000;
BA_ "GenSigSendType" SG_ 1282 Reserved9 7;
BA_ "GenSigCycleTimeActive" SG_ 1282 Reserved9 200;
BA_ "GenSigCycleTime" SG_ 1282 Reserved9 200;
BA_ "GenSigTimeoutMsg_HU_High_X445" SG_ 1282 Reserved9 1000;
BA_ "GenSigTimeoutMsg_HU_Mid_X445" SG_ 1282 Reserved9 1000;
BA_ "GenSigTimeoutTime_HU_High_X445" SG_ 1282 Reserved9 1000;
BA_ "GenSigTimeoutTime_HU_Mid_X445" SG_ 1282 Reserved9 1000;
BA_ "GenSigTimeoutMsg_IVI" SG_ 1282 Reserved9 1000;
BA_ "GenSigTimeoutTime_IVI" SG_ 1282 Reserved9 1000;
BA_ "GenSigTimeoutTime_HU_Mid_X451" SG_ 1282 NMCoOrdSlpReady_HU 1000;
BA_ "GenSigTimeoutTime_HU_High_X451" SG_ 1282 NMCoOrdSlpReady_HU 1000;
BA_ "GenSigTimeoutTime_HU_B" SG_ 1282 NMCoOrdSlpReady_HU 1000;
BA_ "GenSigTimeoutTime_HU_A" SG_ 1282 NMCoOrdSlpReady_HU 1000;
BA_ "GenSigTimeoutMsg_HU_Mid_X451" SG_ 1282 NMCoOrdSlpReady_HU 1000;
BA_ "GenSigTimeoutMsg_HU_High_X451" SG_ 1282 NMCoOrdSlpReady_HU 1000;
BA_ "GenSigTimeoutMsg_HU_B" SG_ 1282 NMCoOrdSlpReady_HU 1000;
BA_ "GenSigTimeoutMsg_HU_A" SG_ 1282 NMCoOrdSlpReady_HU 1000;
BA_ "GenSigSendType" SG_ 1282 NMCoOrdSlpReady_HU 7;
BA_ "GenSigCycleTimeActive" SG_ 1282 NMCoOrdSlpReady_HU 200;
BA_ "GenSigCycleTime" SG_ 1282 NMCoOrdSlpReady_HU 200;
BA_ "GenSigTimeoutMsg_HU_High_X445" SG_ 1282 NMCoOrdSlpReady_HU 1000;
BA_ "GenSigTimeoutMsg_HU_Mid_X445" SG_ 1282 NMCoOrdSlpReady_HU 1000;
BA_ "GenSigTimeoutTime_HU_High_X445" SG_ 1282 NMCoOrdSlpReady_HU 1000;
BA_ "GenSigTimeoutTime_HU_Mid_X445" SG_ 1282 NMCoOrdSlpReady_HU 1000;
BA_ "GenSigTimeoutMsg_IVI" SG_ 1282 NMCoOrdSlpReady_HU 1000;
BA_ "GenSigTimeoutTime_IVI" SG_ 1282 NMCoOrdSlpReady_HU 1000;
BA_ "GenSigTimeoutTime_HU_Mid_X451" SG_ 1282 ActiveWakeUp_HU 1000;
BA_ "GenSigTimeoutTime_HU_High_X451" SG_ 1282 ActiveWakeUp_HU 1000;
BA_ "GenSigTimeoutTime_HU_B" SG_ 1282 ActiveWakeUp_HU 1000;
BA_ "GenSigTimeoutTime_HU_A" SG_ 1282 ActiveWakeUp_HU 1000;
BA_ "GenSigTimeoutMsg_HU_Mid_X451" SG_ 1282 ActiveWakeUp_HU 1000;
BA_ "GenSigTimeoutMsg_HU_High_X451" SG_ 1282 ActiveWakeUp_HU 1000;
BA_ "GenSigTimeoutMsg_HU_B" SG_ 1282 ActiveWakeUp_HU 1000;
BA_ "GenSigTimeoutMsg_HU_A" SG_ 1282 ActiveWakeUp_HU 1000;
BA_ "GenSigSendType" SG_ 1282 ActiveWakeUp_HU 7;
BA_ "GenSigCycleTimeActive" SG_ 1282 ActiveWakeUp_HU 200;
BA_ "GenSigCycleTime" SG_ 1282 ActiveWakeUp_HU 200;
BA_ "GenSigTimeoutMsg_HU_High_X445" SG_ 1282 ActiveWakeUp_HU 1000;
BA_ "GenSigTimeoutMsg_HU_Mid_X445" SG_ 1282 ActiveWakeUp_HU 1000;
BA_ "GenSigTimeoutTime_HU_High_X445" SG_ 1282 ActiveWakeUp_HU 1000;
BA_ "GenSigTimeoutTime_HU_Mid_X445" SG_ 1282 ActiveWakeUp_HU 1000;
BA_ "GenSigTimeoutMsg_IVI" SG_ 1282 ActiveWakeUp_HU 1000;
BA_ "GenSigTimeoutTime_IVI" SG_ 1282 ActiveWakeUp_HU 1000;
BA_ "GenSigTimeoutTime_HU_Mid_X451" SG_ 1282 Reserved10 1000;
BA_ "GenSigTimeoutTime_HU_High_X451" SG_ 1282 Reserved10 1000;
BA_ "GenSigTimeoutTime_HU_B" SG_ 1282 Reserved10 1000;
BA_ "GenSigTimeoutTime_HU_A" SG_ 1282 Reserved10 1000;
BA_ "GenSigTimeoutMsg_HU_Mid_X451" SG_ 1282 Reserved10 1000;
BA_ "GenSigTimeoutMsg_HU_High_X451" SG_ 1282 Reserved10 1000;
BA_ "GenSigTimeoutMsg_HU_B" SG_ 1282 Reserved10 1000;
BA_ "GenSigTimeoutMsg_HU_A" SG_ 1282 Reserved10 1000;
BA_ "GenSigSendType" SG_ 1282 Reserved10 7;
BA_ "GenSigCycleTimeActive" SG_ 1282 Reserved10 200;
BA_ "GenSigCycleTime" SG_ 1282 Reserved10 200;
BA_ "GenSigTimeoutMsg_HU_High_X445" SG_ 1282 Reserved10 1000;
BA_ "GenSigTimeoutMsg_HU_Mid_X445" SG_ 1282 Reserved10 1000;
BA_ "GenSigTimeoutTime_HU_High_X445" SG_ 1282 Reserved10 1000;
BA_ "GenSigTimeoutTime_HU_Mid_X445" SG_ 1282 Reserved10 1000;
BA_ "GenSigTimeoutMsg_IVI" SG_ 1282 Reserved10 1000;
BA_ "GenSigTimeoutTime_IVI" SG_ 1282 Reserved10 1000;
BA_ "GenSigTimeoutTime_HU_Mid_X451" SG_ 1282 PartialNetworkInformation_HU 1000;
BA_ "GenSigTimeoutTime_HU_High_X451" SG_ 1282 PartialNetworkInformation_HU 1000;
BA_ "GenSigTimeoutTime_HU_B" SG_ 1282 PartialNetworkInformation_HU 1000;
BA_ "GenSigTimeoutTime_HU_A" SG_ 1282 PartialNetworkInformation_HU 1000;
BA_ "GenSigTimeoutMsg_HU_Mid_X451" SG_ 1282 PartialNetworkInformation_HU 1000;
BA_ "GenSigTimeoutMsg_HU_High_X451" SG_ 1282 PartialNetworkInformation_HU 1000;
BA_ "GenSigTimeoutMsg_HU_B" SG_ 1282 PartialNetworkInformation_HU 1000;
BA_ "GenSigTimeoutMsg_HU_A" SG_ 1282 PartialNetworkInformation_HU 1000;
BA_ "GenSigSendType" SG_ 1282 PartialNetworkInformation_HU 7;
BA_ "GenSigCycleTimeActive" SG_ 1282 PartialNetworkInformation_HU 200;
BA_ "GenSigCycleTime" SG_ 1282 PartialNetworkInformation_HU 200;
BA_ "GenSigTimeoutMsg_HU_High_X445" SG_ 1282 PartialNetworkInformation_HU 1000;
BA_ "GenSigTimeoutMsg_HU_Mid_X445" SG_ 1282 PartialNetworkInformation_HU 1000;
BA_ "GenSigTimeoutTime_HU_High_X445" SG_ 1282 PartialNetworkInformation_HU 1000;
BA_ "GenSigTimeoutTime_HU_Mid_X445" SG_ 1282 PartialNetworkInformation_HU 1000;
BA_ "GenSigTimeoutMsg_IVI" SG_ 1282 PartialNetworkInformation_HU 1000;
BA_ "GenSigTimeoutTime_IVI" SG_ 1282 PartialNetworkInformation_HU 1000;
BA_ "GenSigTimeoutTime_HU_Mid_X451" SG_ 1282 Reserved11 1000;
BA_ "GenSigTimeoutTime_HU_High_X451" SG_ 1282 Reserved11 1000;
BA_ "GenSigTimeoutTime_HU_B" SG_ 1282 Reserved11 1000;
BA_ "GenSigTimeoutTime_HU_A" SG_ 1282 Reserved11 1000;
BA_ "GenSigTimeoutMsg_HU_Mid_X451" SG_ 1282 Reserved11 1000;
BA_ "GenSigTimeoutMsg_HU_High_X451" SG_ 1282 Reserved11 1000;
BA_ "GenSigTimeoutMsg_HU_B" SG_ 1282 Reserved11 1000;
BA_ "GenSigTimeoutMsg_HU_A" SG_ 1282 Reserved11 1000;
BA_ "GenSigSendType" SG_ 1282 Reserved11 7;
BA_ "GenSigCycleTimeActive" SG_ 1282 Reserved11 200;
BA_ "GenSigCycleTime" SG_ 1282 Reserved11 200;
BA_ "GenSigTimeoutMsg_HU_High_X445" SG_ 1282 Reserved11 1000;
BA_ "GenSigTimeoutMsg_HU_Mid_X445" SG_ 1282 Reserved11 1000;
BA_ "GenSigTimeoutTime_HU_High_X445" SG_ 1282 Reserved11 1000;
BA_ "GenSigTimeoutTime_HU_Mid_X445" SG_ 1282 Reserved11 1000;
BA_ "GenSigTimeoutMsg_IVI" SG_ 1282 Reserved11 1000;
BA_ "GenSigTimeoutTime_IVI" SG_ 1282 Reserved11 1000;
BA_ "GenSigTimeoutTime_HU_Mid_X451" SG_ 1282 CurrentState_HU 1000;
BA_ "GenSigTimeoutTime_HU_High_X451" SG_ 1282 CurrentState_HU 1000;
BA_ "GenSigTimeoutTime_HU_B" SG_ 1282 CurrentState_HU 1000;
BA_ "GenSigTimeoutTime_HU_A" SG_ 1282 CurrentState_HU 1000;
BA_ "GenSigTimeoutMsg_HU_Mid_X451" SG_ 1282 CurrentState_HU 1000;
BA_ "GenSigTimeoutMsg_HU_High_X451" SG_ 1282 CurrentState_HU 1000;
BA_ "GenSigTimeoutMsg_HU_B" SG_ 1282 CurrentState_HU 1000;
BA_ "GenSigTimeoutMsg_HU_A" SG_ 1282 CurrentState_HU 1000;
BA_ "GenSigSendType" SG_ 1282 CurrentState_HU 7;
BA_ "GenSigCycleTimeActive" SG_ 1282 CurrentState_HU 200;
BA_ "GenSigCycleTime" SG_ 1282 CurrentState_HU 200;
BA_ "GenSigTimeoutMsg_HU_High_X445" SG_ 1282 CurrentState_HU 1000;
BA_ "GenSigTimeoutMsg_HU_Mid_X445" SG_ 1282 CurrentState_HU 1000;
BA_ "GenSigTimeoutTime_HU_High_X445" SG_ 1282 CurrentState_HU 1000;
BA_ "GenSigTimeoutTime_HU_Mid_X445" SG_ 1282 CurrentState_HU 1000;
BA_ "GenSigTimeoutMsg_IVI" SG_ 1282 CurrentState_HU 1000;
BA_ "GenSigTimeoutTime_IVI" SG_ 1282 CurrentState_HU 1000;
BA_ "GenSigTimeoutTime_HU_Mid_X451" SG_ 1282 PreviousState_HU 1000;
BA_ "GenSigTimeoutTime_HU_High_X451" SG_ 1282 PreviousState_HU 1000;
BA_ "GenSigTimeoutTime_HU_B" SG_ 1282 PreviousState_HU 1000;
BA_ "GenSigTimeoutTime_HU_A" SG_ 1282 PreviousState_HU 1000;
BA_ "GenSigTimeoutMsg_HU_Mid_X451" SG_ 1282 PreviousState_HU 1000;
BA_ "GenSigTimeoutMsg_HU_High_X451" SG_ 1282 PreviousState_HU 1000;
BA_ "GenSigTimeoutMsg_HU_B" SG_ 1282 PreviousState_HU 1000;
BA_ "GenSigTimeoutMsg_HU_A" SG_ 1282 PreviousState_HU 1000;
BA_ "GenSigSendType" SG_ 1282 PreviousState_HU 7;
BA_ "GenSigCycleTimeActive" SG_ 1282 PreviousState_HU 200;
BA_ "GenSigCycleTime" SG_ 1282 PreviousState_HU 200;
BA_ "GenSigTimeoutMsg_HU_High_X445" SG_ 1282 PreviousState_HU 1000;
BA_ "GenSigTimeoutMsg_HU_Mid_X445" SG_ 1282 PreviousState_HU 1000;
BA_ "GenSigTimeoutTime_HU_High_X445" SG_ 1282 PreviousState_HU 1000;
BA_ "GenSigTimeoutTime_HU_Mid_X445" SG_ 1282 PreviousState_HU 1000;
BA_ "GenSigTimeoutMsg_IVI" SG_ 1282 PreviousState_HU 1000;
BA_ "GenSigTimeoutTime_IVI" SG_ 1282 PreviousState_HU 1000;
BA_ "GenSigTimeoutTime_HU_Mid_X451" SG_ 1282 Reserved12 1000;
BA_ "GenSigTimeoutTime_HU_High_X451" SG_ 1282 Reserved12 1000;
BA_ "GenSigTimeoutTime_HU_B" SG_ 1282 Reserved12 1000;
BA_ "GenSigTimeoutTime_HU_A" SG_ 1282 Reserved12 1000;
BA_ "GenSigTimeoutMsg_HU_Mid_X451" SG_ 1282 Reserved12 1000;
BA_ "GenSigTimeoutMsg_HU_High_X451" SG_ 1282 Reserved12 1000;
BA_ "GenSigTimeoutMsg_HU_B" SG_ 1282 Reserved12 1000;
BA_ "GenSigTimeoutMsg_HU_A" SG_ 1282 Reserved12 1000;
BA_ "GenSigSendType" SG_ 1282 Reserved12 7;
BA_ "GenSigCycleTimeActive" SG_ 1282 Reserved12 200;
BA_ "GenSigCycleTime" SG_ 1282 Reserved12 200;
BA_ "GenSigTimeoutMsg_HU_High_X445" SG_ 1282 Reserved12 1000;
BA_ "GenSigTimeoutMsg_HU_Mid_X445" SG_ 1282 Reserved12 1000;
BA_ "GenSigTimeoutTime_HU_High_X445" SG_ 1282 Reserved12 1000;
BA_ "GenSigTimeoutTime_HU_Mid_X445" SG_ 1282 Reserved12 1000;
BA_ "GenSigTimeoutMsg_IVI" SG_ 1282 Reserved12 1000;
BA_ "GenSigTimeoutTime_IVI" SG_ 1282 Reserved12 1000;
BA_ "GenSigTimeoutTime_HU_Mid_X451" SG_ 1282 Reserved13 1000;
BA_ "GenSigTimeoutTime_HU_High_X451" SG_ 1282 Reserved13 1000;
BA_ "GenSigTimeoutTime_HU_B" SG_ 1282 Reserved13 1000;
BA_ "GenSigTimeoutTime_HU_A" SG_ 1282 Reserved13 1000;
BA_ "GenSigTimeoutMsg_HU_Mid_X451" SG_ 1282 Reserved13 1000;
BA_ "GenSigTimeoutMsg_HU_High_X451" SG_ 1282 Reserved13 1000;
BA_ "GenSigTimeoutMsg_HU_B" SG_ 1282 Reserved13 1000;
BA_ "GenSigTimeoutMsg_HU_A" SG_ 1282 Reserved13 1000;
BA_ "GenSigSendType" SG_ 1282 Reserved13 7;
BA_ "GenSigCycleTimeActive" SG_ 1282 Reserved13 200;
BA_ "GenSigCycleTime" SG_ 1282 Reserved13 200;
BA_ "GenSigTimeoutMsg_HU_High_X445" SG_ 1282 Reserved13 1000;
BA_ "GenSigTimeoutMsg_HU_Mid_X445" SG_ 1282 Reserved13 1000;
BA_ "GenSigTimeoutTime_HU_High_X445" SG_ 1282 Reserved13 1000;
BA_ "GenSigTimeoutTime_HU_Mid_X445" SG_ 1282 Reserved13 1000;
BA_ "GenSigTimeoutMsg_IVI" SG_ 1282 Reserved13 1000;
BA_ "GenSigTimeoutTime_IVI" SG_ 1282 Reserved13 1000;
BA_ "GenSigTimeoutTime_HU_Mid_X451" SG_ 1282 Reserved14 1000;
BA_ "GenSigTimeoutTime_HU_High_X451" SG_ 1282 Reserved14 1000;
BA_ "GenSigTimeoutTime_HU_B" SG_ 1282 Reserved14 1000;
BA_ "GenSigTimeoutTime_HU_A" SG_ 1282 Reserved14 1000;
BA_ "GenSigTimeoutMsg_HU_Mid_X451" SG_ 1282 Reserved14 1000;
BA_ "GenSigTimeoutMsg_HU_High_X451" SG_ 1282 Reserved14 1000;
BA_ "GenSigTimeoutMsg_HU_B" SG_ 1282 Reserved14 1000;
BA_ "GenSigTimeoutMsg_HU_A" SG_ 1282 Reserved14 1000;
BA_ "GenSigSendType" SG_ 1282 Reserved14 7;
BA_ "GenSigCycleTimeActive" SG_ 1282 Reserved14 200;
BA_ "GenSigCycleTime" SG_ 1282 Reserved14 200;
BA_ "GenSigTimeoutMsg_HU_High_X445" SG_ 1282 Reserved14 1000;
BA_ "GenSigTimeoutMsg_HU_Mid_X445" SG_ 1282 Reserved14 1000;
BA_ "GenSigTimeoutTime_HU_High_X445" SG_ 1282 Reserved14 1000;
BA_ "GenSigTimeoutTime_HU_Mid_X445" SG_ 1282 Reserved14 1000;
BA_ "GenSigTimeoutMsg_IVI" SG_ 1282 Reserved14 1000;
BA_ "GenSigTimeoutTime_IVI" SG_ 1282 Reserved14 1000;
BA_ "GenSigTimeoutTime_HU_Mid_X451" SG_ 1282 Reserved15 1000;
BA_ "GenSigTimeoutTime_HU_High_X451" SG_ 1282 Reserved15 1000;
BA_ "GenSigTimeoutTime_HU_B" SG_ 1282 Reserved15 1000;
BA_ "GenSigTimeoutTime_HU_A" SG_ 1282 Reserved15 1000;
BA_ "GenSigTimeoutMsg_HU_Mid_X451" SG_ 1282 Reserved15 1000;
BA_ "GenSigTimeoutMsg_HU_High_X451" SG_ 1282 Reserved15 1000;
BA_ "GenSigTimeoutMsg_HU_B" SG_ 1282 Reserved15 1000;
BA_ "GenSigTimeoutMsg_HU_A" SG_ 1282 Reserved15 1000;
BA_ "GenSigSendType" SG_ 1282 Reserved15 7;
BA_ "GenSigCycleTimeActive" SG_ 1282 Reserved15 200;
BA_ "GenSigCycleTime" SG_ 1282 Reserved15 200;
BA_ "GenSigTimeoutMsg_HU_High_X445" SG_ 1282 Reserved15 1000;
BA_ "GenSigTimeoutMsg_HU_Mid_X445" SG_ 1282 Reserved15 1000;
BA_ "GenSigTimeoutTime_HU_High_X445" SG_ 1282 Reserved15 1000;
BA_ "GenSigTimeoutTime_HU_Mid_X445" SG_ 1282 Reserved15 1000;
BA_ "GenSigTimeoutMsg_IVI" SG_ 1282 Reserved15 1000;
BA_ "GenSigTimeoutTime_IVI" SG_ 1282 Reserved15 1000;
BA_ "GenSigTimeoutTime_HU_Mid_X451" SG_ 1282 HU_NMPDU_USER_DATA_1 1000;
BA_ "GenSigTimeoutTime_HU_High_X451" SG_ 1282 HU_NMPDU_USER_DATA_1 1000;
BA_ "GenSigTimeoutTime_HU_B" SG_ 1282 HU_NMPDU_USER_DATA_1 1000;
BA_ "GenSigTimeoutTime_HU_A" SG_ 1282 HU_NMPDU_USER_DATA_1 1000;
BA_ "GenSigTimeoutMsg_HU_Mid_X451" SG_ 1282 HU_NMPDU_USER_DATA_1 1000;
BA_ "GenSigTimeoutMsg_HU_High_X451" SG_ 1282 HU_NMPDU_USER_DATA_1 1000;
BA_ "GenSigTimeoutMsg_HU_B" SG_ 1282 HU_NMPDU_USER_DATA_1 1000;
BA_ "GenSigTimeoutMsg_HU_A" SG_ 1282 HU_NMPDU_USER_DATA_1 1000;
BA_ "GenSigSendType" SG_ 1282 HU_NMPDU_USER_DATA_1 7;
BA_ "GenSigCycleTimeActive" SG_ 1282 HU_NMPDU_USER_DATA_1 200;
BA_ "GenSigCycleTime" SG_ 1282 HU_NMPDU_USER_DATA_1 200;
BA_ "GenSigTimeoutMsg_HU_High_X445" SG_ 1282 HU_NMPDU_USER_DATA_1 1000;
BA_ "GenSigTimeoutMsg_HU_Mid_X445" SG_ 1282 HU_NMPDU_USER_DATA_1 1000;
BA_ "GenSigTimeoutTime_HU_High_X445" SG_ 1282 HU_NMPDU_USER_DATA_1 1000;
BA_ "GenSigTimeoutTime_HU_Mid_X445" SG_ 1282 HU_NMPDU_USER_DATA_1 1000;
BA_ "GenSigTimeoutMsg_IVI" SG_ 1282 HU_NMPDU_USER_DATA_1 1000;
BA_ "GenSigTimeoutTime_IVI" SG_ 1282 HU_NMPDU_USER_DATA_1 1000;
BA_ "GenSigTimeoutTime_HU_Mid_X451" SG_ 1282 HU_NMPDU_USER_DATA_2 1000;
BA_ "GenSigTimeoutTime_HU_High_X451" SG_ 1282 HU_NMPDU_USER_DATA_2 1000;
BA_ "GenSigTimeoutTime_HU_B" SG_ 1282 HU_NMPDU_USER_DATA_2 1000;
BA_ "GenSigTimeoutTime_HU_A" SG_ 1282 HU_NMPDU_USER_DATA_2 1000;
BA_ "GenSigTimeoutMsg_HU_Mid_X451" SG_ 1282 HU_NMPDU_USER_DATA_2 1000;
BA_ "GenSigTimeoutMsg_HU_High_X451" SG_ 1282 HU_NMPDU_USER_DATA_2 1000;
BA_ "GenSigTimeoutMsg_HU_B" SG_ 1282 HU_NMPDU_USER_DATA_2 1000;
BA_ "GenSigTimeoutMsg_HU_A" SG_ 1282 HU_NMPDU_USER_DATA_2 1000;
BA_ "GenSigSendType" SG_ 1282 HU_NMPDU_USER_DATA_2 7;
BA_ "GenSigCycleTimeActive" SG_ 1282 HU_NMPDU_USER_DATA_2 200;
BA_ "GenSigCycleTime" SG_ 1282 HU_NMPDU_USER_DATA_2 200;
BA_ "GenSigTimeoutMsg_HU_High_X445" SG_ 1282 HU_NMPDU_USER_DATA_2 1000;
BA_ "GenSigTimeoutMsg_HU_Mid_X445" SG_ 1282 HU_NMPDU_USER_DATA_2 1000;
BA_ "GenSigTimeoutTime_HU_High_X445" SG_ 1282 HU_NMPDU_USER_DATA_2 1000;
BA_ "GenSigTimeoutTime_HU_Mid_X445" SG_ 1282 HU_NMPDU_USER_DATA_2 1000;
BA_ "GenSigTimeoutMsg_IVI" SG_ 1282 HU_NMPDU_USER_DATA_2 1000;
BA_ "GenSigTimeoutTime_IVI" SG_ 1282 HU_NMPDU_USER_DATA_2 1000;
BA_ "GenSigTimeoutTime_HU_Mid_X451" SG_ 1282 HU_NMPDU_USER_DATA_3 1000;
BA_ "GenSigTimeoutTime_HU_High_X451" SG_ 1282 HU_NMPDU_USER_DATA_3 1000;
BA_ "GenSigTimeoutTime_HU_B" SG_ 1282 HU_NMPDU_USER_DATA_3 1000;
BA_ "GenSigTimeoutTime_HU_A" SG_ 1282 HU_NMPDU_USER_DATA_3 1000;
BA_ "GenSigTimeoutMsg_HU_Mid_X451" SG_ 1282 HU_NMPDU_USER_DATA_3 1000;
BA_ "GenSigTimeoutMsg_HU_High_X451" SG_ 1282 HU_NMPDU_USER_DATA_3 1000;
BA_ "GenSigTimeoutMsg_HU_B" SG_ 1282 HU_NMPDU_USER_DATA_3 1000;
BA_ "GenSigTimeoutMsg_HU_A" SG_ 1282 HU_NMPDU_USER_DATA_3 1000;
BA_ "GenSigSendType" SG_ 1282 HU_NMPDU_USER_DATA_3 7;
BA_ "GenSigCycleTimeActive" SG_ 1282 HU_NMPDU_USER_DATA_3 200;
BA_ "GenSigCycleTime" SG_ 1282 HU_NMPDU_USER_DATA_3 200;
BA_ "GenSigTimeoutMsg_HU_High_X445" SG_ 1282 HU_NMPDU_USER_DATA_3 1000;
BA_ "GenSigTimeoutMsg_HU_Mid_X445" SG_ 1282 HU_NMPDU_USER_DATA_3 1000;
BA_ "GenSigTimeoutTime_HU_High_X445" SG_ 1282 HU_NMPDU_USER_DATA_3 1000;
BA_ "GenSigTimeoutTime_HU_Mid_X445" SG_ 1282 HU_NMPDU_USER_DATA_3 1000;
BA_ "GenSigTimeoutMsg_IVI" SG_ 1282 HU_NMPDU_USER_DATA_3 1000;
BA_ "GenSigTimeoutTime_IVI" SG_ 1282 HU_NMPDU_USER_DATA_3 1000;
BA_ "GenSigTimeoutTime_HU_Mid_X451" SG_ 1282 HU_NMPDU_USER_DATA_4 1000;
BA_ "GenSigTimeoutTime_HU_High_X451" SG_ 1282 HU_NMPDU_USER_DATA_4 1000;
BA_ "GenSigTimeoutTime_HU_B" SG_ 1282 HU_NMPDU_USER_DATA_4 1000;
BA_ "GenSigTimeoutTime_HU_A" SG_ 1282 HU_NMPDU_USER_DATA_4 1000;
BA_ "GenSigTimeoutMsg_HU_Mid_X451" SG_ 1282 HU_NMPDU_USER_DATA_4 1000;
BA_ "GenSigTimeoutMsg_HU_High_X451" SG_ 1282 HU_NMPDU_USER_DATA_4 1000;
BA_ "GenSigTimeoutMsg_HU_B" SG_ 1282 HU_NMPDU_USER_DATA_4 1000;
BA_ "GenSigTimeoutMsg_HU_A" SG_ 1282 HU_NMPDU_USER_DATA_4 1000;
BA_ "GenSigSendType" SG_ 1282 HU_NMPDU_USER_DATA_4 7;
BA_ "GenSigCycleTimeActive" SG_ 1282 HU_NMPDU_USER_DATA_4 200;
BA_ "GenSigCycleTime" SG_ 1282 HU_NMPDU_USER_DATA_4 200;
BA_ "GenSigTimeoutMsg_HU_High_X445" SG_ 1282 HU_NMPDU_USER_DATA_4 1000;
BA_ "GenSigTimeoutMsg_HU_Mid_X445" SG_ 1282 HU_NMPDU_USER_DATA_4 1000;
BA_ "GenSigTimeoutTime_HU_High_X445" SG_ 1282 HU_NMPDU_USER_DATA_4 1000;
BA_ "GenSigTimeoutTime_HU_Mid_X445" SG_ 1282 HU_NMPDU_USER_DATA_4 1000;
BA_ "GenSigTimeoutMsg_IVI" SG_ 1282 HU_NMPDU_USER_DATA_4 1000;
BA_ "GenSigTimeoutTime_IVI" SG_ 1282 HU_NMPDU_USER_DATA_4 1000;
BA_ "GenSigTimeoutTime_HU_Mid_X451" SG_ 1282 HU_NMPDU_USER_DATA_5 1000;
BA_ "GenSigTimeoutTime_HU_High_X451" SG_ 1282 HU_NMPDU_USER_DATA_5 1000;
BA_ "GenSigTimeoutTime_HU_B" SG_ 1282 HU_NMPDU_USER_DATA_5 1000;
BA_ "GenSigTimeoutTime_HU_A" SG_ 1282 HU_NMPDU_USER_DATA_5 1000;
BA_ "GenSigTimeoutMsg_HU_Mid_X451" SG_ 1282 HU_NMPDU_USER_DATA_5 1000;
BA_ "GenSigTimeoutMsg_HU_High_X451" SG_ 1282 HU_NMPDU_USER_DATA_5 1000;
BA_ "GenSigTimeoutMsg_HU_B" SG_ 1282 HU_NMPDU_USER_DATA_5 1000;
BA_ "GenSigTimeoutMsg_HU_A" SG_ 1282 HU_NMPDU_USER_DATA_5 1000;
BA_ "GenSigSendType" SG_ 1282 HU_NMPDU_USER_DATA_5 7;
BA_ "GenSigCycleTimeActive" SG_ 1282 HU_NMPDU_USER_DATA_5 200;
BA_ "GenSigCycleTime" SG_ 1282 HU_NMPDU_USER_DATA_5 200;
BA_ "GenSigTimeoutMsg_HU_High_X445" SG_ 1282 HU_NMPDU_USER_DATA_5 1000;
BA_ "GenSigTimeoutMsg_HU_Mid_X445" SG_ 1282 HU_NMPDU_USER_DATA_5 1000;
BA_ "GenSigTimeoutTime_HU_High_X445" SG_ 1282 HU_NMPDU_USER_DATA_5 1000;
BA_ "GenSigTimeoutTime_HU_Mid_X445" SG_ 1282 HU_NMPDU_USER_DATA_5 1000;
BA_ "GenSigTimeoutMsg_IVI" SG_ 1282 HU_NMPDU_USER_DATA_5 1000;
BA_ "GenSigTimeoutTime_IVI" SG_ 1282 HU_NMPDU_USER_DATA_5 1000;
BA_ "GenSigTimeoutTime_HU_B" SG_ 1285 GSS_NMPDU_SRC_ECU_ID 0;
BA_ "GenSigTimeoutTime_HU_A" SG_ 1285 GSS_NMPDU_SRC_ECU_ID 0;
BA_ "GenSigTimeoutMsg_HU_B" SG_ 1285 GSS_NMPDU_SRC_ECU_ID 0;
BA_ "GenSigTimeoutMsg_HU_A" SG_ 1285 GSS_NMPDU_SRC_ECU_ID 0;
BA_ "GenSigSendType" SG_ 1285 GSS_NMPDU_SRC_ECU_ID 7;
BA_ "GenSigCycleTimeActive" SG_ 1285 GSS_NMPDU_SRC_ECU_ID 200;
BA_ "GenSigCycleTime" SG_ 1285 GSS_NMPDU_SRC_ECU_ID 200;
BA_ "GenSigTimeoutTime_HU_B" SG_ 1285 RepeatMessageReq_GSS 0;
BA_ "GenSigTimeoutTime_HU_A" SG_ 1285 RepeatMessageReq_GSS 0;
BA_ "GenSigTimeoutMsg_HU_B" SG_ 1285 RepeatMessageReq_GSS 0;
BA_ "GenSigTimeoutMsg_HU_A" SG_ 1285 RepeatMessageReq_GSS 0;
BA_ "GenSigSendType" SG_ 1285 RepeatMessageReq_GSS 7;
BA_ "GenSigCycleTimeActive" SG_ 1285 RepeatMessageReq_GSS 200;
BA_ "GenSigCycleTime" SG_ 1285 RepeatMessageReq_GSS 200;
BA_ "GenSigTimeoutTime_HU_B" SG_ 1285 Reserved39 0;
BA_ "GenSigTimeoutTime_HU_A" SG_ 1285 Reserved39 0;
BA_ "GenSigTimeoutMsg_HU_B" SG_ 1285 Reserved39 0;
BA_ "GenSigTimeoutMsg_HU_A" SG_ 1285 Reserved39 0;
BA_ "GenSigSendType" SG_ 1285 Reserved39 7;
BA_ "GenSigCycleTimeActive" SG_ 1285 Reserved39 200;
BA_ "GenSigCycleTime" SG_ 1285 Reserved39 200;
BA_ "GenSigTimeoutTime_HU_B" SG_ 1285 Reserved38 0;
BA_ "GenSigTimeoutTime_HU_A" SG_ 1285 Reserved38 0;
BA_ "GenSigTimeoutMsg_HU_B" SG_ 1285 Reserved38 0;
BA_ "GenSigTimeoutMsg_HU_A" SG_ 1285 Reserved38 0;
BA_ "GenSigSendType" SG_ 1285 Reserved38 7;
BA_ "GenSigCycleTimeActive" SG_ 1285 Reserved38 200;
BA_ "GenSigCycleTime" SG_ 1285 Reserved38 200;
BA_ "GenSigTimeoutTime_HU_B" SG_ 1285 NMCoOrdSlpReady_GSS 0;
BA_ "GenSigTimeoutTime_HU_A" SG_ 1285 NMCoOrdSlpReady_GSS 0;
BA_ "GenSigTimeoutMsg_HU_B" SG_ 1285 NMCoOrdSlpReady_GSS 0;
BA_ "GenSigTimeoutMsg_HU_A" SG_ 1285 NMCoOrdSlpReady_GSS 0;
BA_ "GenSigSendType" SG_ 1285 NMCoOrdSlpReady_GSS 7;
BA_ "GenSigCycleTimeActive" SG_ 1285 NMCoOrdSlpReady_GSS 200;
BA_ "GenSigCycleTime" SG_ 1285 NMCoOrdSlpReady_GSS 200;
BA_ "GenSigTimeoutTime_HU_B" SG_ 1285 ActiveWakeUp_GSS 0;
BA_ "GenSigTimeoutTime_HU_A" SG_ 1285 ActiveWakeUp_GSS 0;
BA_ "GenSigTimeoutMsg_HU_B" SG_ 1285 ActiveWakeUp_GSS 0;
BA_ "GenSigTimeoutMsg_HU_A" SG_ 1285 ActiveWakeUp_GSS 0;
BA_ "GenSigSendType" SG_ 1285 ActiveWakeUp_GSS 7;
BA_ "GenSigCycleTimeActive" SG_ 1285 ActiveWakeUp_GSS 200;
BA_ "GenSigCycleTime" SG_ 1285 ActiveWakeUp_GSS 200;
BA_ "GenSigTimeoutTime_HU_B" SG_ 1285 Reserved37 0;
BA_ "GenSigTimeoutTime_HU_A" SG_ 1285 Reserved37 0;
BA_ "GenSigTimeoutMsg_HU_B" SG_ 1285 Reserved37 0;
BA_ "GenSigTimeoutMsg_HU_A" SG_ 1285 Reserved37 0;
BA_ "GenSigSendType" SG_ 1285 Reserved37 7;
BA_ "GenSigCycleTimeActive" SG_ 1285 Reserved37 200;
BA_ "GenSigCycleTime" SG_ 1285 Reserved37 200;
BA_ "GenSigTimeoutTime_HU_B" SG_ 1285 PartialNetworkInformation_GSS 0;
BA_ "GenSigTimeoutTime_HU_A" SG_ 1285 PartialNetworkInformation_GSS 0;
BA_ "GenSigTimeoutMsg_HU_B" SG_ 1285 PartialNetworkInformation_GSS 0;
BA_ "GenSigTimeoutMsg_HU_A" SG_ 1285 PartialNetworkInformation_GSS 0;
BA_ "GenSigSendType" SG_ 1285 PartialNetworkInformation_GSS 7;
BA_ "GenSigCycleTimeActive" SG_ 1285 PartialNetworkInformation_GSS 200;
BA_ "GenSigCycleTime" SG_ 1285 PartialNetworkInformation_GSS 200;
BA_ "GenSigTimeoutTime_HU_B" SG_ 1285 Reserved36 0;
BA_ "GenSigTimeoutTime_HU_A" SG_ 1285 Reserved36 0;
BA_ "GenSigTimeoutMsg_HU_B" SG_ 1285 Reserved36 0;
BA_ "GenSigTimeoutMsg_HU_A" SG_ 1285 Reserved36 0;
BA_ "GenSigSendType" SG_ 1285 Reserved36 7;
BA_ "GenSigCycleTimeActive" SG_ 1285 Reserved36 200;
BA_ "GenSigCycleTime" SG_ 1285 Reserved36 200;
BA_ "GenSigTimeoutTime_HU_B" SG_ 1285 CurrentState_GSS 0;
BA_ "GenSigTimeoutTime_HU_A" SG_ 1285 CurrentState_GSS 0;
BA_ "GenSigTimeoutMsg_HU_B" SG_ 1285 CurrentState_GSS 0;
BA_ "GenSigTimeoutMsg_HU_A" SG_ 1285 CurrentState_GSS 0;
BA_ "GenSigSendType" SG_ 1285 CurrentState_GSS 7;
BA_ "GenSigCycleTimeActive" SG_ 1285 CurrentState_GSS 200;
BA_ "GenSigCycleTime" SG_ 1285 CurrentState_GSS 200;
BA_ "GenSigTimeoutTime_HU_B" SG_ 1285 PreviousState_GSS 0;
BA_ "GenSigTimeoutTime_HU_A" SG_ 1285 PreviousState_GSS 0;
BA_ "GenSigTimeoutMsg_HU_B" SG_ 1285 PreviousState_GSS 0;
BA_ "GenSigTimeoutMsg_HU_A" SG_ 1285 PreviousState_GSS 0;
BA_ "GenSigSendType" SG_ 1285 PreviousState_GSS 7;
BA_ "GenSigCycleTimeActive" SG_ 1285 PreviousState_GSS 200;
BA_ "GenSigCycleTime" SG_ 1285 PreviousState_GSS 200;
BA_ "GenSigTimeoutTime_HU_B" SG_ 1285 Reserved35 0;
BA_ "GenSigTimeoutTime_HU_A" SG_ 1285 Reserved35 0;
BA_ "GenSigTimeoutMsg_HU_B" SG_ 1285 Reserved35 0;
BA_ "GenSigTimeoutMsg_HU_A" SG_ 1285 Reserved35 0;
BA_ "GenSigSendType" SG_ 1285 Reserved35 7;
BA_ "GenSigCycleTimeActive" SG_ 1285 Reserved35 200;
BA_ "GenSigCycleTime" SG_ 1285 Reserved35 200;
BA_ "GenSigTimeoutTime_HU_B" SG_ 1285 Reserved34 0;
BA_ "GenSigTimeoutTime_HU_A" SG_ 1285 Reserved34 0;
BA_ "GenSigTimeoutMsg_HU_B" SG_ 1285 Reserved34 0;
BA_ "GenSigTimeoutMsg_HU_A" SG_ 1285 Reserved34 0;
BA_ "GenSigSendType" SG_ 1285 Reserved34 7;
BA_ "GenSigCycleTimeActive" SG_ 1285 Reserved34 200;
BA_ "GenSigCycleTime" SG_ 1285 Reserved34 200;
BA_ "GenSigTimeoutTime_HU_B" SG_ 1285 Reserved33 0;
BA_ "GenSigTimeoutTime_HU_A" SG_ 1285 Reserved33 0;
BA_ "GenSigTimeoutMsg_HU_B" SG_ 1285 Reserved33 0;
BA_ "GenSigTimeoutMsg_HU_A" SG_ 1285 Reserved33 0;
BA_ "GenSigSendType" SG_ 1285 Reserved33 7;
BA_ "GenSigCycleTimeActive" SG_ 1285 Reserved33 200;
BA_ "GenSigCycleTime" SG_ 1285 Reserved33 200;
BA_ "GenSigTimeoutTime_HU_B" SG_ 1285 Reserved32 0;
BA_ "GenSigTimeoutTime_HU_A" SG_ 1285 Reserved32 0;
BA_ "GenSigTimeoutMsg_HU_B" SG_ 1285 Reserved32 0;
BA_ "GenSigTimeoutMsg_HU_A" SG_ 1285 Reserved32 0;
BA_ "GenSigSendType" SG_ 1285 Reserved32 7;
BA_ "GenSigCycleTimeActive" SG_ 1285 Reserved32 200;
BA_ "GenSigCycleTime" SG_ 1285 Reserved32 200;
BA_ "GenSigTimeoutTime_HU_B" SG_ 1285 GSS_NMPDU_USER_DATA_D1 0;
BA_ "GenSigTimeoutTime_HU_A" SG_ 1285 GSS_NMPDU_USER_DATA_D1 0;
BA_ "GenSigTimeoutMsg_HU_B" SG_ 1285 GSS_NMPDU_USER_DATA_D1 0;
BA_ "GenSigTimeoutMsg_HU_A" SG_ 1285 GSS_NMPDU_USER_DATA_D1 0;
BA_ "GenSigSendType" SG_ 1285 GSS_NMPDU_USER_DATA_D1 7;
BA_ "GenSigCycleTimeActive" SG_ 1285 GSS_NMPDU_USER_DATA_D1 200;
BA_ "GenSigCycleTime" SG_ 1285 GSS_NMPDU_USER_DATA_D1 200;
BA_ "GenSigTimeoutTime_HU_B" SG_ 1285 GSS_NMPDU_USER_DATA_D2 0;
BA_ "GenSigTimeoutTime_HU_A" SG_ 1285 GSS_NMPDU_USER_DATA_D2 0;
BA_ "GenSigTimeoutMsg_HU_B" SG_ 1285 GSS_NMPDU_USER_DATA_D2 0;
BA_ "GenSigTimeoutMsg_HU_A" SG_ 1285 GSS_NMPDU_USER_DATA_D2 0;
BA_ "GenSigSendType" SG_ 1285 GSS_NMPDU_USER_DATA_D2 7;
BA_ "GenSigCycleTimeActive" SG_ 1285 GSS_NMPDU_USER_DATA_D2 200;
BA_ "GenSigCycleTime" SG_ 1285 GSS_NMPDU_USER_DATA_D2 200;
BA_ "GenSigTimeoutTime_HU_B" SG_ 1285 GSS_NMPDU_USER_DATA_D3 0;
BA_ "GenSigTimeoutTime_HU_A" SG_ 1285 GSS_NMPDU_USER_DATA_D3 0;
BA_ "GenSigTimeoutMsg_HU_B" SG_ 1285 GSS_NMPDU_USER_DATA_D3 0;
BA_ "GenSigTimeoutMsg_HU_A" SG_ 1285 GSS_NMPDU_USER_DATA_D3 0;
BA_ "GenSigSendType" SG_ 1285 GSS_NMPDU_USER_DATA_D3 7;
BA_ "GenSigCycleTimeActive" SG_ 1285 GSS_NMPDU_USER_DATA_D3 200;
BA_ "GenSigCycleTime" SG_ 1285 GSS_NMPDU_USER_DATA_D3 200;
BA_ "GenSigTimeoutTime_HU_B" SG_ 1285 GSS_NMPDU_USER_DATA_D4 0;
BA_ "GenSigTimeoutTime_HU_A" SG_ 1285 GSS_NMPDU_USER_DATA_D4 0;
BA_ "GenSigTimeoutMsg_HU_B" SG_ 1285 GSS_NMPDU_USER_DATA_D4 0;
BA_ "GenSigTimeoutMsg_HU_A" SG_ 1285 GSS_NMPDU_USER_DATA_D4 0;
BA_ "GenSigSendType" SG_ 1285 GSS_NMPDU_USER_DATA_D4 7;
BA_ "GenSigCycleTimeActive" SG_ 1285 GSS_NMPDU_USER_DATA_D4 200;
BA_ "GenSigCycleTime" SG_ 1285 GSS_NMPDU_USER_DATA_D4 200;
BA_ "GenSigTimeoutTime_HU_B" SG_ 1285 GSS_NMPDU_USER_DATA_D5 0;
BA_ "GenSigTimeoutTime_HU_A" SG_ 1285 GSS_NMPDU_USER_DATA_D5 0;
BA_ "GenSigTimeoutMsg_HU_B" SG_ 1285 GSS_NMPDU_USER_DATA_D5 0;
BA_ "GenSigTimeoutMsg_HU_A" SG_ 1285 GSS_NMPDU_USER_DATA_D5 0;
BA_ "GenSigSendType" SG_ 1285 GSS_NMPDU_USER_DATA_D5 7;
BA_ "GenSigCycleTimeActive" SG_ 1285 GSS_NMPDU_USER_DATA_D5 200;
BA_ "GenSigCycleTime" SG_ 1285 GSS_NMPDU_USER_DATA_D5 200;
BA_ "GenSigTimeoutTime_HU_B" SG_ 1286 CCM_NMPDU_SRC_ECU_ID 0;
BA_ "GenSigTimeoutTime_HU_A" SG_ 1286 CCM_NMPDU_SRC_ECU_ID 0;
BA_ "GenSigTimeoutMsg_HU_B" SG_ 1286 CCM_NMPDU_SRC_ECU_ID 0;
BA_ "GenSigTimeoutMsg_HU_A" SG_ 1286 CCM_NMPDU_SRC_ECU_ID 0;
BA_ "GenSigSendType" SG_ 1286 CCM_NMPDU_SRC_ECU_ID 7;
BA_ "GenSigCycleTimeActive" SG_ 1286 CCM_NMPDU_SRC_ECU_ID 200;
BA_ "GenSigCycleTime" SG_ 1286 CCM_NMPDU_SRC_ECU_ID 200;
BA_ "GenSigTimeoutTime_HU_B" SG_ 1286 RepeatMessageReq_CCM 0;
BA_ "GenSigTimeoutTime_HU_A" SG_ 1286 RepeatMessageReq_CCM 0;
BA_ "GenSigTimeoutMsg_HU_B" SG_ 1286 RepeatMessageReq_CCM 0;
BA_ "GenSigTimeoutMsg_HU_A" SG_ 1286 RepeatMessageReq_CCM 0;
BA_ "GenSigSendType" SG_ 1286 RepeatMessageReq_CCM 7;
BA_ "GenSigCycleTimeActive" SG_ 1286 RepeatMessageReq_CCM 200;
BA_ "GenSigCycleTime" SG_ 1286 RepeatMessageReq_CCM 200;
BA_ "GenSigTimeoutTime_HU_B" SG_ 1286 Reserved16 0;
BA_ "GenSigTimeoutTime_HU_A" SG_ 1286 Reserved16 0;
BA_ "GenSigTimeoutMsg_HU_B" SG_ 1286 Reserved16 0;
BA_ "GenSigTimeoutMsg_HU_A" SG_ 1286 Reserved16 0;
BA_ "GenSigSendType" SG_ 1286 Reserved16 7;
BA_ "GenSigCycleTimeActive" SG_ 1286 Reserved16 200;
BA_ "GenSigCycleTime" SG_ 1286 Reserved16 200;
BA_ "GenSigTimeoutTime_HU_B" SG_ 1286 Reserved17 0;
BA_ "GenSigTimeoutTime_HU_A" SG_ 1286 Reserved17 0;
BA_ "GenSigTimeoutMsg_HU_B" SG_ 1286 Reserved17 0;
BA_ "GenSigTimeoutMsg_HU_A" SG_ 1286 Reserved17 0;
BA_ "GenSigSendType" SG_ 1286 Reserved17 7;
BA_ "GenSigCycleTimeActive" SG_ 1286 Reserved17 200;
BA_ "GenSigCycleTime" SG_ 1286 Reserved17 200;
BA_ "GenSigTimeoutTime_HU_B" SG_ 1286 NMCoOrdSlpReady_CCM 0;
BA_ "GenSigTimeoutTime_HU_A" SG_ 1286 NMCoOrdSlpReady_CCM 0;
BA_ "GenSigTimeoutMsg_HU_B" SG_ 1286 NMCoOrdSlpReady_CCM 0;
BA_ "GenSigTimeoutMsg_HU_A" SG_ 1286 NMCoOrdSlpReady_CCM 0;
BA_ "GenSigSendType" SG_ 1286 NMCoOrdSlpReady_CCM 7;
BA_ "GenSigCycleTimeActive" SG_ 1286 NMCoOrdSlpReady_CCM 200;
BA_ "GenSigCycleTime" SG_ 1286 NMCoOrdSlpReady_CCM 200;
BA_ "GenSigTimeoutTime_HU_B" SG_ 1286 ActiveWakeUp_CCM 0;
BA_ "GenSigTimeoutTime_HU_A" SG_ 1286 ActiveWakeUp_CCM 0;
BA_ "GenSigTimeoutMsg_HU_B" SG_ 1286 ActiveWakeUp_CCM 0;
BA_ "GenSigTimeoutMsg_HU_A" SG_ 1286 ActiveWakeUp_CCM 0;
BA_ "GenSigSendType" SG_ 1286 ActiveWakeUp_CCM 7;
BA_ "GenSigCycleTimeActive" SG_ 1286 ActiveWakeUp_CCM 200;
BA_ "GenSigCycleTime" SG_ 1286 ActiveWakeUp_CCM 200;
BA_ "GenSigTimeoutTime_HU_B" SG_ 1286 Reserved18 0;
BA_ "GenSigTimeoutTime_HU_A" SG_ 1286 Reserved18 0;
BA_ "GenSigTimeoutMsg_HU_B" SG_ 1286 Reserved18 0;
BA_ "GenSigTimeoutMsg_HU_A" SG_ 1286 Reserved18 0;
BA_ "GenSigSendType" SG_ 1286 Reserved18 7;
BA_ "GenSigCycleTimeActive" SG_ 1286 Reserved18 200;
BA_ "GenSigCycleTime" SG_ 1286 Reserved18 200;
BA_ "GenSigTimeoutTime_HU_B" SG_ 1286 PartialNetworkInformation_CCM 0;
BA_ "GenSigTimeoutTime_HU_A" SG_ 1286 PartialNetworkInformation_CCM 0;
BA_ "GenSigTimeoutMsg_HU_B" SG_ 1286 PartialNetworkInformation_CCM 0;
BA_ "GenSigTimeoutMsg_HU_A" SG_ 1286 PartialNetworkInformation_CCM 0;
BA_ "GenSigSendType" SG_ 1286 PartialNetworkInformation_CCM 7;
BA_ "GenSigCycleTimeActive" SG_ 1286 PartialNetworkInformation_CCM 200;
BA_ "GenSigCycleTime" SG_ 1286 PartialNetworkInformation_CCM 200;
BA_ "GenSigTimeoutTime_HU_B" SG_ 1286 Reserved19 0;
BA_ "GenSigTimeoutTime_HU_A" SG_ 1286 Reserved19 0;
BA_ "GenSigTimeoutMsg_HU_B" SG_ 1286 Reserved19 0;
BA_ "GenSigTimeoutMsg_HU_A" SG_ 1286 Reserved19 0;
BA_ "GenSigSendType" SG_ 1286 Reserved19 7;
BA_ "GenSigCycleTimeActive" SG_ 1286 Reserved19 200;
BA_ "GenSigCycleTime" SG_ 1286 Reserved19 200;
BA_ "GenSigTimeoutTime_HU_B" SG_ 1286 CurrentState_CCM 0;
BA_ "GenSigTimeoutTime_HU_A" SG_ 1286 CurrentState_CCM 0;
BA_ "GenSigTimeoutMsg_HU_B" SG_ 1286 CurrentState_CCM 0;
BA_ "GenSigTimeoutMsg_HU_A" SG_ 1286 CurrentState_CCM 0;
BA_ "GenSigSendType" SG_ 1286 CurrentState_CCM 7;
BA_ "GenSigCycleTimeActive" SG_ 1286 CurrentState_CCM 200;
BA_ "GenSigCycleTime" SG_ 1286 CurrentState_CCM 200;
BA_ "GenSigTimeoutTime_HU_B" SG_ 1286 PreviousState_CCM 0;
BA_ "GenSigTimeoutTime_HU_A" SG_ 1286 PreviousState_CCM 0;
BA_ "GenSigTimeoutMsg_HU_B" SG_ 1286 PreviousState_CCM 0;
BA_ "GenSigTimeoutMsg_HU_A" SG_ 1286 PreviousState_CCM 0;
BA_ "GenSigSendType" SG_ 1286 PreviousState_CCM 7;
BA_ "GenSigCycleTimeActive" SG_ 1286 PreviousState_CCM 200;
BA_ "GenSigCycleTime" SG_ 1286 PreviousState_CCM 200;
BA_ "GenSigTimeoutTime_HU_B" SG_ 1286 Reserved20 0;
BA_ "GenSigTimeoutTime_HU_A" SG_ 1286 Reserved20 0;
BA_ "GenSigTimeoutMsg_HU_B" SG_ 1286 Reserved20 0;
BA_ "GenSigTimeoutMsg_HU_A" SG_ 1286 Reserved20 0;
BA_ "GenSigSendType" SG_ 1286 Reserved20 7;
BA_ "GenSigCycleTimeActive" SG_ 1286 Reserved20 200;
BA_ "GenSigCycleTime" SG_ 1286 Reserved20 200;
BA_ "GenSigTimeoutTime_HU_B" SG_ 1286 Reserved21 0;
BA_ "GenSigTimeoutTime_HU_A" SG_ 1286 Reserved21 0;
BA_ "GenSigTimeoutMsg_HU_B" SG_ 1286 Reserved21 0;
BA_ "GenSigTimeoutMsg_HU_A" SG_ 1286 Reserved21 0;
BA_ "GenSigSendType" SG_ 1286 Reserved21 7;
BA_ "GenSigCycleTimeActive" SG_ 1286 Reserved21 200;
BA_ "GenSigCycleTime" SG_ 1286 Reserved21 200;
BA_ "GenSigTimeoutTime_HU_B" SG_ 1286 Reserved22 0;
BA_ "GenSigTimeoutTime_HU_A" SG_ 1286 Reserved22 0;
BA_ "GenSigTimeoutMsg_HU_B" SG_ 1286 Reserved22 0;
BA_ "GenSigTimeoutMsg_HU_A" SG_ 1286 Reserved22 0;
BA_ "GenSigSendType" SG_ 1286 Reserved22 7;
BA_ "GenSigCycleTimeActive" SG_ 1286 Reserved22 200;
BA_ "GenSigCycleTime" SG_ 1286 Reserved22 200;
BA_ "GenSigTimeoutTime_HU_B" SG_ 1286 Reserved23 0;
BA_ "GenSigTimeoutTime_HU_A" SG_ 1286 Reserved23 0;
BA_ "GenSigTimeoutMsg_HU_B" SG_ 1286 Reserved23 0;
BA_ "GenSigTimeoutMsg_HU_A" SG_ 1286 Reserved23 0;
BA_ "GenSigSendType" SG_ 1286 Reserved23 7;
BA_ "GenSigCycleTimeActive" SG_ 1286 Reserved23 200;
BA_ "GenSigCycleTime" SG_ 1286 Reserved23 200;
BA_ "GenSigTimeoutTime_HU_B" SG_ 1286 CCM_NMPDU_USER_DATA_1 0;
BA_ "GenSigTimeoutTime_HU_A" SG_ 1286 CCM_NMPDU_USER_DATA_1 0;
BA_ "GenSigTimeoutMsg_HU_B" SG_ 1286 CCM_NMPDU_USER_DATA_1 0;
BA_ "GenSigTimeoutMsg_HU_A" SG_ 1286 CCM_NMPDU_USER_DATA_1 0;
BA_ "GenSigSendType" SG_ 1286 CCM_NMPDU_USER_DATA_1 7;
BA_ "GenSigCycleTimeActive" SG_ 1286 CCM_NMPDU_USER_DATA_1 200;
BA_ "GenSigCycleTime" SG_ 1286 CCM_NMPDU_USER_DATA_1 200;
BA_ "GenSigTimeoutTime_HU_B" SG_ 1286 CCM_NMPDU_USER_DATA_2 0;
BA_ "GenSigTimeoutTime_HU_A" SG_ 1286 CCM_NMPDU_USER_DATA_2 0;
BA_ "GenSigTimeoutMsg_HU_B" SG_ 1286 CCM_NMPDU_USER_DATA_2 0;
BA_ "GenSigTimeoutMsg_HU_A" SG_ 1286 CCM_NMPDU_USER_DATA_2 0;
BA_ "GenSigSendType" SG_ 1286 CCM_NMPDU_USER_DATA_2 7;
BA_ "GenSigCycleTimeActive" SG_ 1286 CCM_NMPDU_USER_DATA_2 200;
BA_ "GenSigCycleTime" SG_ 1286 CCM_NMPDU_USER_DATA_2 200;
BA_ "GenSigTimeoutTime_HU_B" SG_ 1286 CCM_NMPDU_USER_DATA_3 0;
BA_ "GenSigTimeoutTime_HU_A" SG_ 1286 CCM_NMPDU_USER_DATA_3 0;
BA_ "GenSigTimeoutMsg_HU_B" SG_ 1286 CCM_NMPDU_USER_DATA_3 0;
BA_ "GenSigTimeoutMsg_HU_A" SG_ 1286 CCM_NMPDU_USER_DATA_3 0;
BA_ "GenSigSendType" SG_ 1286 CCM_NMPDU_USER_DATA_3 7;
BA_ "GenSigCycleTimeActive" SG_ 1286 CCM_NMPDU_USER_DATA_3 200;
BA_ "GenSigCycleTime" SG_ 1286 CCM_NMPDU_USER_DATA_3 200;
BA_ "GenSigTimeoutTime_HU_B" SG_ 1286 CCM_NMPDU_USER_DATA_4 0;
BA_ "GenSigTimeoutTime_HU_A" SG_ 1286 CCM_NMPDU_USER_DATA_4 0;
BA_ "GenSigTimeoutMsg_HU_B" SG_ 1286 CCM_NMPDU_USER_DATA_4 0;
BA_ "GenSigTimeoutMsg_HU_A" SG_ 1286 CCM_NMPDU_USER_DATA_4 0;
BA_ "GenSigSendType" SG_ 1286 CCM_NMPDU_USER_DATA_4 7;
BA_ "GenSigCycleTimeActive" SG_ 1286 CCM_NMPDU_USER_DATA_4 200;
BA_ "GenSigCycleTime" SG_ 1286 CCM_NMPDU_USER_DATA_4 200;
BA_ "GenSigTimeoutTime_HU_B" SG_ 1286 CCM_NMPDU_USER_DATA_5 0;
BA_ "GenSigTimeoutTime_HU_A" SG_ 1286 CCM_NMPDU_USER_DATA_5 0;
BA_ "GenSigTimeoutMsg_HU_B" SG_ 1286 CCM_NMPDU_USER_DATA_5 0;
BA_ "GenSigTimeoutMsg_HU_A" SG_ 1286 CCM_NMPDU_USER_DATA_5 0;
BA_ "GenSigSendType" SG_ 1286 CCM_NMPDU_USER_DATA_5 7;
BA_ "GenSigCycleTimeActive" SG_ 1286 CCM_NMPDU_USER_DATA_5 200;
BA_ "GenSigCycleTime" SG_ 1286 CCM_NMPDU_USER_DATA_5 200;
BA_ "GenSigTimeoutTime_HU_Mid_X451" SG_ 1312 MANDO_Steering_Analyzer_Rx0 0;
BA_ "GenSigTimeoutTime_HU_High_X451" SG_ 1312 MANDO_Steering_Analyzer_Rx0 0;
BA_ "GenSigTimeoutTime_HU_B" SG_ 1312 MANDO_Steering_Analyzer_Rx0 0;
BA_ "GenSigTimeoutTime_HU_A" SG_ 1312 MANDO_Steering_Analyzer_Rx0 0;
BA_ "GenSigTimeoutMsg_HU_Mid_X451" SG_ 1312 MANDO_Steering_Analyzer_Rx0 0;
BA_ "GenSigTimeoutMsg_HU_High_X451" SG_ 1312 MANDO_Steering_Analyzer_Rx0 0;
BA_ "GenSigTimeoutMsg_HU_B" SG_ 1312 MANDO_Steering_Analyzer_Rx0 0;
BA_ "GenSigTimeoutMsg_HU_A" SG_ 1312 MANDO_Steering_Analyzer_Rx0 0;
BA_ "GenSigSendType" SG_ 1312 MANDO_Steering_Analyzer_Rx0 1;
BA_ "GenSigTimeoutTime_HU_Mid_X451" SG_ 1313 MANDO_Steering_Analyzer_Tx0 0;
BA_ "GenSigTimeoutTime_HU_High_X451" SG_ 1313 MANDO_Steering_Analyzer_Tx0 0;
BA_ "GenSigTimeoutTime_HU_B" SG_ 1313 MANDO_Steering_Analyzer_Tx0 0;
BA_ "GenSigTimeoutTime_HU_A" SG_ 1313 MANDO_Steering_Analyzer_Tx0 0;
BA_ "GenSigTimeoutMsg_HU_Mid_X451" SG_ 1313 MANDO_Steering_Analyzer_Tx0 0;
BA_ "GenSigTimeoutMsg_HU_High_X451" SG_ 1313 MANDO_Steering_Analyzer_Tx0 0;
BA_ "GenSigTimeoutMsg_HU_B" SG_ 1313 MANDO_Steering_Analyzer_Tx0 0;
BA_ "GenSigTimeoutMsg_HU_A" SG_ 1313 MANDO_Steering_Analyzer_Tx0 0;
BA_ "GenSigSendType" SG_ 1313 MANDO_Steering_Analyzer_Tx0 1;
BA_ "GenSigTimeoutTime_HU_Mid_X451" SG_ 1314 MANDO_Steering_Analyzer_Rx1 0;
BA_ "GenSigTimeoutTime_HU_High_X451" SG_ 1314 MANDO_Steering_Analyzer_Rx1 0;
BA_ "GenSigTimeoutTime_HU_B" SG_ 1314 MANDO_Steering_Analyzer_Rx1 0;
BA_ "GenSigTimeoutTime_HU_A" SG_ 1314 MANDO_Steering_Analyzer_Rx1 0;
BA_ "GenSigTimeoutMsg_HU_Mid_X451" SG_ 1314 MANDO_Steering_Analyzer_Rx1 0;
BA_ "GenSigTimeoutMsg_HU_High_X451" SG_ 1314 MANDO_Steering_Analyzer_Rx1 0;
BA_ "GenSigTimeoutMsg_HU_B" SG_ 1314 MANDO_Steering_Analyzer_Rx1 0;
BA_ "GenSigTimeoutMsg_HU_A" SG_ 1314 MANDO_Steering_Analyzer_Rx1 0;
BA_ "GenSigSendType" SG_ 1314 MANDO_Steering_Analyzer_Rx1 1;
BA_ "GenSigTimeoutTime_HU_Mid_X451" SG_ 1315 MANDO_Steering_Analyzer_Tx1 0;
BA_ "GenSigTimeoutTime_HU_High_X451" SG_ 1315 MANDO_Steering_Analyzer_Tx1 0;
BA_ "GenSigTimeoutTime_HU_B" SG_ 1315 MANDO_Steering_Analyzer_Tx1 0;
BA_ "GenSigTimeoutTime_HU_A" SG_ 1315 MANDO_Steering_Analyzer_Tx1 0;
BA_ "GenSigTimeoutMsg_HU_Mid_X451" SG_ 1315 MANDO_Steering_Analyzer_Tx1 0;
BA_ "GenSigTimeoutMsg_HU_High_X451" SG_ 1315 MANDO_Steering_Analyzer_Tx1 0;
BA_ "GenSigTimeoutMsg_HU_B" SG_ 1315 MANDO_Steering_Analyzer_Tx1 0;
BA_ "GenSigTimeoutMsg_HU_A" SG_ 1315 MANDO_Steering_Analyzer_Tx1 0;
BA_ "GenSigSendType" SG_ 1315 MANDO_Steering_Analyzer_Tx1 1;
BA_ "GenSigTimeoutTime_HU_Mid_X451" SG_ 1316 MANDO_Steering_Analyzer_Rx2 0;
BA_ "GenSigTimeoutTime_HU_High_X451" SG_ 1316 MANDO_Steering_Analyzer_Rx2 0;
BA_ "GenSigTimeoutTime_HU_B" SG_ 1316 MANDO_Steering_Analyzer_Rx2 0;
BA_ "GenSigTimeoutTime_HU_A" SG_ 1316 MANDO_Steering_Analyzer_Rx2 0;
BA_ "GenSigTimeoutMsg_HU_Mid_X451" SG_ 1316 MANDO_Steering_Analyzer_Rx2 0;
BA_ "GenSigTimeoutMsg_HU_High_X451" SG_ 1316 MANDO_Steering_Analyzer_Rx2 0;
BA_ "GenSigTimeoutMsg_HU_B" SG_ 1316 MANDO_Steering_Analyzer_Rx2 0;
BA_ "GenSigTimeoutMsg_HU_A" SG_ 1316 MANDO_Steering_Analyzer_Rx2 0;
BA_ "GenSigSendType" SG_ 1316 MANDO_Steering_Analyzer_Rx2 1;
BA_ "GenSigTimeoutTime_HU_Mid_X451" SG_ 1317 MANDO_Steering_Analyzer_Tx2 0;
BA_ "GenSigTimeoutTime_HU_High_X451" SG_ 1317 MANDO_Steering_Analyzer_Tx2 0;
BA_ "GenSigTimeoutTime_HU_B" SG_ 1317 MANDO_Steering_Analyzer_Tx2 0;
BA_ "GenSigTimeoutTime_HU_A" SG_ 1317 MANDO_Steering_Analyzer_Tx2 0;
BA_ "GenSigTimeoutMsg_HU_Mid_X451" SG_ 1317 MANDO_Steering_Analyzer_Tx2 0;
BA_ "GenSigTimeoutMsg_HU_High_X451" SG_ 1317 MANDO_Steering_Analyzer_Tx2 0;
BA_ "GenSigTimeoutMsg_HU_B" SG_ 1317 MANDO_Steering_Analyzer_Tx2 0;
BA_ "GenSigTimeoutMsg_HU_A" SG_ 1317 MANDO_Steering_Analyzer_Tx2 0;
BA_ "GenSigSendType" SG_ 1317 MANDO_Steering_Analyzer_Tx2 1;
BA_ "GenSigTimeoutTime_HU_Mid_X451" SG_ 1318 MANDO_Steering_Analyzer_Rx3 0;
BA_ "GenSigTimeoutTime_HU_High_X451" SG_ 1318 MANDO_Steering_Analyzer_Rx3 0;
BA_ "GenSigTimeoutTime_HU_B" SG_ 1318 MANDO_Steering_Analyzer_Rx3 0;
BA_ "GenSigTimeoutTime_HU_A" SG_ 1318 MANDO_Steering_Analyzer_Rx3 0;
BA_ "GenSigTimeoutMsg_HU_Mid_X451" SG_ 1318 MANDO_Steering_Analyzer_Rx3 0;
BA_ "GenSigTimeoutMsg_HU_High_X451" SG_ 1318 MANDO_Steering_Analyzer_Rx3 0;
BA_ "GenSigTimeoutMsg_HU_B" SG_ 1318 MANDO_Steering_Analyzer_Rx3 0;
BA_ "GenSigTimeoutMsg_HU_A" SG_ 1318 MANDO_Steering_Analyzer_Rx3 0;
BA_ "GenSigSendType" SG_ 1318 MANDO_Steering_Analyzer_Rx3 1;
BA_ "GenSigTimeoutTime_HU_Mid_X451" SG_ 1319 MANDO_Steering_Analyzer_Tx3 0;
BA_ "GenSigTimeoutTime_HU_High_X451" SG_ 1319 MANDO_Steering_Analyzer_Tx3 0;
BA_ "GenSigTimeoutTime_HU_B" SG_ 1319 MANDO_Steering_Analyzer_Tx3 0;
BA_ "GenSigTimeoutTime_HU_A" SG_ 1319 MANDO_Steering_Analyzer_Tx3 0;
BA_ "GenSigTimeoutMsg_HU_Mid_X451" SG_ 1319 MANDO_Steering_Analyzer_Tx3 0;
BA_ "GenSigTimeoutMsg_HU_High_X451" SG_ 1319 MANDO_Steering_Analyzer_Tx3 0;
BA_ "GenSigTimeoutMsg_HU_B" SG_ 1319 MANDO_Steering_Analyzer_Tx3 0;
BA_ "GenSigTimeoutMsg_HU_A" SG_ 1319 MANDO_Steering_Analyzer_Tx3 0;
BA_ "GenSigSendType" SG_ 1319 MANDO_Steering_Analyzer_Tx3 1;
BA_ "GenSigTimeoutTime_HU_Mid_X451" SG_ 1320 MANDO_Steering_Analyzer_Rx4 0;
BA_ "GenSigTimeoutTime_HU_High_X451" SG_ 1320 MANDO_Steering_Analyzer_Rx4 0;
BA_ "GenSigTimeoutTime_HU_B" SG_ 1320 MANDO_Steering_Analyzer_Rx4 0;
BA_ "GenSigTimeoutTime_HU_A" SG_ 1320 MANDO_Steering_Analyzer_Rx4 0;
BA_ "GenSigTimeoutMsg_HU_Mid_X451" SG_ 1320 MANDO_Steering_Analyzer_Rx4 0;
BA_ "GenSigTimeoutMsg_HU_High_X451" SG_ 1320 MANDO_Steering_Analyzer_Rx4 0;
BA_ "GenSigTimeoutMsg_HU_B" SG_ 1320 MANDO_Steering_Analyzer_Rx4 0;
BA_ "GenSigTimeoutMsg_HU_A" SG_ 1320 MANDO_Steering_Analyzer_Rx4 0;
BA_ "GenSigSendType" SG_ 1320 MANDO_Steering_Analyzer_Rx4 1;
BA_ "GenSigTimeoutTime_HU_Mid_X451" SG_ 1321 MANDO_Steering_Analyzer_Tx4 0;
BA_ "GenSigTimeoutTime_HU_High_X451" SG_ 1321 MANDO_Steering_Analyzer_Tx4 0;
BA_ "GenSigTimeoutTime_HU_B" SG_ 1321 MANDO_Steering_Analyzer_Tx4 0;
BA_ "GenSigTimeoutTime_HU_A" SG_ 1321 MANDO_Steering_Analyzer_Tx4 0;
BA_ "GenSigTimeoutMsg_HU_Mid_X451" SG_ 1321 MANDO_Steering_Analyzer_Tx4 0;
BA_ "GenSigTimeoutMsg_HU_High_X451" SG_ 1321 MANDO_Steering_Analyzer_Tx4 0;
BA_ "GenSigTimeoutMsg_HU_B" SG_ 1321 MANDO_Steering_Analyzer_Tx4 0;
BA_ "GenSigTimeoutMsg_HU_A" SG_ 1321 MANDO_Steering_Analyzer_Tx4 0;
BA_ "GenSigSendType" SG_ 1321 MANDO_Steering_Analyzer_Tx4 1;
BA_ "GenSigTimeoutTime_HU_Mid_X451" SG_ 1322 MANDO_TUNING_RX 0;
BA_ "GenSigTimeoutTime_HU_High_X451" SG_ 1322 MANDO_TUNING_RX 0;
BA_ "GenSigTimeoutTime_HU_B" SG_ 1322 MANDO_TUNING_RX 0;
BA_ "GenSigTimeoutTime_HU_A" SG_ 1322 MANDO_TUNING_RX 0;
BA_ "GenSigTimeoutMsg_HU_Mid_X451" SG_ 1322 MANDO_TUNING_RX 0;
BA_ "GenSigTimeoutMsg_HU_High_X451" SG_ 1322 MANDO_TUNING_RX 0;
BA_ "GenSigTimeoutMsg_HU_B" SG_ 1322 MANDO_TUNING_RX 0;
BA_ "GenSigTimeoutMsg_HU_A" SG_ 1322 MANDO_TUNING_RX 0;
BA_ "GenSigSendType" SG_ 1322 MANDO_TUNING_RX 1;
BA_ "GenSigTimeoutTime_HU_Mid_X451" SG_ 1323 MANDO_TUNING_TX 0;
BA_ "GenSigTimeoutTime_HU_High_X451" SG_ 1323 MANDO_TUNING_TX 0;
BA_ "GenSigTimeoutTime_HU_B" SG_ 1323 MANDO_TUNING_TX 0;
BA_ "GenSigTimeoutTime_HU_A" SG_ 1323 MANDO_TUNING_TX 0;
BA_ "GenSigTimeoutMsg_HU_Mid_X451" SG_ 1323 MANDO_TUNING_TX 0;
BA_ "GenSigTimeoutMsg_HU_High_X451" SG_ 1323 MANDO_TUNING_TX 0;
BA_ "GenSigTimeoutMsg_HU_B" SG_ 1323 MANDO_TUNING_TX 0;
BA_ "GenSigTimeoutMsg_HU_A" SG_ 1323 MANDO_TUNING_TX 0;
BA_ "GenSigSendType" SG_ 1323 MANDO_TUNING_TX 1;
BA_ "GenSigTimeoutTime_HU_B" SG_ 1360 CCM_XCP_Tx 0;
BA_ "GenSigTimeoutTime_HU_A" SG_ 1360 CCM_XCP_Tx 0;
BA_ "GenSigTimeoutMsg_HU_B" SG_ 1360 CCM_XCP_Tx 0;
BA_ "GenSigTimeoutMsg_HU_A" SG_ 1360 CCM_XCP_Tx 0;
BA_ "GenSigSendType" SG_ 1360 CCM_XCP_Tx 1;
BA_ "GenSigTimeoutTime_HU_B" SG_ 1361 CCM_XCP_Rx 0;
BA_ "GenSigTimeoutTime_HU_A" SG_ 1361 CCM_XCP_Rx 0;
BA_ "GenSigTimeoutMsg_HU_B" SG_ 1361 CCM_XCP_Rx 0;
BA_ "GenSigTimeoutMsg_HU_A" SG_ 1361 CCM_XCP_Rx 0;
BA_ "GenSigSendType" SG_ 1361 CCM_XCP_Rx 1;
BA_ "GenSigTimeoutTime_HU_Mid_X451" SG_ 1362 EPAS_XCP_RX 0;
BA_ "GenSigTimeoutTime_HU_High_X451" SG_ 1362 EPAS_XCP_RX 0;
BA_ "GenSigTimeoutTime_HU_B" SG_ 1362 EPAS_XCP_RX 0;
BA_ "GenSigTimeoutTime_HU_A" SG_ 1362 EPAS_XCP_RX 0;
BA_ "GenSigTimeoutMsg_HU_Mid_X451" SG_ 1362 EPAS_XCP_RX 0;
BA_ "GenSigTimeoutMsg_HU_High_X451" SG_ 1362 EPAS_XCP_RX 0;
BA_ "GenSigTimeoutMsg_HU_B" SG_ 1362 EPAS_XCP_RX 0;
BA_ "GenSigTimeoutMsg_HU_A" SG_ 1362 EPAS_XCP_RX 0;
BA_ "GenSigSendType" SG_ 1362 EPAS_XCP_RX 1;
BA_ "GenSigTimeoutTime_HU_Mid_X451" SG_ 1363 EPAS_XCP_TX 0;
BA_ "GenSigTimeoutTime_HU_High_X451" SG_ 1363 EPAS_XCP_TX 0;
BA_ "GenSigTimeoutTime_HU_B" SG_ 1363 EPAS_XCP_TX 0;
BA_ "GenSigTimeoutTime_HU_A" SG_ 1363 EPAS_XCP_TX 0;
BA_ "GenSigTimeoutMsg_HU_Mid_X451" SG_ 1363 EPAS_XCP_TX 0;
BA_ "GenSigTimeoutMsg_HU_High_X451" SG_ 1363 EPAS_XCP_TX 0;
BA_ "GenSigTimeoutMsg_HU_B" SG_ 1363 EPAS_XCP_TX 0;
BA_ "GenSigTimeoutMsg_HU_A" SG_ 1363 EPAS_XCP_TX 0;
BA_ "GenSigSendType" SG_ 1363 EPAS_XCP_TX 1;
BA_ "GenSigTimeoutTime_HU_B" SG_ 1408 TirePressureLowerLimitFL 0;
BA_ "GenSigTimeoutTime_HU_A" SG_ 1408 TirePressureLowerLimitFL 0;
BA_ "GenSigTimeoutMsg_HU_B" SG_ 1408 TirePressureLowerLimitFL 0;
BA_ "GenSigTimeoutMsg_HU_A" SG_ 1408 TirePressureLowerLimitFL 0;
BA_ "GenSigSendType" SG_ 1408 TirePressureLowerLimitFL 7;
BA_ "GenSigCycleTimeActive" SG_ 1408 TirePressureLowerLimitFL 100;
BA_ "GenSigCycleTime" SG_ 1408 TirePressureLowerLimitFL 100;
BA_ "GenSigTimeoutTime_HU_B" SG_ 1408 TirePressureLowerLimitFR 0;
BA_ "GenSigTimeoutTime_HU_A" SG_ 1408 TirePressureLowerLimitFR 0;
BA_ "GenSigTimeoutMsg_HU_B" SG_ 1408 TirePressureLowerLimitFR 0;
BA_ "GenSigTimeoutMsg_HU_A" SG_ 1408 TirePressureLowerLimitFR 0;
BA_ "GenSigSendType" SG_ 1408 TirePressureLowerLimitFR 7;
BA_ "GenSigCycleTimeActive" SG_ 1408 TirePressureLowerLimitFR 100;
BA_ "GenSigCycleTime" SG_ 1408 TirePressureLowerLimitFR 100;
BA_ "GenSigTimeoutTime_HU_B" SG_ 1408 TirePressureLowerLimitRR 0;
BA_ "GenSigTimeoutTime_HU_A" SG_ 1408 TirePressureLowerLimitRR 0;
BA_ "GenSigTimeoutMsg_HU_B" SG_ 1408 TirePressureLowerLimitRR 0;
BA_ "GenSigTimeoutMsg_HU_A" SG_ 1408 TirePressureLowerLimitRR 0;
BA_ "GenSigSendType" SG_ 1408 TirePressureLowerLimitRR 7;
BA_ "GenSigCycleTimeActive" SG_ 1408 TirePressureLowerLimitRR 100;
BA_ "GenSigCycleTime" SG_ 1408 TirePressureLowerLimitRR 100;
BA_ "GenSigTimeoutTime_HU_B" SG_ 1408 TirePressureLowerLimitRL 0;
BA_ "GenSigTimeoutTime_HU_A" SG_ 1408 TirePressureLowerLimitRL 0;
BA_ "GenSigTimeoutMsg_HU_B" SG_ 1408 TirePressureLowerLimitRL 0;
BA_ "GenSigTimeoutMsg_HU_A" SG_ 1408 TirePressureLowerLimitRL 0;
BA_ "GenSigSendType" SG_ 1408 TirePressureLowerLimitRL 7;
BA_ "GenSigCycleTimeActive" SG_ 1408 TirePressureLowerLimitRL 100;
BA_ "GenSigCycleTime" SG_ 1408 TirePressureLowerLimitRL 100;
BA_ "GenSigTimeoutTime_HU_B" SG_ 1409 TirePressureLowerLimitSpare 0;
BA_ "GenSigTimeoutTime_HU_A" SG_ 1409 TirePressureLowerLimitSpare 0;
BA_ "GenSigTimeoutMsg_HU_B" SG_ 1409 TirePressureLowerLimitSpare 0;
BA_ "GenSigTimeoutMsg_HU_A" SG_ 1409 TirePressureLowerLimitSpare 0;
BA_ "GenSigSendType" SG_ 1409 TirePressureLowerLimitSpare 7;
BA_ "GenSigCycleTimeActive" SG_ 1409 TirePressureLowerLimitSpare 100;
BA_ "GenSigCycleTime" SG_ 1409 TirePressureLowerLimitSpare 100;
BA_ "GenSigTimeoutTime_HU_B" SG_ 1410 TireHitRateFL 0;
BA_ "GenSigTimeoutTime_HU_A" SG_ 1410 TireHitRateFL 0;
BA_ "GenSigTimeoutMsg_HU_B" SG_ 1410 TireHitRateFL 0;
BA_ "GenSigTimeoutMsg_HU_A" SG_ 1410 TireHitRateFL 0;
BA_ "GenSigSendType" SG_ 1410 TireHitRateFL 7;
BA_ "GenSigCycleTimeActive" SG_ 1410 TireHitRateFL 100;
BA_ "GenSigCycleTime" SG_ 1410 TireHitRateFL 100;
BA_ "GenSigTimeoutTime_HU_B" SG_ 1410 TireHitRateFR 0;
BA_ "GenSigTimeoutTime_HU_A" SG_ 1410 TireHitRateFR 0;
BA_ "GenSigTimeoutMsg_HU_B" SG_ 1410 TireHitRateFR 0;
BA_ "GenSigTimeoutMsg_HU_A" SG_ 1410 TireHitRateFR 0;
BA_ "GenSigSendType" SG_ 1410 TireHitRateFR 7;
BA_ "GenSigCycleTimeActive" SG_ 1410 TireHitRateFR 100;
BA_ "GenSigCycleTime" SG_ 1410 TireHitRateFR 100;
BA_ "GenSigTimeoutTime_HU_B" SG_ 1410 TireHitRateRR 0;
BA_ "GenSigTimeoutTime_HU_A" SG_ 1410 TireHitRateRR 0;
BA_ "GenSigTimeoutMsg_HU_B" SG_ 1410 TireHitRateRR 0;
BA_ "GenSigTimeoutMsg_HU_A" SG_ 1410 TireHitRateRR 0;
BA_ "GenSigSendType" SG_ 1410 TireHitRateRR 7;
BA_ "GenSigCycleTimeActive" SG_ 1410 TireHitRateRR 100;
BA_ "GenSigCycleTime" SG_ 1410 TireHitRateRR 100;
BA_ "GenSigTimeoutTime_HU_B" SG_ 1410 TireHitRateRL 0;
BA_ "GenSigTimeoutTime_HU_A" SG_ 1410 TireHitRateRL 0;
BA_ "GenSigTimeoutMsg_HU_B" SG_ 1410 TireHitRateRL 0;
BA_ "GenSigTimeoutMsg_HU_A" SG_ 1410 TireHitRateRL 0;
BA_ "GenSigSendType" SG_ 1410 TireHitRateRL 7;
BA_ "GenSigCycleTimeActive" SG_ 1410 TireHitRateRL 100;
BA_ "GenSigCycleTime" SG_ 1410 TireHitRateRL 100;
BA_ "GenSigTimeoutTime_HU_B" SG_ 1411 TireHitRateSpare 0;
BA_ "GenSigTimeoutTime_HU_A" SG_ 1411 TireHitRateSpare 0;
BA_ "GenSigTimeoutMsg_HU_B" SG_ 1411 TireHitRateSpare 0;
BA_ "GenSigTimeoutMsg_HU_A" SG_ 1411 TireHitRateSpare 0;
BA_ "GenSigSendType" SG_ 1411 TireHitRateSpare 7;
BA_ "GenSigCycleTimeActive" SG_ 1411 TireHitRateSpare 100;
BA_ "GenSigCycleTime" SG_ 1411 TireHitRateSpare 100;
BA_ "GenSigTimeoutTime_HU_B" SG_ 1412 Tyre_RSSI_RR 0;
BA_ "GenSigTimeoutTime_HU_A" SG_ 1412 Tyre_RSSI_RR 0;
BA_ "GenSigTimeoutMsg_HU_B" SG_ 1412 Tyre_RSSI_RR 0;
BA_ "GenSigTimeoutMsg_HU_A" SG_ 1412 Tyre_RSSI_RR 0;
BA_ "GenSigSendType" SG_ 1412 Tyre_RSSI_RR 7;
BA_ "GenSigCycleTimeActive" SG_ 1412 Tyre_RSSI_RR 100;
BA_ "GenSigCycleTime" SG_ 1412 Tyre_RSSI_RR 100;
BA_ "GenSigTimeoutTime_HU_B" SG_ 1536 DebugOutput1 0;
BA_ "GenSigTimeoutTime_HU_A" SG_ 1536 DebugOutput1 0;
BA_ "GenSigTimeoutMsg_HU_B" SG_ 1536 DebugOutput1 0;
BA_ "GenSigTimeoutMsg_HU_A" SG_ 1536 DebugOutput1 0;
BA_ "GenSigSendType" SG_ 1536 DebugOutput1 1;
BA_ "GenSigTimeoutTime_HU_B" SG_ 1537 DebugOutput2 0;
BA_ "GenSigTimeoutTime_HU_A" SG_ 1537 DebugOutput2 0;
BA_ "GenSigTimeoutMsg_HU_B" SG_ 1537 DebugOutput2 0;
BA_ "GenSigTimeoutMsg_HU_A" SG_ 1537 DebugOutput2 0;
BA_ "GenSigSendType" SG_ 1537 DebugOutput2 1;
BA_ "GenSigTimeoutTime_HU_B" SG_ 1538 DebugOutput3 0;
BA_ "GenSigTimeoutTime_HU_A" SG_ 1538 DebugOutput3 0;
BA_ "GenSigTimeoutMsg_HU_B" SG_ 1538 DebugOutput3 0;
BA_ "GenSigTimeoutMsg_HU_A" SG_ 1538 DebugOutput3 0;
BA_ "GenSigSendType" SG_ 1538 DebugOutput3 1;
BA_ "GenSigTimeoutTime_HU_B" SG_ 1539 DebugOutput4 0;
BA_ "GenSigTimeoutTime_HU_A" SG_ 1539 DebugOutput4 0;
BA_ "GenSigTimeoutMsg_HU_B" SG_ 1539 DebugOutput4 0;
BA_ "GenSigTimeoutMsg_HU_A" SG_ 1539 DebugOutput4 0;
BA_ "GenSigSendType" SG_ 1539 DebugOutput4 1;
BA_ "GenSigTimeoutTime_HU_B" SG_ 1540 DebugOutput5 0;
BA_ "GenSigTimeoutTime_HU_A" SG_ 1540 DebugOutput5 0;
BA_ "GenSigTimeoutMsg_HU_B" SG_ 1540 DebugOutput5 0;
BA_ "GenSigTimeoutMsg_HU_A" SG_ 1540 DebugOutput5 0;
BA_ "GenSigSendType" SG_ 1540 DebugOutput5 1;
BA_ "GenSigTimeoutTime_HU_B" SG_ 1541 DebugOutput6 0;
BA_ "GenSigTimeoutTime_HU_A" SG_ 1541 DebugOutput6 0;
BA_ "GenSigTimeoutMsg_HU_B" SG_ 1541 DebugOutput6 0;
BA_ "GenSigTimeoutMsg_HU_A" SG_ 1541 DebugOutput6 0;
BA_ "GenSigSendType" SG_ 1541 DebugOutput6 1;
BA_ "GenSigTimeoutTime_HU_B" SG_ 1542 DebugOutput7 0;
BA_ "GenSigTimeoutTime_HU_A" SG_ 1542 DebugOutput7 0;
BA_ "GenSigTimeoutMsg_HU_B" SG_ 1542 DebugOutput7 0;
BA_ "GenSigTimeoutMsg_HU_A" SG_ 1542 DebugOutput7 0;
BA_ "GenSigSendType" SG_ 1542 DebugOutput7 1;
BA_ "GenSigTimeoutTime_HU_B" SG_ 1543 DebugOutput8 0;
BA_ "GenSigTimeoutTime_HU_A" SG_ 1543 DebugOutput8 0;
BA_ "GenSigTimeoutMsg_HU_B" SG_ 1543 DebugOutput8 0;
BA_ "GenSigTimeoutMsg_HU_A" SG_ 1543 DebugOutput8 0;
BA_ "GenSigSendType" SG_ 1543 DebugOutput8 1;
BA_ "GenSigTimeoutTime_HU_B" SG_ 1544 DebugInput 0;
BA_ "GenSigTimeoutTime_HU_A" SG_ 1544 DebugInput 0;
BA_ "GenSigTimeoutMsg_HU_B" SG_ 1544 DebugInput 0;
BA_ "GenSigTimeoutMsg_HU_A" SG_ 1544 DebugInput 0;
BA_ "GenSigSendType" SG_ 1544 DebugInput 1;
BA_ "GenSigTimeoutTime_HU_Mid_X451" SG_ 1545 BCM_DiagResponse_UUDT 0;
BA_ "GenSigTimeoutTime_HU_High_X451" SG_ 1545 BCM_DiagResponse_UUDT 0;
BA_ "GenSigTimeoutTime_HU_B" SG_ 1545 BCM_DiagResponse_UUDT 0;
BA_ "GenSigTimeoutTime_HU_A" SG_ 1545 BCM_DiagResponse_UUDT 0;
BA_ "GenSigTimeoutMsg_HU_Mid_X451" SG_ 1545 BCM_DiagResponse_UUDT 0;
BA_ "GenSigTimeoutMsg_HU_High_X451" SG_ 1545 BCM_DiagResponse_UUDT 0;
BA_ "GenSigTimeoutMsg_HU_B" SG_ 1545 BCM_DiagResponse_UUDT 0;
BA_ "GenSigTimeoutMsg_HU_A" SG_ 1545 BCM_DiagResponse_UUDT 0;
BA_ "GenSigSendType" SG_ 1545 BCM_DiagResponse_UUDT 1;
BA_ "GenSigTimeoutMsg_HU_High_X445" SG_ 1545 BCM_DiagResponse_UUDT 0;
BA_ "GenSigTimeoutMsg_HU_Mid_X445" SG_ 1545 BCM_DiagResponse_UUDT 0;
BA_ "GenSigTimeoutTime_HU_High_X445" SG_ 1545 BCM_DiagResponse_UUDT 0;
BA_ "GenSigTimeoutTime_HU_Mid_X445" SG_ 1545 BCM_DiagResponse_UUDT 0;
BA_ "GenSigTimeoutMsg_IVI" SG_ 1545 BCM_DiagResponse_UUDT 0;
BA_ "GenSigTimeoutTime_IVI" SG_ 1545 BCM_DiagResponse_UUDT 0;
BA_ "GenSigTimeoutTime_HU_Mid_X451" SG_ 1546 SRS_DiagResponse_UUDT 0;
BA_ "GenSigTimeoutTime_HU_High_X451" SG_ 1546 SRS_DiagResponse_UUDT 0;
BA_ "GenSigTimeoutTime_HU_B" SG_ 1546 SRS_DiagResponse_UUDT 0;
BA_ "GenSigTimeoutTime_HU_A" SG_ 1546 SRS_DiagResponse_UUDT 0;
BA_ "GenSigTimeoutMsg_HU_Mid_X451" SG_ 1546 SRS_DiagResponse_UUDT 0;
BA_ "GenSigTimeoutMsg_HU_High_X451" SG_ 1546 SRS_DiagResponse_UUDT 0;
BA_ "GenSigTimeoutMsg_HU_B" SG_ 1546 SRS_DiagResponse_UUDT 0;
BA_ "GenSigTimeoutMsg_HU_A" SG_ 1546 SRS_DiagResponse_UUDT 0;
BA_ "GenSigSendType" SG_ 1546 SRS_DiagResponse_UUDT 1;
BA_ "GenSigTimeoutMsg_HU_High_X445" SG_ 1546 SRS_DiagResponse_UUDT 0;
BA_ "GenSigTimeoutMsg_HU_Mid_X445" SG_ 1546 SRS_DiagResponse_UUDT 0;
BA_ "GenSigTimeoutTime_HU_High_X445" SG_ 1546 SRS_DiagResponse_UUDT 0;
BA_ "GenSigTimeoutTime_HU_Mid_X445" SG_ 1546 SRS_DiagResponse_UUDT 0;
BA_ "GenSigTimeoutMsg_IVI" SG_ 1546 SRS_DiagResponse_UUDT 0;
BA_ "GenSigTimeoutTime_IVI" SG_ 1546 SRS_DiagResponse_UUDT 0;
BA_ "GenSigTimeoutTime_HU_Mid_X451" SG_ 1547 HU_DiagResponse_UUDT 0;
BA_ "GenSigTimeoutTime_HU_High_X451" SG_ 1547 HU_DiagResponse_UUDT 0;
BA_ "GenSigTimeoutTime_HU_B" SG_ 1547 HU_DiagResponse_UUDT 0;
BA_ "GenSigTimeoutTime_HU_A" SG_ 1547 HU_DiagResponse_UUDT 0;
BA_ "GenSigTimeoutMsg_HU_Mid_X451" SG_ 1547 HU_DiagResponse_UUDT 0;
BA_ "GenSigTimeoutMsg_HU_High_X451" SG_ 1547 HU_DiagResponse_UUDT 0;
BA_ "GenSigTimeoutMsg_HU_B" SG_ 1547 HU_DiagResponse_UUDT 0;
BA_ "GenSigTimeoutMsg_HU_A" SG_ 1547 HU_DiagResponse_UUDT 0;
BA_ "GenSigSendType" SG_ 1547 HU_DiagResponse_UUDT 7;
BA_ "GenSigTimeoutMsg_HU_High_X445" SG_ 1547 HU_DiagResponse_UUDT 0;
BA_ "GenSigTimeoutMsg_HU_Mid_X445" SG_ 1547 HU_DiagResponse_UUDT 0;
BA_ "GenSigTimeoutTime_HU_High_X445" SG_ 1547 HU_DiagResponse_UUDT 0;
BA_ "GenSigTimeoutTime_HU_Mid_X445" SG_ 1547 HU_DiagResponse_UUDT 0;
BA_ "GenSigTimeoutMsg_IVI" SG_ 1547 HU_DiagResponse_UUDT 0;
BA_ "GenSigTimeoutTime_IVI" SG_ 1547 HU_DiagResponse_UUDT 0;
BA_ "GenSigTimeoutTime_HU_Mid_X451" SG_ 1548 VICM_DiagResponse_UUDT 0;
BA_ "GenSigTimeoutTime_HU_High_X451" SG_ 1548 VICM_DiagResponse_UUDT 0;
BA_ "GenSigTimeoutTime_HU_B" SG_ 1548 VICM_DiagResponse_UUDT 0;
BA_ "GenSigTimeoutTime_HU_A" SG_ 1548 VICM_DiagResponse_UUDT 0;
BA_ "GenSigTimeoutMsg_HU_Mid_X451" SG_ 1548 VICM_DiagResponse_UUDT 0;
BA_ "GenSigTimeoutMsg_HU_High_X451" SG_ 1548 VICM_DiagResponse_UUDT 0;
BA_ "GenSigTimeoutMsg_HU_B" SG_ 1548 VICM_DiagResponse_UUDT 0;
BA_ "GenSigTimeoutMsg_HU_A" SG_ 1548 VICM_DiagResponse_UUDT 0;
BA_ "GenSigSendType" SG_ 1548 VICM_DiagResponse_UUDT 1;
BA_ "GenSigTimeoutMsg_HU_High_X445" SG_ 1548 VICM_DiagResponse_UUDT 0;
BA_ "GenSigTimeoutMsg_HU_Mid_X445" SG_ 1548 VICM_DiagResponse_UUDT 0;
BA_ "GenSigTimeoutTime_HU_High_X445" SG_ 1548 VICM_DiagResponse_UUDT 0;
BA_ "GenSigTimeoutTime_HU_Mid_X445" SG_ 1548 VICM_DiagResponse_UUDT 0;
BA_ "GenSigTimeoutMsg_IVI" SG_ 1548 VICM_DiagResponse_UUDT 0;
BA_ "GenSigTimeoutTime_IVI" SG_ 1548 VICM_DiagResponse_UUDT 0;
BA_ "GenSigTimeoutTime_HU_Mid_X451" SG_ 1549 CCM_DiagResponse_UUDT 0;
BA_ "GenSigTimeoutTime_HU_High_X451" SG_ 1549 CCM_DiagResponse_UUDT 0;
BA_ "GenSigTimeoutTime_HU_B" SG_ 1549 CCM_DiagResponse_UUDT 0;
BA_ "GenSigTimeoutTime_HU_A" SG_ 1549 CCM_DiagResponse_UUDT 0;
BA_ "GenSigTimeoutMsg_HU_Mid_X451" SG_ 1549 CCM_DiagResponse_UUDT 0;
BA_ "GenSigTimeoutMsg_HU_High_X451" SG_ 1549 CCM_DiagResponse_UUDT 0;
BA_ "GenSigTimeoutMsg_HU_B" SG_ 1549 CCM_DiagResponse_UUDT 0;
BA_ "GenSigTimeoutMsg_HU_A" SG_ 1549 CCM_DiagResponse_UUDT 0;
BA_ "GenSigSendType" SG_ 1549 CCM_DiagResponse_UUDT 1;
BA_ "GenSigTimeoutMsg_HU_High_X445" SG_ 1549 CCM_DiagResponse_UUDT 0;
BA_ "GenSigTimeoutMsg_HU_Mid_X445" SG_ 1549 CCM_DiagResponse_UUDT 0;
BA_ "GenSigTimeoutTime_HU_High_X445" SG_ 1549 CCM_DiagResponse_UUDT 0;
BA_ "GenSigTimeoutTime_HU_Mid_X445" SG_ 1549 CCM_DiagResponse_UUDT 0;
BA_ "GenSigTimeoutMsg_IVI" SG_ 1549 CCM_DiagResponse_UUDT 0;
BA_ "GenSigTimeoutTime_IVI" SG_ 1549 CCM_DiagResponse_UUDT 0;
BA_ "GenSigTimeoutTime_HU_Mid_X451" SG_ 1560 PEPS_DiagResponse_UUDT 0;
BA_ "GenSigTimeoutTime_HU_High_X451" SG_ 1560 PEPS_DiagResponse_UUDT 0;
BA_ "GenSigTimeoutTime_HU_B" SG_ 1560 PEPS_DiagResponse_UUDT 0;
BA_ "GenSigTimeoutTime_HU_A" SG_ 1560 PEPS_DiagResponse_UUDT 0;
BA_ "GenSigTimeoutMsg_HU_Mid_X451" SG_ 1560 PEPS_DiagResponse_UUDT 0;
BA_ "GenSigTimeoutMsg_HU_High_X451" SG_ 1560 PEPS_DiagResponse_UUDT 0;
BA_ "GenSigTimeoutMsg_HU_B" SG_ 1560 PEPS_DiagResponse_UUDT 0;
BA_ "GenSigTimeoutMsg_HU_A" SG_ 1560 PEPS_DiagResponse_UUDT 0;
BA_ "GenSigSendType" SG_ 1560 PEPS_DiagResponse_UUDT 1;
BA_ "GenSigTimeoutMsg_HU_High_X445" SG_ 1560 PEPS_DiagResponse_UUDT 0;
BA_ "GenSigTimeoutMsg_HU_Mid_X445" SG_ 1560 PEPS_DiagResponse_UUDT 0;
BA_ "GenSigTimeoutTime_HU_High_X445" SG_ 1560 PEPS_DiagResponse_UUDT 0;
BA_ "GenSigTimeoutTime_HU_Mid_X445" SG_ 1560 PEPS_DiagResponse_UUDT 0;
BA_ "GenSigTimeoutMsg_IVI" SG_ 1560 PEPS_DiagResponse_UUDT 0;
BA_ "GenSigTimeoutTime_IVI" SG_ 1560 PEPS_DiagResponse_UUDT 0;
BA_ "GenSigTimeoutTime_HU_Mid_X451" SG_ 1564 PDC_DiagResponse_UUDT 0;
BA_ "GenSigTimeoutTime_HU_High_X451" SG_ 1564 PDC_DiagResponse_UUDT 0;
BA_ "GenSigTimeoutTime_HU_B" SG_ 1564 PDC_DiagResponse_UUDT 0;
BA_ "GenSigTimeoutTime_HU_A" SG_ 1564 PDC_DiagResponse_UUDT 0;
BA_ "GenSigTimeoutMsg_HU_Mid_X451" SG_ 1564 PDC_DiagResponse_UUDT 0;
BA_ "GenSigTimeoutMsg_HU_High_X451" SG_ 1564 PDC_DiagResponse_UUDT 0;
BA_ "GenSigTimeoutMsg_HU_B" SG_ 1564 PDC_DiagResponse_UUDT 0;
BA_ "GenSigTimeoutMsg_HU_A" SG_ 1564 PDC_DiagResponse_UUDT 0;
BA_ "GenSigSendType" SG_ 1564 PDC_DiagResponse_UUDT 1;
BA_ "GenSigTimeoutMsg_HU_High_X445" SG_ 1564 PDC_DiagResponse_UUDT 0;
BA_ "GenSigTimeoutMsg_HU_Mid_X445" SG_ 1564 PDC_DiagResponse_UUDT 0;
BA_ "GenSigTimeoutTime_HU_High_X445" SG_ 1564 PDC_DiagResponse_UUDT 0;
BA_ "GenSigTimeoutTime_HU_Mid_X445" SG_ 1564 PDC_DiagResponse_UUDT 0;
BA_ "GenSigTimeoutMsg_IVI" SG_ 1564 PDC_DiagResponse_UUDT 0;
BA_ "GenSigTimeoutTime_IVI" SG_ 1564 PDC_DiagResponse_UUDT 0;
BA_ "GenSigTimeoutTime_HU_Mid_X451" SG_ 1624 ESP_DiagResponse_UUDT 0;
BA_ "GenSigTimeoutTime_HU_High_X451" SG_ 1624 ESP_DiagResponse_UUDT 0;
BA_ "GenSigTimeoutTime_HU_B" SG_ 1624 ESP_DiagResponse_UUDT 0;
BA_ "GenSigTimeoutTime_HU_A" SG_ 1624 ESP_DiagResponse_UUDT 0;
BA_ "GenSigTimeoutMsg_HU_Mid_X451" SG_ 1624 ESP_DiagResponse_UUDT 0;
BA_ "GenSigTimeoutMsg_HU_High_X451" SG_ 1624 ESP_DiagResponse_UUDT 0;
BA_ "GenSigTimeoutMsg_HU_B" SG_ 1624 ESP_DiagResponse_UUDT 0;
BA_ "GenSigTimeoutMsg_HU_A" SG_ 1624 ESP_DiagResponse_UUDT 0;
BA_ "GenSigSendType" SG_ 1624 ESP_DiagResponse_UUDT 1;
BA_ "GenSigTimeoutMsg_HU_High_X445" SG_ 1624 ESP_DiagResponse_UUDT 0;
BA_ "GenSigTimeoutMsg_HU_Mid_X445" SG_ 1624 ESP_DiagResponse_UUDT 0;
BA_ "GenSigTimeoutTime_HU_High_X445" SG_ 1624 ESP_DiagResponse_UUDT 0;
BA_ "GenSigTimeoutTime_HU_Mid_X445" SG_ 1624 ESP_DiagResponse_UUDT 0;
BA_ "GenSigTimeoutMsg_IVI" SG_ 1624 ESP_DiagResponse_UUDT 0;
BA_ "GenSigTimeoutTime_IVI" SG_ 1624 ESP_DiagResponse_UUDT 0;
BA_ "GenSigTimeoutTime_HU_Mid_X451" SG_ 1626 EPAS_DiagResponse_UUDT 0;
BA_ "GenSigTimeoutTime_HU_High_X451" SG_ 1626 EPAS_DiagResponse_UUDT 0;
BA_ "GenSigTimeoutTime_HU_B" SG_ 1626 EPAS_DiagResponse_UUDT 0;
BA_ "GenSigTimeoutTime_HU_A" SG_ 1626 EPAS_DiagResponse_UUDT 0;
BA_ "GenSigTimeoutMsg_HU_Mid_X451" SG_ 1626 EPAS_DiagResponse_UUDT 0;
BA_ "GenSigTimeoutMsg_HU_High_X451" SG_ 1626 EPAS_DiagResponse_UUDT 0;
BA_ "GenSigTimeoutMsg_HU_B" SG_ 1626 EPAS_DiagResponse_UUDT 0;
BA_ "GenSigTimeoutMsg_HU_A" SG_ 1626 EPAS_DiagResponse_UUDT 0;
BA_ "GenSigSendType" SG_ 1626 EPAS_DiagResponse_UUDT 1;
BA_ "GenSigTimeoutMsg_HU_High_X445" SG_ 1626 EPAS_DiagResponse_UUDT 0;
BA_ "GenSigTimeoutMsg_HU_Mid_X445" SG_ 1626 EPAS_DiagResponse_UUDT 0;
BA_ "GenSigTimeoutTime_HU_High_X445" SG_ 1626 EPAS_DiagResponse_UUDT 0;
BA_ "GenSigTimeoutTime_HU_Mid_X445" SG_ 1626 EPAS_DiagResponse_UUDT 0;
BA_ "GenSigTimeoutMsg_IVI" SG_ 1626 EPAS_DiagResponse_UUDT 0;
BA_ "GenSigTimeoutTime_IVI" SG_ 1626 EPAS_DiagResponse_UUDT 0;
BA_ "GenSigTimeoutTime_HU_B" SG_ 1669 DCS_DebugOutput1 0;
BA_ "GenSigTimeoutTime_HU_A" SG_ 1669 DCS_DebugOutput1 0;
BA_ "GenSigTimeoutMsg_HU_B" SG_ 1669 DCS_DebugOutput1 0;
BA_ "GenSigTimeoutMsg_HU_A" SG_ 1669 DCS_DebugOutput1 0;
BA_ "GenSigSendType" SG_ 1669 DCS_DebugOutput1 1;
BA_ "GenSigTimeoutTime_HU_B" SG_ 1670 DCS_DebugInput 0;
BA_ "GenSigTimeoutTime_HU_A" SG_ 1670 DCS_DebugInput 0;
BA_ "GenSigTimeoutMsg_HU_B" SG_ 1670 DCS_DebugInput 0;
BA_ "GenSigTimeoutMsg_HU_A" SG_ 1670 DCS_DebugInput 0;
BA_ "GenSigSendType" SG_ 1670 DCS_DebugInput 1;
BA_ "GenSigTimeoutTime_HU_B" SG_ 1671 DCS_DebugOutput2 0;
BA_ "GenSigTimeoutTime_HU_A" SG_ 1671 DCS_DebugOutput2 0;
BA_ "GenSigTimeoutMsg_HU_B" SG_ 1671 DCS_DebugOutput2 0;
BA_ "GenSigTimeoutMsg_HU_A" SG_ 1671 DCS_DebugOutput2 0;
BA_ "GenSigSendType" SG_ 1671 DCS_DebugOutput2 1;
BA_ "GenSigTimeoutTime_HU_Mid_X451" SG_ 1768 EMS_DiagResponse_UUDT 0;
BA_ "GenSigTimeoutTime_HU_High_X451" SG_ 1768 EMS_DiagResponse_UUDT 0;
BA_ "GenSigTimeoutTime_HU_B" SG_ 1768 EMS_DiagResponse_UUDT 0;
BA_ "GenSigTimeoutTime_HU_A" SG_ 1768 EMS_DiagResponse_UUDT 0;
BA_ "GenSigTimeoutMsg_HU_Mid_X451" SG_ 1768 EMS_DiagResponse_UUDT 0;
BA_ "GenSigTimeoutMsg_HU_High_X451" SG_ 1768 EMS_DiagResponse_UUDT 0;
BA_ "GenSigTimeoutMsg_HU_B" SG_ 1768 EMS_DiagResponse_UUDT 0;
BA_ "GenSigTimeoutMsg_HU_A" SG_ 1768 EMS_DiagResponse_UUDT 0;
BA_ "GenSigSendType" SG_ 1768 EMS_DiagResponse_UUDT 1;
BA_ "GenSigTimeoutMsg_HU_High_X445" SG_ 1768 EMS_DiagResponse_UUDT 0;
BA_ "GenSigTimeoutMsg_HU_Mid_X445" SG_ 1768 EMS_DiagResponse_UUDT 0;
BA_ "GenSigTimeoutTime_HU_High_X445" SG_ 1768 EMS_DiagResponse_UUDT 0;
BA_ "GenSigTimeoutTime_HU_Mid_X445" SG_ 1768 EMS_DiagResponse_UUDT 0;
BA_ "GenSigTimeoutMsg_IVI" SG_ 1768 EMS_DiagResponse_UUDT 0;
BA_ "GenSigTimeoutTime_IVI" SG_ 1768 EMS_DiagResponse_UUDT 0;
BA_ "GenSigTimeoutTime_HU_Mid_X451" SG_ 1769 AMT_DCT_DiagResponse_UUDT 0;
BA_ "GenSigTimeoutTime_HU_High_X451" SG_ 1769 AMT_DCT_DiagResponse_UUDT 0;
BA_ "GenSigTimeoutTime_HU_B" SG_ 1769 AMT_DCT_DiagResponse_UUDT 0;
BA_ "GenSigTimeoutTime_HU_A" SG_ 1769 AMT_DCT_DiagResponse_UUDT 0;
BA_ "GenSigTimeoutMsg_HU_Mid_X451" SG_ 1769 AMT_DCT_DiagResponse_UUDT 0;
BA_ "GenSigTimeoutMsg_HU_High_X451" SG_ 1769 AMT_DCT_DiagResponse_UUDT 0;
BA_ "GenSigTimeoutMsg_HU_B" SG_ 1769 AMT_DCT_DiagResponse_UUDT 0;
BA_ "GenSigTimeoutMsg_HU_A" SG_ 1769 AMT_DCT_DiagResponse_UUDT 0;
BA_ "GenSigSendType" SG_ 1769 AMT_DCT_DiagResponse_UUDT 1;
BA_ "GenSigTimeoutMsg_HU_High_X445" SG_ 1769 AMT_DCT_DiagResponse_UUDT 0;
BA_ "GenSigTimeoutMsg_HU_Mid_X445" SG_ 1769 AMT_DCT_DiagResponse_UUDT 0;
BA_ "GenSigTimeoutTime_HU_High_X445" SG_ 1769 AMT_DCT_DiagResponse_UUDT 0;
BA_ "GenSigTimeoutTime_HU_Mid_X445" SG_ 1769 AMT_DCT_DiagResponse_UUDT 0;
BA_ "GenSigTimeoutMsg_IVI" SG_ 1769 AMT_DCT_DiagResponse_UUDT 0;
BA_ "GenSigTimeoutTime_IVI" SG_ 1769 AMT_DCT_DiagResponse_UUDT 0;
BA_ "GenSigTimeoutTime_HU_Mid_X451" SG_ 1793 BCM_DiagRequest 0;
BA_ "GenSigTimeoutTime_HU_High_X451" SG_ 1793 BCM_DiagRequest 0;
BA_ "GenSigTimeoutTime_HU_B" SG_ 1793 BCM_DiagRequest 0;
BA_ "GenSigTimeoutTime_HU_A" SG_ 1793 BCM_DiagRequest 0;
BA_ "GenSigTimeoutMsg_HU_Mid_X451" SG_ 1793 BCM_DiagRequest 0;
BA_ "GenSigTimeoutMsg_HU_High_X451" SG_ 1793 BCM_DiagRequest 0;
BA_ "GenSigTimeoutMsg_HU_B" SG_ 1793 BCM_DiagRequest 0;
BA_ "GenSigTimeoutMsg_HU_A" SG_ 1793 BCM_DiagRequest 0;
BA_ "GenSigSendType" SG_ 1793 BCM_DiagRequest 1;
BA_ "GenSigTimeoutMsg_HU_High_X445" SG_ 1793 BCM_DiagRequest 0;
BA_ "GenSigTimeoutMsg_HU_Mid_X445" SG_ 1793 BCM_DiagRequest 0;
BA_ "GenSigTimeoutTime_HU_High_X445" SG_ 1793 BCM_DiagRequest 0;
BA_ "GenSigTimeoutTime_HU_Mid_X445" SG_ 1793 BCM_DiagRequest 0;
BA_ "GenSigTimeoutMsg_IVI" SG_ 1793 BCM_DiagRequest 0;
BA_ "GenSigTimeoutTime_IVI" SG_ 1793 BCM_DiagRequest 0;
BA_ "GenSigTimeoutTime_HU_Mid_X451" SG_ 1794 SRS_DiagRequest 0;
BA_ "GenSigTimeoutTime_HU_High_X451" SG_ 1794 SRS_DiagRequest 0;
BA_ "GenSigTimeoutTime_HU_B" SG_ 1794 SRS_DiagRequest 0;
BA_ "GenSigTimeoutTime_HU_A" SG_ 1794 SRS_DiagRequest 0;
BA_ "GenSigTimeoutMsg_HU_Mid_X451" SG_ 1794 SRS_DiagRequest 0;
BA_ "GenSigTimeoutMsg_HU_High_X451" SG_ 1794 SRS_DiagRequest 0;
BA_ "GenSigTimeoutMsg_HU_B" SG_ 1794 SRS_DiagRequest 0;
BA_ "GenSigTimeoutMsg_HU_A" SG_ 1794 SRS_DiagRequest 0;
BA_ "GenSigSendType" SG_ 1794 SRS_DiagRequest 1;
BA_ "GenSigTimeoutMsg_HU_High_X445" SG_ 1794 SRS_DiagRequest 0;
BA_ "GenSigTimeoutMsg_HU_Mid_X445" SG_ 1794 SRS_DiagRequest 0;
BA_ "GenSigTimeoutTime_HU_High_X445" SG_ 1794 SRS_DiagRequest 0;
BA_ "GenSigTimeoutTime_HU_Mid_X445" SG_ 1794 SRS_DiagRequest 0;
BA_ "GenSigTimeoutMsg_IVI" SG_ 1794 SRS_DiagRequest 0;
BA_ "GenSigTimeoutTime_IVI" SG_ 1794 SRS_DiagRequest 0;
BA_ "GenSigTimeoutTime_HU_Mid_X451" SG_ 1795 DiagMsg 0;
BA_ "GenSigTimeoutTime_HU_High_X451" SG_ 1795 DiagMsg 0;
BA_ "GenSigTimeoutTime_HU_B" SG_ 1795 DiagMsg 0;
BA_ "GenSigTimeoutTime_HU_A" SG_ 1795 DiagMsg 0;
BA_ "GenSigTimeoutMsg_HU_Mid_X451" SG_ 1795 DiagMsg 0;
BA_ "GenSigTimeoutMsg_HU_High_X451" SG_ 1795 DiagMsg 0;
BA_ "GenSigTimeoutMsg_HU_B" SG_ 1795 DiagMsg 0;
BA_ "GenSigTimeoutMsg_HU_A" SG_ 1795 DiagMsg 0;
BA_ "GenSigSendType" SG_ 1795 DiagMsg 1;
BA_ "GenSigTimeoutMsg_HU_High_X445" SG_ 1795 DiagMsg 0;
BA_ "GenSigTimeoutMsg_HU_Mid_X445" SG_ 1795 DiagMsg 0;
BA_ "GenSigTimeoutTime_HU_High_X445" SG_ 1795 DiagMsg 0;
BA_ "GenSigTimeoutTime_HU_Mid_X445" SG_ 1795 DiagMsg 0;
BA_ "GenSigTimeoutMsg_IVI" SG_ 1795 DiagMsg 0;
BA_ "GenSigTimeoutTime_IVI" SG_ 1795 DiagMsg 0;
BA_ "GenSigTimeoutTime_HU_Mid_X451" SG_ 1796 VICM_DiagRequest 0;
BA_ "GenSigTimeoutTime_HU_High_X451" SG_ 1796 VICM_DiagRequest 0;
BA_ "GenSigTimeoutTime_HU_B" SG_ 1796 VICM_DiagRequest 0;
BA_ "GenSigTimeoutTime_HU_A" SG_ 1796 VICM_DiagRequest 0;
BA_ "GenSigTimeoutMsg_HU_Mid_X451" SG_ 1796 VICM_DiagRequest 0;
BA_ "GenSigTimeoutMsg_HU_High_X451" SG_ 1796 VICM_DiagRequest 0;
BA_ "GenSigTimeoutMsg_HU_B" SG_ 1796 VICM_DiagRequest 0;
BA_ "GenSigTimeoutMsg_HU_A" SG_ 1796 VICM_DiagRequest 0;
BA_ "GenSigSendType" SG_ 1796 VICM_DiagRequest 1;
BA_ "GenSigTimeoutMsg_HU_High_X445" SG_ 1796 VICM_DiagRequest 0;
BA_ "GenSigTimeoutMsg_HU_Mid_X445" SG_ 1796 VICM_DiagRequest 0;
BA_ "GenSigTimeoutTime_HU_High_X445" SG_ 1796 VICM_DiagRequest 0;
BA_ "GenSigTimeoutTime_HU_Mid_X445" SG_ 1796 VICM_DiagRequest 0;
BA_ "GenSigTimeoutMsg_IVI" SG_ 1796 VICM_DiagRequest 0;
BA_ "GenSigTimeoutTime_IVI" SG_ 1796 VICM_DiagRequest 0;
BA_ "GenSigTimeoutTime_HU_Mid_X451" SG_ 1797 CCM_DiagRequest 0;
BA_ "GenSigTimeoutTime_HU_High_X451" SG_ 1797 CCM_DiagRequest 0;
BA_ "GenSigTimeoutTime_HU_B" SG_ 1797 CCM_DiagRequest 0;
BA_ "GenSigTimeoutTime_HU_A" SG_ 1797 CCM_DiagRequest 0;
BA_ "GenSigTimeoutMsg_HU_Mid_X451" SG_ 1797 CCM_DiagRequest 0;
BA_ "GenSigTimeoutMsg_HU_High_X451" SG_ 1797 CCM_DiagRequest 0;
BA_ "GenSigTimeoutMsg_HU_B" SG_ 1797 CCM_DiagRequest 0;
BA_ "GenSigTimeoutMsg_HU_A" SG_ 1797 CCM_DiagRequest 0;
BA_ "GenSigSendType" SG_ 1797 CCM_DiagRequest 1;
BA_ "GenSigTimeoutMsg_HU_High_X445" SG_ 1797 CCM_DiagRequest 0;
BA_ "GenSigTimeoutMsg_HU_Mid_X445" SG_ 1797 CCM_DiagRequest 0;
BA_ "GenSigTimeoutTime_HU_High_X445" SG_ 1797 CCM_DiagRequest 0;
BA_ "GenSigTimeoutTime_HU_Mid_X445" SG_ 1797 CCM_DiagRequest 0;
BA_ "GenSigTimeoutMsg_IVI" SG_ 1797 CCM_DiagRequest 0;
BA_ "GenSigTimeoutTime_IVI" SG_ 1797 CCM_DiagRequest 0;
BA_ "GenSigTimeoutTime_HU_Mid_X451" SG_ 1801 BCM_DiagResponse_USDT 0;
BA_ "GenSigTimeoutTime_HU_High_X451" SG_ 1801 BCM_DiagResponse_USDT 0;
BA_ "GenSigTimeoutTime_HU_B" SG_ 1801 BCM_DiagResponse_USDT 0;
BA_ "GenSigTimeoutTime_HU_A" SG_ 1801 BCM_DiagResponse_USDT 0;
BA_ "GenSigTimeoutMsg_HU_Mid_X451" SG_ 1801 BCM_DiagResponse_USDT 0;
BA_ "GenSigTimeoutMsg_HU_High_X451" SG_ 1801 BCM_DiagResponse_USDT 0;
BA_ "GenSigTimeoutMsg_HU_B" SG_ 1801 BCM_DiagResponse_USDT 0;
BA_ "GenSigTimeoutMsg_HU_A" SG_ 1801 BCM_DiagResponse_USDT 0;
BA_ "GenSigSendType" SG_ 1801 BCM_DiagResponse_USDT 1;
BA_ "GenSigTimeoutMsg_HU_High_X445" SG_ 1801 BCM_DiagResponse_USDT 0;
BA_ "GenSigTimeoutMsg_HU_Mid_X445" SG_ 1801 BCM_DiagResponse_USDT 0;
BA_ "GenSigTimeoutTime_HU_High_X445" SG_ 1801 BCM_DiagResponse_USDT 0;
BA_ "GenSigTimeoutTime_HU_Mid_X445" SG_ 1801 BCM_DiagResponse_USDT 0;
BA_ "GenSigTimeoutMsg_IVI" SG_ 1801 BCM_DiagResponse_USDT 0;
BA_ "GenSigTimeoutTime_IVI" SG_ 1801 BCM_DiagResponse_USDT 0;
BA_ "GenSigTimeoutTime_HU_Mid_X451" SG_ 1802 SRS_DiagResponse_USDT 0;
BA_ "GenSigTimeoutTime_HU_High_X451" SG_ 1802 SRS_DiagResponse_USDT 0;
BA_ "GenSigTimeoutTime_HU_B" SG_ 1802 SRS_DiagResponse_USDT 0;
BA_ "GenSigTimeoutTime_HU_A" SG_ 1802 SRS_DiagResponse_USDT 0;
BA_ "GenSigTimeoutMsg_HU_Mid_X451" SG_ 1802 SRS_DiagResponse_USDT 0;
BA_ "GenSigTimeoutMsg_HU_High_X451" SG_ 1802 SRS_DiagResponse_USDT 0;
BA_ "GenSigTimeoutMsg_HU_B" SG_ 1802 SRS_DiagResponse_USDT 0;
BA_ "GenSigTimeoutMsg_HU_A" SG_ 1802 SRS_DiagResponse_USDT 0;
BA_ "GenSigSendType" SG_ 1802 SRS_DiagResponse_USDT 1;
BA_ "GenSigTimeoutMsg_HU_High_X445" SG_ 1802 SRS_DiagResponse_USDT 0;
BA_ "GenSigTimeoutMsg_HU_Mid_X445" SG_ 1802 SRS_DiagResponse_USDT 0;
BA_ "GenSigTimeoutTime_HU_High_X445" SG_ 1802 SRS_DiagResponse_USDT 0;
BA_ "GenSigTimeoutTime_HU_Mid_X445" SG_ 1802 SRS_DiagResponse_USDT 0;
BA_ "GenSigTimeoutMsg_IVI" SG_ 1802 SRS_DiagResponse_USDT 0;
BA_ "GenSigTimeoutTime_IVI" SG_ 1802 SRS_DiagResponse_USDT 0;
BA_ "GenSigTimeoutTime_HU_Mid_X451" SG_ 1803 HU_DiagResponse_USDT 0;
BA_ "GenSigTimeoutTime_HU_High_X451" SG_ 1803 HU_DiagResponse_USDT 0;
BA_ "GenSigTimeoutTime_HU_B" SG_ 1803 HU_DiagResponse_USDT 0;
BA_ "GenSigTimeoutTime_HU_A" SG_ 1803 HU_DiagResponse_USDT 0;
BA_ "GenSigTimeoutMsg_HU_Mid_X451" SG_ 1803 HU_DiagResponse_USDT 0;
BA_ "GenSigTimeoutMsg_HU_High_X451" SG_ 1803 HU_DiagResponse_USDT 0;
BA_ "GenSigTimeoutMsg_HU_B" SG_ 1803 HU_DiagResponse_USDT 0;
BA_ "GenSigTimeoutMsg_HU_A" SG_ 1803 HU_DiagResponse_USDT 0;
BA_ "GenSigSendType" SG_ 1803 HU_DiagResponse_USDT 7;
BA_ "GenSigTimeoutMsg_HU_High_X445" SG_ 1803 HU_DiagResponse_USDT 0;
BA_ "GenSigTimeoutMsg_HU_Mid_X445" SG_ 1803 HU_DiagResponse_USDT 0;
BA_ "GenSigTimeoutTime_HU_High_X445" SG_ 1803 HU_DiagResponse_USDT 0;
BA_ "GenSigTimeoutTime_HU_Mid_X445" SG_ 1803 HU_DiagResponse_USDT 0;
BA_ "GenSigTimeoutMsg_IVI" SG_ 1803 HU_DiagResponse_USDT 0;
BA_ "GenSigTimeoutTime_IVI" SG_ 1803 HU_DiagResponse_USDT 0;
BA_ "GenSigTimeoutTime_HU_Mid_X451" SG_ 1804 VICM_DiagResponse_USDT 0;
BA_ "GenSigTimeoutTime_HU_High_X451" SG_ 1804 VICM_DiagResponse_USDT 0;
BA_ "GenSigTimeoutTime_HU_B" SG_ 1804 VICM_DiagResponse_USDT 0;
BA_ "GenSigTimeoutTime_HU_A" SG_ 1804 VICM_DiagResponse_USDT 0;
BA_ "GenSigTimeoutMsg_HU_Mid_X451" SG_ 1804 VICM_DiagResponse_USDT 0;
BA_ "GenSigTimeoutMsg_HU_High_X451" SG_ 1804 VICM_DiagResponse_USDT 0;
BA_ "GenSigTimeoutMsg_HU_B" SG_ 1804 VICM_DiagResponse_USDT 0;
BA_ "GenSigTimeoutMsg_HU_A" SG_ 1804 VICM_DiagResponse_USDT 0;
BA_ "GenSigSendType" SG_ 1804 VICM_DiagResponse_USDT 1;
BA_ "GenSigTimeoutMsg_HU_High_X445" SG_ 1804 VICM_DiagResponse_USDT 0;
BA_ "GenSigTimeoutMsg_HU_Mid_X445" SG_ 1804 VICM_DiagResponse_USDT 0;
BA_ "GenSigTimeoutTime_HU_High_X445" SG_ 1804 VICM_DiagResponse_USDT 0;
BA_ "GenSigTimeoutTime_HU_Mid_X445" SG_ 1804 VICM_DiagResponse_USDT 0;
BA_ "GenSigTimeoutMsg_IVI" SG_ 1804 VICM_DiagResponse_USDT 0;
BA_ "GenSigTimeoutTime_IVI" SG_ 1804 VICM_DiagResponse_USDT 0;
BA_ "GenSigTimeoutTime_HU_Mid_X451" SG_ 1805 CCM_DiagResponse_USDT 0;
BA_ "GenSigTimeoutTime_HU_High_X451" SG_ 1805 CCM_DiagResponse_USDT 0;
BA_ "GenSigTimeoutTime_HU_B" SG_ 1805 CCM_DiagResponse_USDT 0;
BA_ "GenSigTimeoutTime_HU_A" SG_ 1805 CCM_DiagResponse_USDT 0;
BA_ "GenSigTimeoutMsg_HU_Mid_X451" SG_ 1805 CCM_DiagResponse_USDT 0;
BA_ "GenSigTimeoutMsg_HU_High_X451" SG_ 1805 CCM_DiagResponse_USDT 0;
BA_ "GenSigTimeoutMsg_HU_B" SG_ 1805 CCM_DiagResponse_USDT 0;
BA_ "GenSigTimeoutMsg_HU_A" SG_ 1805 CCM_DiagResponse_USDT 0;
BA_ "GenSigSendType" SG_ 1805 CCM_DiagResponse_USDT 1;
BA_ "GenSigTimeoutMsg_HU_High_X445" SG_ 1805 CCM_DiagResponse_USDT 0;
BA_ "GenSigTimeoutMsg_HU_Mid_X445" SG_ 1805 CCM_DiagResponse_USDT 0;
BA_ "GenSigTimeoutTime_HU_High_X445" SG_ 1805 CCM_DiagResponse_USDT 0;
BA_ "GenSigTimeoutTime_HU_Mid_X445" SG_ 1805 CCM_DiagResponse_USDT 0;
BA_ "GenSigTimeoutMsg_IVI" SG_ 1805 CCM_DiagResponse_USDT 0;
BA_ "GenSigTimeoutTime_IVI" SG_ 1805 CCM_DiagResponse_USDT 0;
BA_ "GenSigTimeoutTime_HU_Mid_X451" SG_ 1808 PEPS_DiagRequest_USDT 0;
BA_ "GenSigTimeoutTime_HU_High_X451" SG_ 1808 PEPS_DiagRequest_USDT 0;
BA_ "GenSigTimeoutTime_HU_B" SG_ 1808 PEPS_DiagRequest_USDT 0;
BA_ "GenSigTimeoutTime_HU_A" SG_ 1808 PEPS_DiagRequest_USDT 0;
BA_ "GenSigTimeoutMsg_HU_Mid_X451" SG_ 1808 PEPS_DiagRequest_USDT 0;
BA_ "GenSigTimeoutMsg_HU_High_X451" SG_ 1808 PEPS_DiagRequest_USDT 0;
BA_ "GenSigTimeoutMsg_HU_B" SG_ 1808 PEPS_DiagRequest_USDT 0;
BA_ "GenSigTimeoutMsg_HU_A" SG_ 1808 PEPS_DiagRequest_USDT 0;
BA_ "GenSigSendType" SG_ 1808 PEPS_DiagRequest_USDT 1;
BA_ "GenSigTimeoutMsg_HU_High_X445" SG_ 1808 PEPS_DiagRequest_USDT 0;
BA_ "GenSigTimeoutMsg_HU_Mid_X445" SG_ 1808 PEPS_DiagRequest_USDT 0;
BA_ "GenSigTimeoutTime_HU_High_X445" SG_ 1808 PEPS_DiagRequest_USDT 0;
BA_ "GenSigTimeoutTime_HU_Mid_X445" SG_ 1808 PEPS_DiagRequest_USDT 0;
BA_ "GenSigTimeoutMsg_IVI" SG_ 1808 PEPS_DiagRequest_USDT 0;
BA_ "GenSigTimeoutTime_IVI" SG_ 1808 PEPS_DiagRequest_USDT 0;
BA_ "GenSigTimeoutTime_HU_Mid_X451" SG_ 1812 PDC_DiagRequest 0;
BA_ "GenSigTimeoutTime_HU_High_X451" SG_ 1812 PDC_DiagRequest 0;
BA_ "GenSigTimeoutTime_HU_B" SG_ 1812 PDC_DiagRequest 0;
BA_ "GenSigTimeoutTime_HU_A" SG_ 1812 PDC_DiagRequest 0;
BA_ "GenSigTimeoutMsg_HU_Mid_X451" SG_ 1812 PDC_DiagRequest 0;
BA_ "GenSigTimeoutMsg_HU_High_X451" SG_ 1812 PDC_DiagRequest 0;
BA_ "GenSigTimeoutMsg_HU_B" SG_ 1812 PDC_DiagRequest 0;
BA_ "GenSigTimeoutMsg_HU_A" SG_ 1812 PDC_DiagRequest 0;
BA_ "GenSigSendType" SG_ 1812 PDC_DiagRequest 1;
BA_ "GenSigTimeoutMsg_HU_High_X445" SG_ 1812 PDC_DiagRequest 0;
BA_ "GenSigTimeoutMsg_HU_Mid_X445" SG_ 1812 PDC_DiagRequest 0;
BA_ "GenSigTimeoutTime_HU_High_X445" SG_ 1812 PDC_DiagRequest 0;
BA_ "GenSigTimeoutTime_HU_Mid_X445" SG_ 1812 PDC_DiagRequest 0;
BA_ "GenSigTimeoutMsg_IVI" SG_ 1812 PDC_DiagRequest 0;
BA_ "GenSigTimeoutTime_IVI" SG_ 1812 PDC_DiagRequest 0;
BA_ "GenSigTimeoutTime_HU_Mid_X451" SG_ 1816 PEPS_DiagResponse_USDT 0;
BA_ "GenSigTimeoutTime_HU_High_X451" SG_ 1816 PEPS_DiagResponse_USDT 0;
BA_ "GenSigTimeoutTime_HU_B" SG_ 1816 PEPS_DiagResponse_USDT 0;
BA_ "GenSigTimeoutTime_HU_A" SG_ 1816 PEPS_DiagResponse_USDT 0;
BA_ "GenSigTimeoutMsg_HU_Mid_X451" SG_ 1816 PEPS_DiagResponse_USDT 0;
BA_ "GenSigTimeoutMsg_HU_High_X451" SG_ 1816 PEPS_DiagResponse_USDT 0;
BA_ "GenSigTimeoutMsg_HU_B" SG_ 1816 PEPS_DiagResponse_USDT 0;
BA_ "GenSigTimeoutMsg_HU_A" SG_ 1816 PEPS_DiagResponse_USDT 0;
BA_ "GenSigSendType" SG_ 1816 PEPS_DiagResponse_USDT 1;
BA_ "GenSigTimeoutMsg_HU_High_X445" SG_ 1816 PEPS_DiagResponse_USDT 0;
BA_ "GenSigTimeoutMsg_HU_Mid_X445" SG_ 1816 PEPS_DiagResponse_USDT 0;
BA_ "GenSigTimeoutTime_HU_High_X445" SG_ 1816 PEPS_DiagResponse_USDT 0;
BA_ "GenSigTimeoutTime_HU_Mid_X445" SG_ 1816 PEPS_DiagResponse_USDT 0;
BA_ "GenSigTimeoutMsg_IVI" SG_ 1816 PEPS_DiagResponse_USDT 0;
BA_ "GenSigTimeoutTime_IVI" SG_ 1816 PEPS_DiagResponse_USDT 0;
BA_ "GenSigTimeoutTime_HU_Mid_X451" SG_ 1820 PDC_DiagResponse_USDT 0;
BA_ "GenSigTimeoutTime_HU_High_X451" SG_ 1820 PDC_DiagResponse_USDT 0;
BA_ "GenSigTimeoutTime_HU_B" SG_ 1820 PDC_DiagResponse_USDT 0;
BA_ "GenSigTimeoutTime_HU_A" SG_ 1820 PDC_DiagResponse_USDT 0;
BA_ "GenSigTimeoutMsg_HU_Mid_X451" SG_ 1820 PDC_DiagResponse_USDT 0;
BA_ "GenSigTimeoutMsg_HU_High_X451" SG_ 1820 PDC_DiagResponse_USDT 0;
BA_ "GenSigTimeoutMsg_HU_B" SG_ 1820 PDC_DiagResponse_USDT 0;
BA_ "GenSigTimeoutMsg_HU_A" SG_ 1820 PDC_DiagResponse_USDT 0;
BA_ "GenSigSendType" SG_ 1820 PDC_DiagResponse_USDT 1;
BA_ "GenSigTimeoutMsg_HU_High_X445" SG_ 1820 PDC_DiagResponse_USDT 0;
BA_ "GenSigTimeoutMsg_HU_Mid_X445" SG_ 1820 PDC_DiagResponse_USDT 0;
BA_ "GenSigTimeoutTime_HU_High_X445" SG_ 1820 PDC_DiagResponse_USDT 0;
BA_ "GenSigTimeoutTime_HU_Mid_X445" SG_ 1820 PDC_DiagResponse_USDT 0;
BA_ "GenSigTimeoutMsg_IVI" SG_ 1820 PDC_DiagResponse_USDT 0;
BA_ "GenSigTimeoutTime_IVI" SG_ 1820 PDC_DiagResponse_USDT 0;
BA_ "GenSigTimeoutTime_HU_Mid_X451" SG_ 1872 ESP_DiagRequest 0;
BA_ "GenSigTimeoutTime_HU_High_X451" SG_ 1872 ESP_DiagRequest 0;
BA_ "GenSigTimeoutTime_HU_B" SG_ 1872 ESP_DiagRequest 0;
BA_ "GenSigTimeoutTime_HU_A" SG_ 1872 ESP_DiagRequest 0;
BA_ "GenSigTimeoutMsg_HU_Mid_X451" SG_ 1872 ESP_DiagRequest 0;
BA_ "GenSigTimeoutMsg_HU_High_X451" SG_ 1872 ESP_DiagRequest 0;
BA_ "GenSigTimeoutMsg_HU_B" SG_ 1872 ESP_DiagRequest 0;
BA_ "GenSigTimeoutMsg_HU_A" SG_ 1872 ESP_DiagRequest 0;
BA_ "GenSigSendType" SG_ 1872 ESP_DiagRequest 1;
BA_ "GenSigTimeoutMsg_HU_High_X445" SG_ 1872 ESP_DiagRequest 0;
BA_ "GenSigTimeoutMsg_HU_Mid_X445" SG_ 1872 ESP_DiagRequest 0;
BA_ "GenSigTimeoutTime_HU_High_X445" SG_ 1872 ESP_DiagRequest 0;
BA_ "GenSigTimeoutTime_HU_Mid_X445" SG_ 1872 ESP_DiagRequest 0;
BA_ "GenSigTimeoutMsg_IVI" SG_ 1872 ESP_DiagRequest 0;
BA_ "GenSigTimeoutTime_IVI" SG_ 1872 ESP_DiagRequest 0;
BA_ "GenSigTimeoutTime_HU_Mid_X451" SG_ 1874 EPAS_DiagRequest 0;
BA_ "GenSigTimeoutTime_HU_High_X451" SG_ 1874 EPAS_DiagRequest 0;
BA_ "GenSigTimeoutTime_HU_B" SG_ 1874 EPAS_DiagRequest 0;
BA_ "GenSigTimeoutTime_HU_A" SG_ 1874 EPAS_DiagRequest 0;
BA_ "GenSigTimeoutMsg_HU_Mid_X451" SG_ 1874 EPAS_DiagRequest 0;
BA_ "GenSigTimeoutMsg_HU_High_X451" SG_ 1874 EPAS_DiagRequest 0;
BA_ "GenSigTimeoutMsg_HU_B" SG_ 1874 EPAS_DiagRequest 0;
BA_ "GenSigTimeoutMsg_HU_A" SG_ 1874 EPAS_DiagRequest 0;
BA_ "GenSigSendType" SG_ 1874 EPAS_DiagRequest 1;
BA_ "GenSigTimeoutMsg_HU_High_X445" SG_ 1874 EPAS_DiagRequest 0;
BA_ "GenSigTimeoutMsg_HU_Mid_X445" SG_ 1874 EPAS_DiagRequest 0;
BA_ "GenSigTimeoutTime_HU_High_X445" SG_ 1874 EPAS_DiagRequest 0;
BA_ "GenSigTimeoutTime_HU_Mid_X445" SG_ 1874 EPAS_DiagRequest 0;
BA_ "GenSigTimeoutMsg_IVI" SG_ 1874 EPAS_DiagRequest 0;
BA_ "GenSigTimeoutTime_IVI" SG_ 1874 EPAS_DiagRequest 0;
BA_ "GenSigTimeoutTime_HU_Mid_X451" SG_ 1876 ESCL_DiagRequest 0;
BA_ "GenSigTimeoutTime_HU_High_X451" SG_ 1876 ESCL_DiagRequest 0;
BA_ "GenSigTimeoutTime_HU_B" SG_ 1876 ESCL_DiagRequest 0;
BA_ "GenSigTimeoutTime_HU_A" SG_ 1876 ESCL_DiagRequest 0;
BA_ "GenSigTimeoutMsg_HU_Mid_X451" SG_ 1876 ESCL_DiagRequest 0;
BA_ "GenSigTimeoutMsg_HU_High_X451" SG_ 1876 ESCL_DiagRequest 0;
BA_ "GenSigTimeoutMsg_HU_B" SG_ 1876 ESCL_DiagRequest 0;
BA_ "GenSigTimeoutMsg_HU_A" SG_ 1876 ESCL_DiagRequest 0;
BA_ "GenSigSendType" SG_ 1876 ESCL_DiagRequest 1;
BA_ "GenSigTimeoutMsg_HU_High_X445" SG_ 1876 ESCL_DiagRequest 0;
BA_ "GenSigTimeoutMsg_HU_Mid_X445" SG_ 1876 ESCL_DiagRequest 0;
BA_ "GenSigTimeoutTime_HU_High_X445" SG_ 1876 ESCL_DiagRequest 0;
BA_ "GenSigTimeoutTime_HU_Mid_X445" SG_ 1876 ESCL_DiagRequest 0;
BA_ "GenSigTimeoutMsg_IVI" SG_ 1876 ESCL_DiagRequest 0;
BA_ "GenSigTimeoutTime_IVI" SG_ 1876 ESCL_DiagRequest 0;
BA_ "GenSigTimeoutTime_HU_Mid_X451" SG_ 1880 ESP_DiagResponse_USDT 0;
BA_ "GenSigTimeoutTime_HU_High_X451" SG_ 1880 ESP_DiagResponse_USDT 0;
BA_ "GenSigTimeoutTime_HU_B" SG_ 1880 ESP_DiagResponse_USDT 0;
BA_ "GenSigTimeoutTime_HU_A" SG_ 1880 ESP_DiagResponse_USDT 0;
BA_ "GenSigTimeoutMsg_HU_Mid_X451" SG_ 1880 ESP_DiagResponse_USDT 0;
BA_ "GenSigTimeoutMsg_HU_High_X451" SG_ 1880 ESP_DiagResponse_USDT 0;
BA_ "GenSigTimeoutMsg_HU_B" SG_ 1880 ESP_DiagResponse_USDT 0;
BA_ "GenSigTimeoutMsg_HU_A" SG_ 1880 ESP_DiagResponse_USDT 0;
BA_ "GenSigSendType" SG_ 1880 ESP_DiagResponse_USDT 1;
BA_ "GenSigTimeoutMsg_HU_High_X445" SG_ 1880 ESP_DiagResponse_USDT 0;
BA_ "GenSigTimeoutMsg_HU_Mid_X445" SG_ 1880 ESP_DiagResponse_USDT 0;
BA_ "GenSigTimeoutTime_HU_High_X445" SG_ 1880 ESP_DiagResponse_USDT 0;
BA_ "GenSigTimeoutTime_HU_Mid_X445" SG_ 1880 ESP_DiagResponse_USDT 0;
BA_ "GenSigTimeoutMsg_IVI" SG_ 1880 ESP_DiagResponse_USDT 0;
BA_ "GenSigTimeoutTime_IVI" SG_ 1880 ESP_DiagResponse_USDT 0;
BA_ "GenSigTimeoutTime_HU_Mid_X451" SG_ 1882 EPAS_DiagResponse_USDT 0;
BA_ "GenSigTimeoutTime_HU_High_X451" SG_ 1882 EPAS_DiagResponse_USDT 0;
BA_ "GenSigTimeoutTime_HU_B" SG_ 1882 EPAS_DiagResponse_USDT 0;
BA_ "GenSigTimeoutTime_HU_A" SG_ 1882 EPAS_DiagResponse_USDT 0;
BA_ "GenSigTimeoutMsg_HU_Mid_X451" SG_ 1882 EPAS_DiagResponse_USDT 0;
BA_ "GenSigTimeoutMsg_HU_High_X451" SG_ 1882 EPAS_DiagResponse_USDT 0;
BA_ "GenSigTimeoutMsg_HU_B" SG_ 1882 EPAS_DiagResponse_USDT 0;
BA_ "GenSigTimeoutMsg_HU_A" SG_ 1882 EPAS_DiagResponse_USDT 0;
BA_ "GenSigSendType" SG_ 1882 EPAS_DiagResponse_USDT 1;
BA_ "GenSigTimeoutMsg_HU_High_X445" SG_ 1882 EPAS_DiagResponse_USDT 0;
BA_ "GenSigTimeoutMsg_HU_Mid_X445" SG_ 1882 EPAS_DiagResponse_USDT 0;
BA_ "GenSigTimeoutTime_HU_High_X445" SG_ 1882 EPAS_DiagResponse_USDT 0;
BA_ "GenSigTimeoutTime_HU_Mid_X445" SG_ 1882 EPAS_DiagResponse_USDT 0;
BA_ "GenSigTimeoutMsg_IVI" SG_ 1882 EPAS_DiagResponse_USDT 0;
BA_ "GenSigTimeoutTime_IVI" SG_ 1882 EPAS_DiagResponse_USDT 0;
BA_ "GenSigTimeoutTime_HU_Mid_X451" SG_ 1884 ESCL_DiagResponse_USDT 0;
BA_ "GenSigTimeoutTime_HU_High_X451" SG_ 1884 ESCL_DiagResponse_USDT 0;
BA_ "GenSigTimeoutTime_HU_B" SG_ 1884 ESCL_DiagResponse_USDT 0;
BA_ "GenSigTimeoutTime_HU_A" SG_ 1884 ESCL_DiagResponse_USDT 0;
BA_ "GenSigTimeoutMsg_HU_Mid_X451" SG_ 1884 ESCL_DiagResponse_USDT 0;
BA_ "GenSigTimeoutMsg_HU_High_X451" SG_ 1884 ESCL_DiagResponse_USDT 0;
BA_ "GenSigTimeoutMsg_HU_B" SG_ 1884 ESCL_DiagResponse_USDT 0;
BA_ "GenSigTimeoutMsg_HU_A" SG_ 1884 ESCL_DiagResponse_USDT 0;
BA_ "GenSigSendType" SG_ 1884 ESCL_DiagResponse_USDT 1;
BA_ "GenSigTimeoutMsg_HU_High_X445" SG_ 1884 ESCL_DiagResponse_USDT 0;
BA_ "GenSigTimeoutMsg_HU_Mid_X445" SG_ 1884 ESCL_DiagResponse_USDT 0;
BA_ "GenSigTimeoutTime_HU_High_X445" SG_ 1884 ESCL_DiagResponse_USDT 0;
BA_ "GenSigTimeoutTime_HU_Mid_X445" SG_ 1884 ESCL_DiagResponse_USDT 0;
BA_ "GenSigTimeoutMsg_IVI" SG_ 1884 ESCL_DiagResponse_USDT 0;
BA_ "GenSigTimeoutTime_IVI" SG_ 1884 ESCL_DiagResponse_USDT 0;
BA_ "GenSigTimeoutTime_HU_Mid_X451" SG_ 2000 DiagMsg 0;
BA_ "GenSigTimeoutTime_HU_High_X451" SG_ 2000 DiagMsg 0;
BA_ "GenSigTimeoutTime_HU_B" SG_ 2000 DiagMsg 0;
BA_ "GenSigTimeoutTime_HU_A" SG_ 2000 DiagMsg 0;
BA_ "GenSigTimeoutMsg_HU_Mid_X451" SG_ 2000 DiagMsg 0;
BA_ "GenSigTimeoutMsg_HU_High_X451" SG_ 2000 DiagMsg 0;
BA_ "GenSigTimeoutMsg_HU_B" SG_ 2000 DiagMsg 0;
BA_ "GenSigTimeoutMsg_HU_A" SG_ 2000 DiagMsg 0;
BA_ "GenSigSendType" SG_ 2000 DiagMsg 1;
BA_ "GenSigTimeoutMsg_HU_High_X445" SG_ 2000 DiagMsg 0;
BA_ "GenSigTimeoutMsg_HU_Mid_X445" SG_ 2000 DiagMsg 0;
BA_ "GenSigTimeoutTime_HU_High_X445" SG_ 2000 DiagMsg 0;
BA_ "GenSigTimeoutTime_HU_Mid_X445" SG_ 2000 DiagMsg 0;
BA_ "GenSigTimeoutMsg_IVI" SG_ 2000 DiagMsg 0;
BA_ "GenSigTimeoutTime_IVI" SG_ 2000 DiagMsg 0;
BA_ "GenSigTimeoutTime_HU_Mid_X451" SG_ 2001 DiagMsg 0;
BA_ "GenSigTimeoutTime_HU_High_X451" SG_ 2001 DiagMsg 0;
BA_ "GenSigTimeoutTime_HU_B" SG_ 2001 DiagMsg 0;
BA_ "GenSigTimeoutTime_HU_A" SG_ 2001 DiagMsg 0;
BA_ "GenSigTimeoutMsg_HU_Mid_X451" SG_ 2001 DiagMsg 0;
BA_ "GenSigTimeoutMsg_HU_High_X451" SG_ 2001 DiagMsg 0;
BA_ "GenSigTimeoutMsg_HU_B" SG_ 2001 DiagMsg 0;
BA_ "GenSigTimeoutMsg_HU_A" SG_ 2001 DiagMsg 0;
BA_ "GenSigSendType" SG_ 2001 DiagMsg 1;
BA_ "GenSigTimeoutMsg_HU_High_X445" SG_ 2001 DiagMsg 0;
BA_ "GenSigTimeoutMsg_HU_Mid_X445" SG_ 2001 DiagMsg 0;
BA_ "GenSigTimeoutTime_HU_High_X445" SG_ 2001 DiagMsg 0;
BA_ "GenSigTimeoutTime_HU_Mid_X445" SG_ 2001 DiagMsg 0;
BA_ "GenSigTimeoutMsg_IVI" SG_ 2001 DiagMsg 0;
BA_ "GenSigTimeoutTime_IVI" SG_ 2001 DiagMsg 0;
BA_ "GenSigTimeoutTime_HU_Mid_X451" SG_ 2015 DiagMsg 0;
BA_ "GenSigTimeoutTime_HU_High_X451" SG_ 2015 DiagMsg 0;
BA_ "GenSigTimeoutTime_HU_B" SG_ 2015 DiagMsg 0;
BA_ "GenSigTimeoutTime_HU_A" SG_ 2015 DiagMsg 0;
BA_ "GenSigTimeoutMsg_HU_Mid_X451" SG_ 2015 DiagMsg 0;
BA_ "GenSigTimeoutMsg_HU_High_X451" SG_ 2015 DiagMsg 0;
BA_ "GenSigTimeoutMsg_HU_B" SG_ 2015 DiagMsg 0;
BA_ "GenSigTimeoutMsg_HU_A" SG_ 2015 DiagMsg 0;
BA_ "GenSigSendType" SG_ 2015 DiagMsg 1;
BA_ "GenSigTimeoutMsg_HU_High_X445" SG_ 2015 DiagMsg 0;
BA_ "GenSigTimeoutMsg_HU_Mid_X445" SG_ 2015 DiagMsg 0;
BA_ "GenSigTimeoutTime_HU_High_X445" SG_ 2015 DiagMsg 0;
BA_ "GenSigTimeoutTime_HU_Mid_X445" SG_ 2015 DiagMsg 0;
BA_ "GenSigTimeoutMsg_IVI" SG_ 2015 DiagMsg 0;
BA_ "GenSigTimeoutTime_IVI" SG_ 2015 DiagMsg 0;
BA_ "GenSigTimeoutTime_HU_Mid_X451" SG_ 2016 EMS_DiagRequest 0;
BA_ "GenSigTimeoutTime_HU_High_X451" SG_ 2016 EMS_DiagRequest 0;
BA_ "GenSigTimeoutTime_HU_B" SG_ 2016 EMS_DiagRequest 0;
BA_ "GenSigTimeoutTime_HU_A" SG_ 2016 EMS_DiagRequest 0;
BA_ "GenSigTimeoutMsg_HU_Mid_X451" SG_ 2016 EMS_DiagRequest 0;
BA_ "GenSigTimeoutMsg_HU_High_X451" SG_ 2016 EMS_DiagRequest 0;
BA_ "GenSigTimeoutMsg_HU_B" SG_ 2016 EMS_DiagRequest 0;
BA_ "GenSigTimeoutMsg_HU_A" SG_ 2016 EMS_DiagRequest 0;
BA_ "GenSigSendType" SG_ 2016 EMS_DiagRequest 1;
BA_ "GenSigTimeoutMsg_HU_High_X445" SG_ 2016 EMS_DiagRequest 0;
BA_ "GenSigTimeoutMsg_HU_Mid_X445" SG_ 2016 EMS_DiagRequest 0;
BA_ "GenSigTimeoutTime_HU_High_X445" SG_ 2016 EMS_DiagRequest 0;
BA_ "GenSigTimeoutTime_HU_Mid_X445" SG_ 2016 EMS_DiagRequest 0;
BA_ "GenSigTimeoutMsg_IVI" SG_ 2016 EMS_DiagRequest 0;
BA_ "GenSigTimeoutTime_IVI" SG_ 2016 EMS_DiagRequest 0;
BA_ "GenSigTimeoutTime_HU_Mid_X451" SG_ 2017 AMT_DCT_DiagRequest 0;
BA_ "GenSigTimeoutTime_HU_High_X451" SG_ 2017 AMT_DCT_DiagRequest 0;
BA_ "GenSigTimeoutTime_HU_B" SG_ 2017 AMT_DCT_DiagRequest 0;
BA_ "GenSigTimeoutTime_HU_A" SG_ 2017 AMT_DCT_DiagRequest 0;
BA_ "GenSigTimeoutMsg_HU_Mid_X451" SG_ 2017 AMT_DCT_DiagRequest 0;
BA_ "GenSigTimeoutMsg_HU_High_X451" SG_ 2017 AMT_DCT_DiagRequest 0;
BA_ "GenSigTimeoutMsg_HU_B" SG_ 2017 AMT_DCT_DiagRequest 0;
BA_ "GenSigTimeoutMsg_HU_A" SG_ 2017 AMT_DCT_DiagRequest 0;
BA_ "GenSigSendType" SG_ 2017 AMT_DCT_DiagRequest 1;
BA_ "GenSigTimeoutMsg_HU_High_X445" SG_ 2017 AMT_DCT_DiagRequest 0;
BA_ "GenSigTimeoutMsg_HU_Mid_X445" SG_ 2017 AMT_DCT_DiagRequest 0;
BA_ "GenSigTimeoutTime_HU_High_X445" SG_ 2017 AMT_DCT_DiagRequest 0;
BA_ "GenSigTimeoutTime_HU_Mid_X445" SG_ 2017 AMT_DCT_DiagRequest 0;
BA_ "GenSigTimeoutMsg_IVI" SG_ 2017 AMT_DCT_DiagRequest 0;
BA_ "GenSigTimeoutTime_IVI" SG_ 2017 AMT_DCT_DiagRequest 0;
BA_ "GenSigTimeoutTime_HU_Mid_X451" SG_ 2024 EMS_DiagResponse_USDT 0;
BA_ "GenSigTimeoutTime_HU_High_X451" SG_ 2024 EMS_DiagResponse_USDT 0;
BA_ "GenSigTimeoutTime_HU_B" SG_ 2024 EMS_DiagResponse_USDT 0;
BA_ "GenSigTimeoutTime_HU_A" SG_ 2024 EMS_DiagResponse_USDT 0;
BA_ "GenSigTimeoutMsg_HU_Mid_X451" SG_ 2024 EMS_DiagResponse_USDT 0;
BA_ "GenSigTimeoutMsg_HU_High_X451" SG_ 2024 EMS_DiagResponse_USDT 0;
BA_ "GenSigTimeoutMsg_HU_B" SG_ 2024 EMS_DiagResponse_USDT 0;
BA_ "GenSigTimeoutMsg_HU_A" SG_ 2024 EMS_DiagResponse_USDT 0;
BA_ "GenSigSendType" SG_ 2024 EMS_DiagResponse_USDT 1;
BA_ "GenSigTimeoutMsg_HU_High_X445" SG_ 2024 EMS_DiagResponse_USDT 0;
BA_ "GenSigTimeoutMsg_HU_Mid_X445" SG_ 2024 EMS_DiagResponse_USDT 0;
BA_ "GenSigTimeoutTime_HU_High_X445" SG_ 2024 EMS_DiagResponse_USDT 0;
BA_ "GenSigTimeoutTime_HU_Mid_X445" SG_ 2024 EMS_DiagResponse_USDT 0;
BA_ "GenSigTimeoutMsg_IVI" SG_ 2024 EMS_DiagResponse_USDT 0;
BA_ "GenSigTimeoutTime_IVI" SG_ 2024 EMS_DiagResponse_USDT 0;
BA_ "GenSigTimeoutTime_HU_Mid_X451" SG_ 2025 AMT_DCT_DiagResponse_USDT 0;
BA_ "GenSigTimeoutTime_HU_High_X451" SG_ 2025 AMT_DCT_DiagResponse_USDT 0;
BA_ "GenSigTimeoutTime_HU_B" SG_ 2025 AMT_DCT_DiagResponse_USDT 0;
BA_ "GenSigTimeoutTime_HU_A" SG_ 2025 AMT_DCT_DiagResponse_USDT 0;
BA_ "GenSigTimeoutMsg_HU_Mid_X451" SG_ 2025 AMT_DCT_DiagResponse_USDT 0;
BA_ "GenSigTimeoutMsg_HU_High_X451" SG_ 2025 AMT_DCT_DiagResponse_USDT 0;
BA_ "GenSigTimeoutMsg_HU_B" SG_ 2025 AMT_DCT_DiagResponse_USDT 0;
BA_ "GenSigTimeoutMsg_HU_A" SG_ 2025 AMT_DCT_DiagResponse_USDT 0;
BA_ "GenSigSendType" SG_ 2025 AMT_DCT_DiagResponse_USDT 1;
BA_ "GenSigTimeoutMsg_HU_High_X445" SG_ 2025 AMT_DCT_DiagResponse_USDT 0;
BA_ "GenSigTimeoutMsg_HU_Mid_X445" SG_ 2025 AMT_DCT_DiagResponse_USDT 0;
BA_ "GenSigTimeoutTime_HU_High_X445" SG_ 2025 AMT_DCT_DiagResponse_USDT 0;
BA_ "GenSigTimeoutTime_HU_Mid_X445" SG_ 2025 AMT_DCT_DiagResponse_USDT 0;
BA_ "GenSigTimeoutMsg_IVI" SG_ 2025 AMT_DCT_DiagResponse_USDT 0;
BA_ "GenSigTimeoutTime_IVI" SG_ 2025 AMT_DCT_DiagResponse_USDT 0;
VAL_ 1182 ESCL_EP_failure 3 "Reserved" 2 "Failure healed Ageing in progress" 1 "Failure matured & DTC in memory" 0 "Failure is not detected" ;
VAL_ 1182 ESCL_BO_failure 3 "Reserved" 2 "Failure healed Ageing in progress" 1 "Failure matured & DTC in memory" 0 "Failure is not detected" ;
VAL_ 1182 PEPS_Invalid_failure_status 3 "Reserved" 2 "Failure healed Ageing in progress" 1 "Failure matured & DTC in memory" 0 "Failure is not detected" ;
VAL_ 1182 PEPS_MTO_Failure_Status 3 "Reserved" 2 "Failure healed aging in progress" 1 "Failure detected DTC in Memory" 0 "Failure is not detected" ;
VAL_ 1182 EMsInvalidFailureStatus 3 "Reserved" 2 "Failure healed Ageing in progress" 1 "Failure matured & DTC in memory" 0 "Failure is not detected" ;
VAL_ 1182 EMsMToFailureStatus 3 "Historic DTC" 2 "Failurehealed Ageing in progress" 1 "Failure matured & DTC in memory" 0 "Faiulure is not detected " ;
VAL_ 1182 ESP_CRC_failure_status 3 "Reserved" 2 "Failure healed Ageing in progress" 1 "Failure matured & DTC in memory" 0 "Failure is not detected" ;
VAL_ 1182 ESP_MRC_Failure_status 3 "Reserved" 2 "Failure healed Ageing in progress" 1 "Failure matured & DTC in memory" 0 "Failure is not detected" ;
VAL_ 1182 ESpInvalidFailureStatus 3 "Reserved" 2 "Failure healed ageing in progress" 1 "fail detected and DTC  in memory" 0 "failure not detected" ;
VAL_ 1182 ESpMToFailureStatus 3 "Reserved" 2 "Failure healed aging in progress" 1 "Failrue detected DTC in memory" 0 "Failure is not detected" ;
VAL_ 1182 BCmInvalidFailureStatus 3 "Reserved" 2 "Failure healed Ageing in progress" 1 "Failure matured & DTC in memory" 0 "Failure is not detected" ;
VAL_ 1182 BCmMToFailureStatus 3 "Reserved" 2 "Failure healed aging in progress" 1 "Failure detected; DTC in memory" 0 "Failrue is not detected" ;
VAL_ 1183 SAS_MTO_Failure_Status 3 "Reserved" 2 "Failure healed aging in progress" 1 "Failure detected; DTC in memory" 0 "Failure is not detected" ;
VAL_ 1183 ESpMToFailureStatus 3 "Reserved" 2 "Failure healed aging in progress" 1 "Failrue detected DTC in memory" 0 "Failure is not detected" ;
VAL_ 1183 TPMS_EP_Failure_Status 3 "Reserved" 2 "Failure healed Ageing in progress" 1 "Failure matured & DTC in memory" 0 "Failure is not detected" ;
VAL_ 1183 IPC_Invalid_Failure_Status 3 "Reserved" 2 "Failure healed Ageing in progress" 1 "Failure matured & DTC in memory" 0 "Failure is not detected" ;
VAL_ 1183 IPC_MTO_Failure_Status 3 "Reserved" 2 "Failure healed Ageing in progress" 1 "Failure matured & DTC in memory" 0 "Failure is not detected" ;
VAL_ 1183 TPMS_BO_Failure_Status 3 "Reserved" 2 "Failure healed Ageing in progress" 1 "Failure matured & DTC in memory" 0 "Failure is not detected" ;
VAL_ 1266 DrvOverrideState 1 "Active" 0 "Not_active" ;
VAL_ 1266 RegntWarnQultyReq 15 "Signal Not available" 14 "Reserved" 13 "Reserved" 12 "Reserved" 11 "Reserved" 10 "Reserved" 9 "Reserved" 8 "Reserved" 7 "Reagent Warning Level 7" 6 "Reagent Warning Level 6" 5 "Reagent Warning Level 5" 4 "Reagent Warning Level 4" 3 "Reagent Warning Level 3" 2 "Reagent Warning Level 2" 1 "Reagent Warning Level 1" 0 "Reagent Level OK" ;
VAL_ 1266 RegntWrngConsReq 15 "Signal Not available" 14 "Reserved" 13 "Reserved" 12 "Reserved" 11 "Reserved" 10 "Reserved" 9 "Reserved" 8 "Reserved" 7 "Reagent Warning Level 7" 6 "Reagent Warning Level 6" 5 "Reagent Warning Level 5" 4 "Reagent Warning Level 4" 3 "Reagent Warning Level 3" 2 "Reagent Warning Level 2" 1 "Reagent Warning Level 1" 0 "Reagent Level OK" ;
VAL_ 1266 ScrSystemFault 1 "Fault present ON SCR system" 0 "No fault present on SCR system" ;
VAL_ 1266 LowRegntWrngLvlReq 15 "Signal Not available" 14 "Reserved" 13 "Reserved" 12 "Reserved" 11 "Reserved" 10 "Reserved" 9 "Reserved" 8 "Reserved" 7 "Reagent Warning Level 7" 6 "Reagent Warning Level 6" 5 "Reagent Warning Level 5" 4 "Reagent Warning Level 4" 3 "Reagent Warning Level 3" 2 "Reagent Warning Level 2" 1 "Reagent Warning Level 1" 0 "Reagent Level OK" ;
VAL_ 1274 GlobalRealTimeGS 16777215 "Signal not available" ;
VAL_ 1274 OdoICFullSigGS 16777215 "Signal not available" ;
VAL_ 1274 BatVoltGS 255 "Signal nlot available" ;
VAL_ 1274 VehicleInteriorTempGS 255 "Signal not available" ;
VAL_ 1276 EngSpdGS 65535 "Signal not available" ;
VAL_ 1276 AccPedPosnGS 255 "Signal not available" ;
VAL_ 1276 ClntTempGS 255 "Signal not available" ;
VAL_ 1276 VehSpdGS 255 "Signal not available" ;
VAL_ 1276 OATICSigGS 255 "Signal not available" ;
VAL_ 1276 PowerModeStateGS 15 "Signal not available" 14 "Reserved" 13 "Reserved" 12 "Reserved" 11 "Tranpoer Drive Run" 10 "Transport Drive Crank" 9 "Start(Crank)" 8 "Run(Engine Run)" 7 "Transport Drive" 6 "Active(Ignition ON)" 5 "Accessory Delay" 4 "Accessory" 3 "KeyIn" 2 "Transport Park" 1 "Awake" 0 "Pre Stand By" ;
VAL_ 1276 ParkBrkStateGS 1 "Park Brake is ON" 0 "Park Brake is Off" ;
VAL_ 1280 RepeatMessageReq_BCM 1 "Repeat message state requested" 0 "Repeat message state not requested" ;
VAL_ 1280 ActiveWakeUp_BCM 1 "Node has  woken up the network(Active wakeup)" 0 "Node has not woken up the network(Passive wakeup)" ;
VAL_ 1280 CurrentState_BCM 1 "Normal Operation State" 0 "Repeat Messgae State" ;
VAL_ 1280 PreviousState_BCM 7 "Reserved" 6 "Reserved" 5 "Reserved" 4 " Bus Sleep State" 3 "Prepare Bus Sleep State" 2 "Ready Sleep State" 1 "Normal Operation State" 0 "Repeat Message State" ;
VAL_ 1281 RepeatMessageReq_IPC 1 "Reserved" 0 "Repeat message state not requested" ;
VAL_ 1281 ActiveWakeUp_IPC 1 "Node has woken up the network(Active Wakeup)" 0 "Node has not woken up the network(Passive Wakeup)" ;
VAL_ 1281 CurrentState_IPC 1 "Normal Operation State" 0 "Repeat Messgae State" ;
VAL_ 1281 PreviousState 7 "Reserved" 6 "Reserved" 5 "Reserved" 4 "Bus Sleep State" 3 "Prepare Bus Sleep State" 2 "Ready Sleep State" 1 "Normal Operation State" 0 "Repeat Message State" ;
VAL_ 1282 RepeatMessageReq_HU 1 "Reserved" 0 "Repeat Message State not requested" ;
VAL_ 1282 ActiveWakeUp_HU 1 "Node has  woken up the network(Active wakeup)" 0 "Node has not woken up the network(Passive wakeup)" ;
VAL_ 1282 CurrentState_HU 1 "Normal Operation State" 0 "Repeat Messgae State" ;
VAL_ 1282 PreviousState_HU 7 "Copy of Reserved" 6 "Reserved" 5 "Reserved" 4 "Bus Sleep State" 3 "Prepare Bus Sleep State" 2 "Ready Sleep State" 1 "Normal Operation State" 0 "Repeat Message State" ;
VAL_ 1285 RepeatMessageReq_GSS 1 "Reserved" 0 "Repeat message state not requested" ;
VAL_ 1285 ActiveWakeUp_GSS 1 "Node has  woken up the network(Active wakeup)" 0 "Node has not woken up the network(Passive wakeup)" ;
VAL_ 1285 CurrentState_GSS 1 "Normal Operation State" 0 "Repeat Messgae State" ;
VAL_ 1285 PreviousState_GSS 7 "Copy of Reserved" 6 "Reserved(" 5 "Reserved" 4 "Bus Sleep State" 3 "Prepare Bus Sleep State" 2 "Ready Sleep State" 1 "Normal Operation State" 0 "Repeat Message State" ;
VAL_ 1286 RepeatMessageReq_CCM 1 "Reserved" 0 "Repeat message state not requested" ;
VAL_ 1286 ActiveWakeUp_CCM 1 "Node has  woken up the network(Active wakeup)" 0 "Node has not woken up the network(Passive wakeup)" ;
VAL_ 1286 CurrentState_CCM 1 "Normal Operation State" 0 "Repeat Messgae State" ;
VAL_ 1286 PreviousState_CCM 7 "Reserved" 6 " Reserved" 5 "Reserved" 4 "Bus Sleep State" 3 "Prepare Bus Sleep State" 2 "Ready Sleep State" 1 "Normal Operation State" 0 "Repeat Message State" ;
